VERSION ""

NS_ :

BS_:

BU_: VCM FAS EBS APM

BO_ 592 EBS_CpbtyAxle123_C03: 64 EBS
 SG_ CpbtyAxle3_BrkEgyCpctyQltyLe : 340|2@1+ (1,0) [0|0] ""  VCM
 SG_ CpbtyAxle3_TqCpbtyRateIncLeLe : 360|8@1+ (1000,0) [0|255000] "NotApplicable"  VCM
 SG_ CpbtyAxle3_TqCpbtyRateQltyRi : 438|2@1+ (1,0) [0|0] ""  VCM
 SG_ CpbtyAxle1_PadWearQltyLe : 32|2@1+ (1,0) [0|0] ""  VCM
 SG_ CpbtyAxle1_SlipCtrlEna : 144|2@1+ (1,0) [0|0] ""  VCM
 SG_ CpbtyAxle2_PadWearRi : 232|8@1+ (0.5,0) [0|127.5] "Percent"  VCM
 SG_ CpbtyAxle3_TqCpbtyRateQltyLe : 436|2@1+ (1,0) [0|0] ""  VCM
 SG_ CpbtyAxle1_BrkEgyCpctyQltyRi : 38|2@1+ (1,0) [0|0] ""  VCM
 SG_ CpbtyAxle2_TqCpbtyMaxRi : 274|10@1+ (50,0) [0|51150] "Nm"  VCM
 SG_ CpbtyAxle2_TqCpbtyMinLe : 240|10@1+ (50,0) [0|51150] "Nm"  VCM
 SG_ CpbtyAxle2_BrkEgyCpctyQltyLe : 188|2@1+ (1,0) [0|0] ""  VCM
 SG_ CpbtyAxle2_TqCpbtyRateDecLe : 192|8@1+ (1000,0) [0|255000] "NotApplicable"  VCM
 SG_ CpbtyAxle3_SlipCtrlEna : 448|2@1+ (1,0) [0|0] ""  VCM
 SG_ CpbtyAxle3_TqCpbtyQltyLe : 402|2@1+ (1,0) [0|0] ""  VCM
 SG_ CpbtyAxle3_BrkEgyCpctyRi : 328|8@1+ (150,0) [0|38250] "NotApplicable"  VCM
 SG_ CpbtyAxle1_SqC : 16|8@1+ (1,0) [0|255] "Count"  VCM
 SG_ CpbtyAxle1_TqCpbtyQltyLe : 98|2@1+ (1,0) [0|0] ""  VCM
 SG_ CpbtyAxle2_TqCpbtyRateDecRi : 216|8@1+ (1000,0) [0|255000] "NotApplicable"  VCM
 SG_ CpbtyAxle1_TqCpbtyRateIncLeLe : 56|8@1+ (1000,0) [0|255000] "NotApplicable"  VCM
 SG_ CpbtyAxle3_BrkEgyCpctyQltyRi : 342|2@1+ (1,0) [0|0] ""  VCM
 SG_ CpbtyAxle3_TqCpbtyRateDecLe : 344|8@1+ (1000,0) [0|255000] "NotApplicable"  VCM
 SG_ CpbtyAxle3_TqCpbtyRateDecRi : 368|8@1+ (1000,0) [0|255000] "NotApplicable"  VCM
 SG_ CpbtyAxle1_PadWearRi : 80|8@1+ (0.5,0) [0|127.5] "Percent"  VCM
 SG_ CpbtyAxle2_TqCpbtyMaxLe : 262|10@1+ (50,0) [0|51150] "Nm"  VCM
 SG_ CpbtyAxle3_TqCpbtyQltyRi : 424|2@1+ (1,0) [0|0] ""  VCM
 SG_ CpbtyAxle1_TqCpbtyRateDecLe : 40|8@1+ (1000,0) [0|255000] "NotApplicable"  VCM
 SG_ CpbtyAxle1_BrkEgyCpctyRi : 24|8@1+ (150,0) [0|38250] "NotApplicable"  VCM
 SG_ CpbtyAxle3_TqCpbtyMinLe : 392|10@1+ (50,0) [0|51150] "Nm"  VCM
 SG_ CpbtyAxle3_TqCpbtyMinRi : 404|10@1+ (50,0) [0|51150] "Nm"  VCM
 SG_ CpbtyAxle2_BrkEgyCpctyQltyRi : 190|2@1+ (1,0) [0|0] ""  VCM
 SG_ CpbtyAxle2_PadWearLe : 224|8@1+ (0.5,0) [0|127.5] "Percent"  VCM
 SG_ CpbtyAxle2_TqCpbtyQltyRi : 272|2@1+ (1,0) [0|0] ""  VCM
 SG_ CpbtyAxle2_PadWearQltyRi : 186|2@1+ (1,0) [0|0] ""  VCM
 SG_ CpbtyAxle3_PadWearRi : 384|8@1+ (0.5,0) [0|127.5] "Percent"  VCM
 SG_ CpbtyAxle3_PadWearQltyRi : 338|2@1+ (1,0) [0|0] ""  VCM
 SG_ CpbtyAxle1_TqCpbtyMaxRi : 122|10@1+ (50,0) [0|51150] "Nm"  VCM
 SG_ CpbtyAxle2_TqCpbtyRateQltyRi : 286|2@1+ (1,0) [0|0] ""  VCM
 SG_ CpbtyAxle1_BrkEgyCpctyLe : 136|8@1+ (150,0) [0|38250] "NotApplicable"  VCM
 SG_ CpbtyAxle2_SlipCtrlEna : 296|2@1+ (1,0) [0|0] ""  VCM
 SG_ CpbtyAxle1_TqCpbtyRateIncLeRi : 48|8@1+ (1000,0) [0|255000] "NotApplicable"  VCM
 SG_ CpbtyAxle2_TqCpbtyMinRi : 252|10@1+ (50,0) [0|51150] "Nm"  VCM
 SG_ CpbtyAxle3_TqCpbtyMaxLe : 414|10@1+ (50,0) [0|51150] "Nm"  VCM
 SG_ CpbtyAxle1_TqCpbtyRateQltyRi : 134|2@1+ (1,0) [0|0] ""  VCM
 SG_ CpbtyAxle1_CRC : 0|16@1+ (1,0) [0|65535] "NotApplicable"  VCM
 SG_ CpbtyAxle1_PadWearQltyRi : 34|2@1+ (1,0) [0|0] ""  VCM
 SG_ CpbtyAxle2_CRC : 152|16@1+ (1,0) [0|65535] "NotApplicable"  VCM
 SG_ CpbtyAxle2_SqC : 168|8@1+ (1,0) [0|255] "Count"  VCM
 SG_ CpbtyAxle2_TqCpbtyRateIncLeLe : 208|8@1+ (1000,0) [0|255000] "NotApplicable"  VCM
 SG_ CpbtyAxle2_TqCpbtyRateIncLeRi : 200|8@1+ (1000,0) [0|255000] "NotApplicable"  VCM
 SG_ CpbtyAxle2_BrkEgyCpctyLe : 288|8@1+ (150,0) [0|38250] "NotApplicable"  VCM
 SG_ CpbtyAxle1_TqCpbtyRateDecRi : 64|8@1+ (1000,0) [0|255000] "NotApplicable"  VCM
 SG_ CpbtyAxle3_TqCpbtyMaxRi : 426|10@1+ (50,0) [0|51150] "Nm"  VCM
 SG_ CpbtyAxle3_PadWearQltyLe : 336|2@1+ (1,0) [0|0] ""  VCM
 SG_ CpbtyAxle3_PadWearLe : 376|8@1+ (0.5,0) [0|127.5] "Percent"  VCM
 SG_ CpbtyAxle1_TqCpbtyRateQltyLe : 132|2@1+ (1,0) [0|0] ""  VCM
 SG_ CpbtyAxle1_PadWearLe : 72|8@1+ (0.5,0) [0|127.5] "Percent"  VCM
 SG_ CpbtyAxle1_TqCpbtyMinRi : 100|10@1+ (50,0) [0|51150] "Nm"  VCM
 SG_ CpbtyAxle1_TqCpbtyQltyRi : 120|2@1+ (1,0) [0|0] ""  VCM
 SG_ CpbtyAxle3_BrkEgyCpctyLe : 440|8@1+ (150,0) [0|38250] "NotApplicable"  VCM
 SG_ CpbtyAxle3_TqCpbtyRateIncLeRi : 352|8@1+ (1000,0) [0|255000] "NotApplicable"  VCM
 SG_ CpbtyAxle1_TqCpbtyMinLe : 88|10@1+ (50,0) [0|51150] "Nm"  VCM
 SG_ CpbtyAxle2_TqCpbtyQltyLe : 250|2@1+ (1,0) [0|0] ""  VCM
 SG_ CpbtyAxle2_TqCpbtyRateQltyLe : 284|2@1+ (1,0) [0|0] ""  VCM
 SG_ CpbtyAxle2_BrkEgyCpctyRi : 176|8@1+ (150,0) [0|38250] "NotApplicable"  VCM
 SG_ CpbtyAxle1_BrkEgyCpctyQltyLe : 36|2@1+ (1,0) [0|0] ""  VCM
 SG_ CpbtyAxle2_PadWearQltyLe : 184|2@1+ (1,0) [0|0] ""  VCM
 SG_ CpbtyAxle1_TqCpbtyMaxLe : 110|10@1+ (50,0) [0|51150] "Nm"  VCM
 SG_ CpbtyAxle3_CRC : 304|16@1+ (1,0) [0|65535] "NotApplicable"  VCM
 SG_ CpbtyAxle3_SqC : 320|8@1+ (1,0) [0|255] "Count"  VCM

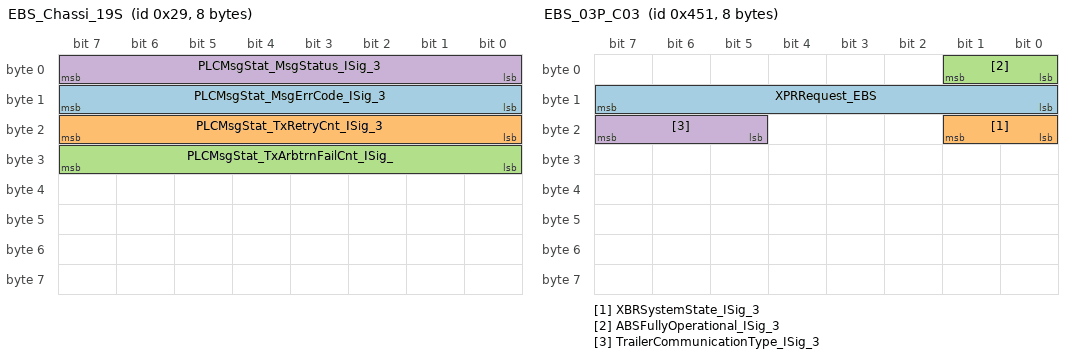
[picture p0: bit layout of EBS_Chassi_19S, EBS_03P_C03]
BO_ 41 EBS_Chassi_19S: 8 EBS
 SG_ PLCMsgStat_MsgErrCode_ISig_3 : 8|8@1+ (1,0) [0|255] "NotApplicable"  VCM
 SG_ PLCMsgStat_TxRetryCnt_ISig_3 : 16|8@1+ (1,0) [0|255] "NotApplicable"  VCM
 SG_ PLCMsgStat_TxArbtrnFailCnt_ISig_ : 24|8@1+ (1,0) [0|255] "NotApplicable"  VCM
 SG_ PLCMsgStat_MsgStatus_ISig_3 : 0|8@1+ (1,0) [0|255] "NotApplicable"  VCM

BO_ 1505 EBS_Chassi_18S: 24 EBS
 SG_ PhyDiagBrk2TPMReqSig_ISig_3 : 0|168@1+ (1,0) [0|0] ""  VCM

BO_ 296 EBS_06P_C03: 8 EBS
 SG_ FrontAxleSpeed_ISig_3 : 0|16@1+ (0.00390625,0) [0|255.99609375] "Km_per_h"  APM

BO_ 832 EBS_05P_C03: 16 EBS
 SG_ WhlSpdSenTothCnt456_TimeStamp_IS : 112|16@1+ (1,0) [0|65535] ""  VCM
 SG_ WhlSpdSenTothCnt456_Axle6Right_I : 104|8@1+ (1,0) [0|255] "Count"  VCM
 SG_ WhlSpdSenTothCnt456_Axle5Left_IS : 80|8@1+ (1,0) [0|255] "Count"  VCM
 SG_ WhlSpdSenTothCnt456_Axle4Right_I : 72|8@1+ (1,0) [0|255] "Count"  VCM
 SG_ WhlSpdSenTothCnt456_Axle5Right_I : 88|8@1+ (1,0) [0|255] "Count"  VCM
 SG_ WhlSpdSenTothCnt123_Axle2Left_IS : 16|8@1+ (1,0) [0|255] "Count"  VCM
 SG_ WhlSpdSenTothCnt123_TimeStamp_IS : 48|16@1+ (1,0) [0|65535] ""  VCM
 SG_ WhlSpdSenTothCnt456_Axle4Left_IS : 64|8@1+ (1,0) [0|255] "Count"  VCM
 SG_ WhlSpdSenTothCnt123_Axle3Left_IS : 32|8@1+ (1,0) [0|255] "Count"  VCM
 SG_ WhlSpdSenTothCnt123_Axle1Right_I : 8|8@1+ (1,0) [0|255] "Count"  VCM
 SG_ WhlSpdSenTothCnt123_Axle3Right_I : 40|8@1+ (1,0) [0|255] "Count"  VCM
 SG_ WhlSpdSenTothCnt456_Axle6Left_IS : 96|8@1+ (1,0) [0|255] "Count"  VCM
 SG_ WhlSpdSenTothCnt123_Axle2Right_I : 24|8@1+ (1,0) [0|255] "Count"  VCM
 SG_ WhlSpdSenTothCnt123_Axle1Left_IS : 0|8@1+ (1,0) [0|255] "Count"  VCM

BO_ 1507 EBS_04P_C03: 8 EBS
 SG_ PLCBusStatus_ISig_3 : 0|8@1+ (1,0) [0|255] "NotApplicable"  VCM

BO_ 1105 EBS_03P_C03: 8 EBS
 SG_ XPRRequest_EBS : 8|8@1+ (1,0) [0|255] "NotApplicable"  VCM
 SG_ XBRSystemState_ISig_3 : 16|2@1+ (1,0) [0|0] ""  VCM,APM
 SG_ ABSFullyOperational_ISig_3 : 0|2@1+ (1,0) [0|0] ""  APM
 SG_ TrailerCommunicationType_ISig_3 : 21|3@1+ (1,0) [0|0] ""  VCM

BO_ 439 EBS_02P_C03: 48 EBS
 SG_ ABSAxle5Active : 152|2@1+ (1,0) [0|0] ""  VCM,APM
 SG_ EACompound_CRC : 0|8@1+ (1,0) [0|255] ""  VCM,APM
 SG_ RrAxle1RtWhlBrakeApplPrsHiRng : 72|8@1+ (5,0) [0|1275] "kPa"  VCM
 SG_ RrAxle3RtWhlBrakeApplPrsHiRng : 104|8@1+ (5,0) [0|1275] "kPa"  VCM
 SG_ Trailer1TractionHelp_ISig_3 : 218|2@1+ (1,0) [0|0] ""  VCM
 SG_ FrAxleRtWhlBrakeApplPrsHiRng : 56|8@1+ (5,0) [0|1275] "kPa"  VCM
 SG_ EBSBrakeSwitch_ISig_3 : 162|2@1+ (1,0) [0|0] ""  APM,VCM
 SG_ EACompound_SystemState : 12|2@1+ (1,0) [0|0] ""  VCM,APM
 SG_ EBSBrakePedalPosition : 176|8@1+ (0.4,0) [0|102] "Percent"  VCM,APM
 SG_ AntiLockBrakingActive_ISig_3 : 154|2@1+ (1,0) [0|0] ""  FAS,APM,VCM
 SG_ StretchBrake_Stat_ISig_3 : 141|3@1+ (1,0) [0|0] ""  VCM
 SG_ HillHolderMode_ISig_3 : 136|3@1+ (1,0) [0|0] ""  VCM,APM
 SG_ ABSAxle4Active : 150|2@1+ (1,0) [0|0] ""  VCM,APM
 SG_ TrailerBrake_Stat_ISig_3 : 172|2@1+ (1,0) [0|0] ""  VCM
 SG_ CombinedWheelSpeed_CRC : 184|8@1+ (1,0) [0|255] ""  VCM,APM
 SG_ ABSAxle2Active : 146|2@1+ (1,0) [0|0] ""  VCM,APM
 SG_ TrailerEBSAmberWarning_ISig_3 : 174|2@1+ (1,0) [0|0] ""  VCM
 SG_ CombinedWheelSpeed_SqC : 192|4@1+ (1,0) [0|14] "NotApplicable"  VCM,APM
 SG_ ABSAxle1Active : 144|2@1+ (1,0) [0|0] ""  VCM,APM
 SG_ RrAxle2LtWhlBrakeApplPrsHiRng : 80|8@1+ (5,0) [0|1275] "kPa"  VCM
 SG_ ABSAxle3Active : 148|2@1+ (1,0) [0|0] ""  VCM,APM
 SG_ TCMSupply_SqC : 32|4@1+ (1,0) [0|14] "NotApplicable"  VCM,APM
 SG_ PusherLiftAxleLoweringInhibit_IS : 170|2@1+ (1,0) [0|0] ""  VCM
 SG_ CombinedWheelSpeed_Quality : 196|3@1+ (1,0) [0|0] ""  VCM,APM
 SG_ SplitBoxDiffLockActvnFuncReq_ISi : 166|2@1+ (1,0) [0|0] ""  VCM
 SG_ SteerableLiftAxleLoweringInhib : 168|2@1+ (1,0) [0|0] ""  VCM
 SG_ RrAxle3LtWhlBrakeApplPrsHiRng : 96|8@1+ (5,0) [0|1275] "kPa"  VCM
 SG_ EACompound_AppliedRatio : 16|8@1+ (0.004,0) [0|1.02] ""  VCM,APM
 SG_ BrakingSystemPressureLim_rqst_IS : 156|2@1+ (1,0) [0|0] ""  VCM
 SG_ RrAxle1LtWhlBrakeApplPrsHiRng : 64|8@1+ (5,0) [0|1275] "kPa"  VCM
 SG_ EACompound_SqC : 8|4@1+ (1,0) [0|14] "NotApplicable"  APM,VCM
 SG_ TCMSupply_CRC : 24|8@1+ (1,0) [0|255] ""  APM,VCM
 SG_ TrailerControlPressure : 128|8@1+ (5,0) [0|1275] "kPa"  VCM
 SG_ RrAxle2RtWhlBrakeApplPrsHiRng : 88|8@1+ (5,0) [0|1275] "kPa"  VCM
 SG_ ScndRrAxlDiffLckActvnFuncReq_ISi : 164|2@1+ (1,0) [0|0] ""  VCM
 SG_ TCMSupply_TrailerPressure : 40|8@1+ (8,0) [0|2040] "kPa"  VCM,APM
 SG_ CombinedWheelSpeed_Speed : 200|16@1+ (0.00390625,0) [0|255.99609375] "Km_per_h"  APM,VCM
 SG_ HSAState : 139|2@1+ (1,0) [0|0] ""  VCM
 SG_ FrAxleLtWhlBrakeApplPrsHiRng : 48|8@1+ (5,0) [0|1275] "kPa"  VCM

BO_ 315 EBS_01P_C03: 20 EBS
 SG_ FrontAxleLeftWheelSpeed_ISig_3 : 80|16@1+ (0.00390625,0) [0|255.99609375] "Km_per_h"  FAS
 SG_ SteeringWheel_AngleCRC : 16|8@1+ (1,0) [0|255] "NotApplicable"  VCM
 SG_ SteeringWheelTurnCounter : 146|6@1+ (1,-32) [-32|31] "turns"  VCM
 SG_ SteeringWheel_AngleCounter : 24|4@1+ (1,0) [0|15] "NotApplicable"  VCM
 SG_ FrontAxleRightWheelSpeed_ISig_3 : 96|16@1+ (0.00390625,0) [0|255.99609375] "Km_per_h"  FAS
 SG_ LateralAcceleration_ISig_3 : 112|16@1+ (0.00048828125,-15.687) [-15.687|16.31251171875] "m_per_s_squared"  VCM
 SG_ SteeringWheelAngleSensorType : 144|2@1+ (1,0) [0|0] ""  VCM
 SG_ BrakeLightActivationRequest_ISig : 28|2@1+ (1,0) [0|0] ""  VCM
 SG_ SteeringWheel_AngleValue : 0|16@1+ (0.0009765625,-31.374) [-31.374|32.6250234375] "rad"  VCM
 SG_ LongitudinalAcceleration_ISig_3 : 128|16@1+ (0.00048828125,-15.687) [-15.687|16.31251171875] "m_per_s_squared"  VCM
 SG_ SteeringWheelAngle_ISig_3 : 32|16@1+ (0.0009765625,-31.374) [-31.374|32.6250234375] "rad"  VCM,FAS
 SG_ SteeringWheelAngleComp : 48|16@1+ (0.0009765625,-31.374) [-31.374|32.6250234375] "rad"  VCM,FAS
 SG_ YawRate_ISig_3 : 64|16@1+ (0.000122,-3.92) [-3.92|4.07527] "Rad_per_s"  FAS,VCM
 SG_ VDCBrakeLightRequest_ISig_3 : 30|2@1+ (1,0) [0|0] ""  VCM

BO_ 2671964720 DiagUUDTRespMsg1_F2_30_C03: 8 FAS
 SG_ DiagUUDTRespSig_F2_30_ISig_3 : 0|64@1+ (1,0) [0|0] ""  VCM

BO_ 2671964707 DiagUUDTRespMsg1_F2_23_C03: 8 APM
 SG_ DiagUUDTRespSig_F2_23_ISig_3 : 0|64@1+ (1,0) [0|0] ""  VCM

BO_ 2671834160 DiagRespMsgForIntTest_F4_30_C03: 8 FAS
 SG_ InternalTesterDiagSig_F4_30 : 0|64@1+ (1,0) [0|0] ""  VCM

BO_ 2671834147 DiagRespMsgForIntTest_F4_23_C03: 8 APM
 SG_ InternalTesterDiagSig_F4_23 : 0|64@1+ (1,0) [0|0] ""  VCM

BO_ 2671784180 DiagReqMsgOfIntTest_30_F4_C03: 8 VCM
 SG_ InternalTesterDiagSig_30_F4 : 0|64@1+ (1,0) [0|0] ""  FAS

BO_ 2671780852 DiagReqMsgOfIntTest_23_F4_C03: 8 VCM
 SG_ InternalTesterDiagSig_23_F4 : 0|64@1+ (1,0) [0|0] ""  APM

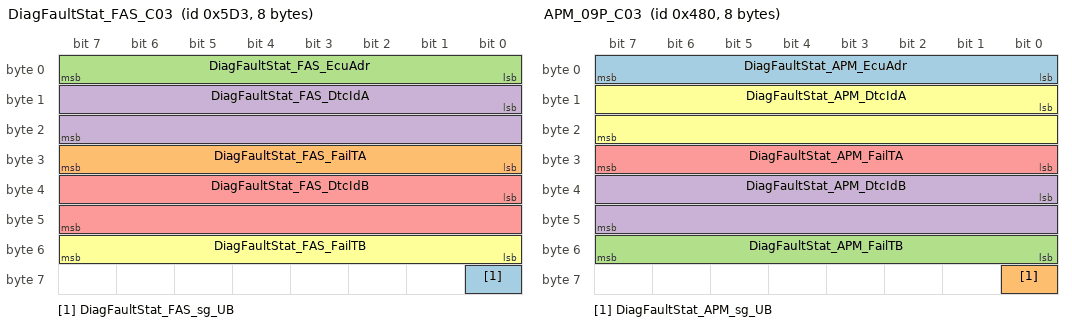
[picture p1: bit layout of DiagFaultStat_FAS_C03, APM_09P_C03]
BO_ 1491 DiagFaultStat_FAS_C03: 8 FAS
 SG_ DiagFaultStat_FAS_sg_UB : 56|1@1+ (1,0) [0|0] ""  VCM
 SG_ DiagFaultStat_FAS_FailTA : 24|8@1+ (1,0) [0|255] ""  VCM
 SG_ DiagFaultStat_FAS_EcuAdr : 0|8@1+ (1,0) [0|255] ""  VCM
 SG_ DiagFaultStat_FAS_DtcIdA : 8|16@1+ (1,0) [0|65535] ""  VCM
 SG_ DiagFaultStat_FAS_DtcIdB : 32|16@1+ (1,0) [0|65535] ""  VCM
 SG_ DiagFaultStat_FAS_FailTB : 48|8@1+ (1,0) [0|255] ""  VCM

BO_ 1954 Debug9_FAS_C03: 8 FAS
 SG_ Debug_9_FAS : 0|64@1+ (1,0) [0|0] "" Vector__XXX

BO_ 1949 Debug8_FAS_C03: 8 Vector__XXX
 SG_ Debug_8_FAS : 0|64@1+ (1,0) [0|0] ""  FAS

BO_ 1944 Debug7_FAS_C03: 8 Vector__XXX
 SG_ Debug_7_FAS : 0|64@1+ (1,0) [0|0] ""  FAS

BO_ 1938 Debug6_FAS_C03: 8 FAS
 SG_ Debug_6_FAS : 0|64@1+ (1,0) [0|0] "" Vector__XXX

BO_ 1930 Debug5_FAS_C03: 8 FAS
 SG_ Debug_5_FAS : 0|64@1+ (1,0) [0|0] "" Vector__XXX

BO_ 1922 Debug4_FAS_C03: 8 FAS
 SG_ Debug_4_FAS : 0|64@1+ (1,0) [0|0] "" Vector__XXX

BO_ 1914 Debug3_FAS_C03: 8 FAS
 SG_ Debug_3_FAS : 0|64@1+ (1,0) [0|0] "" Vector__XXX

BO_ 1906 Debug2_FAS_C03: 8 FAS
 SG_ Debug_2_FAS : 0|64@1+ (1,0) [0|0] "" Vector__XXX

BO_ 1898 Debug1_FAS_C03: 8 Vector__XXX
 SG_ Debug_1_FAS : 0|64@1+ (1,0) [0|0] ""  FAS

BO_ 1959 Debug16_FAS_C03: 8 FAS
 SG_ Debug_16_FAS : 0|64@1+ (1,0) [0|0] "" Vector__XXX

BO_ 1891 Debug15_FAS_C03: 8 FAS
 SG_ Debug_15_FAS : 0|64@1+ (1,0) [0|0] "" Vector__XXX

BO_ 1890 Debug14_FAS_C03: 8 FAS
 SG_ Debug_14_FAS : 0|64@1+ (1,0) [0|0] "" Vector__XXX

BO_ 1889 Debug13_FAS_C03: 8 FAS
 SG_ Debug_13_FAS : 0|64@1+ (1,0) [0|0] "" Vector__XXX

BO_ 1888 Debug12_FAS_C03: 8 FAS
 SG_ Debug_12_FAS : 0|64@1+ (1,0) [0|0] "" Vector__XXX

BO_ 1887 Debug11_FAS_C03: 8 FAS
 SG_ Debug_11_FAS : 0|64@1+ (1,0) [0|0] "" Vector__XXX

BO_ 1886 Debug10_FAS_C03: 8 FAS
 SG_ Debug_10_FAS : 0|64@1+ (1,0) [0|0] "" Vector__XXX

BO_ 2041 DSPTesterRespFAS_C03: 8 FAS
 SG_ DSPTesterRespSigFAS : 0|64@1+ (1,0) [0|0] "" Vector__XXX

BO_ 2047 DSPTesterReqFAS_C03: 8 Vector__XXX
 SG_ DSPTesterReqSigFAS : 0|64@1+ (1,0) [0|0] ""  FAS

BO_ 1703 AnmMsg_VCM_C03: 8 VCM
 SG_ AnmSig_VCM_CAN03 : 0|32@1+ (1,0) [0|0] ""  APM,EBS,FAS

BO_ 1701 AnmMsg_FAS_C03: 8 FAS
 SG_ AnmSig_FAS_CAN03 : 0|32@1+ (1,0) [0|0] ""  EBS,APM,VCM

BO_ 1704 AnmMsg_EBS_C03: 8 EBS
 SG_ AnmSig_EBS_CAN03 : 0|32@1+ (1,0) [0|0] ""  APM,FAS,VCM

BO_ 1702 AnmMsg_APM_C03: 8 APM
 SG_ AnmSig_APM_CAN03 : 0|32@1+ (1,0) [0|0] ""  EBS,VCM,FAS

BO_ 1152 APM_09P_C03: 8 APM
 SG_ DiagFaultStat_APM_EcuAdr : 0|8@1+ (1,0) [0|255] ""  VCM
 SG_ DiagFaultStat_APM_sg_UB : 56|1@1+ (1,0) [0|0] ""  VCM
 SG_ DiagFaultStat_APM_FailTB : 48|8@1+ (1,0) [0|255] ""  VCM
 SG_ DiagFaultStat_APM_DtcIdB : 32|16@1+ (1,0) [0|65535] ""  VCM
 SG_ DiagFaultStat_APM_FailTA : 24|8@1+ (1,0) [0|255] ""  VCM
 SG_ DiagFaultStat_APM_DtcIdA : 8|16@1+ (1,0) [0|65535] ""  VCM

BO_ 1536 APM_08P_C03: 8 APM
 SG_ AirCartridgeWearingPercentage : 0|8@1+ (1,0) [0|255] "Percent"  VCM
 SG_ TotAirVolCurrentAirDryerFilter : 8|10@1+ (100000,0) [0|102300000] "l"  VCM

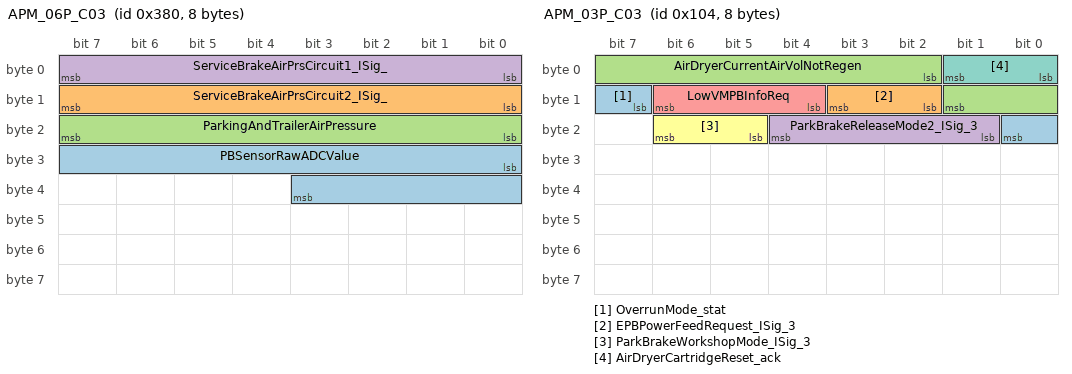
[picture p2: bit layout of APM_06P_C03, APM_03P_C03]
BO_ 896 APM_06P_C03: 8 APM
 SG_ PBSensorRawADCValue : 24|12@1+ (1,0) [0|4095] "NotApplicable"  VCM
 SG_ ServiceBrakeAirPrsCircuit2_ISig_ : 8|8@1+ (8,0) [0|2040] "kPa"  EBS,VCM
 SG_ ParkingAndTrailerAirPressure : 16|8@1+ (8,0) [0|2040] "kPa"  VCM,EBS
 SG_ ServiceBrakeAirPrsCircuit1_ISig_ : 0|8@1+ (8,0) [0|2040] "kPa"  VCM,EBS

BO_ 640 APM_05P_C03: 32 APM
 SG_ APMSafetyWarning_YellowRqst_ISig : 46|2@1+ (1,0) [0|0] ""  VCM
 SG_ TrailerStatus_IntegrityLvl_ISig_ : 120|2@1+ (1,0) [0|0] ""  VCM,EBS
 SG_ PBAirLvl_SqC : 56|4@1+ (1,0) [0|14] "NotApplicable"  VCM,EBS
 SG_ RedGladHand_SqC_ISig_3 : 24|4@1+ (1,0) [0|14] "NotApplicable"  VCM
 SG_ LowAirPressureAlert_ISig_3 : 142|2@1+ (1,0) [0|0] ""  EBS,VCM
 SG_ TrailerStatus_CRC_ISig_3 : 104|8@1+ (1,0) [0|255] ""  VCM,EBS
 SG_ PBPositionLeverCopy : 128|6@1+ (2,0) [0|126] "Percent"  VCM
 SG_ DynamicPB_ActiveStatus : 12|3@1+ (1,0) [0|0] ""  VCM
 SG_ PBStatus_CRC_ISig_3 : 80|8@1+ (1,0) [0|255] ""  EBS,VCM
 SG_ PBAirLvl_AntiCompoundRatio : 64|8@1+ (0.004,0) [0|1.02] ""  VCM,EBS
 SG_ PB2HCUAreaCopy : 181|3@1+ (1,0) [0|0] ""  VCM
 SG_ PBStatus_SqC_ISig_3 : 88|4@1+ (1,0) [0|14] "NotApplicable"  VCM,EBS
 SG_ TrailerStatus_Actuation_ISig_3 : 116|3@1+ (1,0) [0|0] ""  EBS,VCM
 SG_ RedGladHand_ConnectStatus_ISig_3 : 30|2@1+ (1,0) [0|0] ""  VCM
 SG_ PBHCUAreaCopy : 168|3@1+ (1,0) [0|0] ""  VCM
 SG_ PBStatus_IntegrityLvl_ISig_3 : 96|2@1+ (1,0) [0|0] ""  VCM,EBS
 SG_ TrPositionLeverCopy : 144|6@1+ (2,0) [0|126] "Percent"  VCM
 SG_ AutoPBRelease_stat_ISig_3 : 134|2@1+ (1,0) [0|0] ""  VCM
 SG_ APMSafetyWarning_CRC_ISig_3 : 32|8@1+ (1,0) [0|255] ""  VCM
 SG_ TrHCUAreaCopy : 171|3@1+ (1,0) [0|0] ""  VCM
 SG_ DynamicPB_SqC : 8|4@1+ (1,0) [0|14] "NotApplicable"  VCM
 SG_ RedGladHand_CRC_ISig_3 : 16|8@1+ (1,0) [0|255] ""  VCM
 SG_ TrailerSupplyInflationMode : 152|4@1+ (1,0) [0|0] ""  VCM
 SG_ DynamicPB_CRC : 0|8@1+ (1,0) [0|255] ""  VCM
 SG_ TLInflationAcceptance_stat_ISig_ : 178|3@1+ (1,0) [0|0] ""  VCM
 SG_ TrailerInflationPossible_stat_IS : 150|2@1+ (1,0) [0|0] ""  VCM
 SG_ SecondRVAirPressure_Out : 160|8@1+ (8,0) [0|2040] "kPa"  VCM
 SG_ APMSafetyWarning_RedRqst_ISig_3 : 44|2@1+ (1,0) [0|0] ""  VCM
 SG_ PBAirLvl_CRC : 48|8@1+ (1,0) [0|255] ""  EBS,VCM
 SG_ RedGladHand_ConfidenceLvl_ISig_3 : 28|2@1+ (1,0) [0|0] ""  VCM
 SG_ TrailerSupplyDeflationMode : 156|4@1+ (1,0) [0|0] ""  VCM
 SG_ APMSafetyWarning_SqC_ISig_3 : 40|4@1+ (1,0) [0|14] "NotApplicable"  VCM
 SG_ AirProdPressureRangeModeStatus : 174|4@1+ (1,0) [0|0] ""  VCM
 SG_ PB2PositionLeverCopy : 136|6@1+ (2,0) [0|126] "Percent"  VCM
 SG_ PBAirLvl_PressureInChamber : 72|8@1+ (8,0) [0|2040] "kPa"  EBS,VCM
 SG_ PBStatus_Actuation_ISig_3 : 92|3@1+ (1,0) [0|0] ""  VCM,EBS
 SG_ TrailerStatus_SqC_ISig_3 : 112|4@1+ (1,0) [0|14] "NotApplicable"  VCM,EBS

BO_ 386 APM_04P_C03: 16 APM
 SG_ RGHDetect_CRC : 48|8@1+ (1,0) [0|255] ""  VCM
 SG_ ParkBrakeChamberAirPressure : 64|8@1+ (8,0) [0|2040] "kPa"  VCM,EBS
 SG_ XPRGSystemState_AppliedPriority : 44|4@1+ (1,0) [0|0] ""  VCM
 SG_ UnLoaderValveStatus : 92|2@1+ (1,0) [0|0] ""  VCM
 SG_ XPRGSystemCap_SqC_ISig_3 : 8|4@1+ (1,0) [0|14] "NotApplicable"  VCM
 SG_ PBStatusDisplay_cmd_ISig_3 : 86|2@1+ (1,0) [0|0] ""  VCM
 SG_ ParkBrakeApplicationMode2_ISig_3 : 72|4@1+ (1,0) [0|0] ""  EBS,VCM
 SG_ XPRGSystemState_CRC : 32|8@1+ (1,0) [0|255] ""  VCM
 SG_ XPRGSystemCap_AllowedGradCtrlTl_ : 22|1@1+ (1,0) [0|0] ""  VCM
 SG_ XPRGSystemCap_AllowedGradCtrlTc_ : 23|1@1+ (1,0) [0|0] ""  VCM
 SG_ XPRGSystemCap_AllowedRelInhibit_ : 19|3@1+ (1,0) [0|0] ""  VCM
 SG_ ParkBrakeReleasePossible_stat_IS : 88|2@1+ (1,0) [0|0] ""  VCM
 SG_ PBReleaseAcceptance_stat_ISig_3 : 80|3@1+ (1,0) [0|0] ""  VCM
 SG_ AirCompressorStatus_ISig_3 : 76|2@1+ (1,0) [0|0] ""  VCM
 SG_ RGHDetect_SqC : 56|4@1+ (1,0) [0|14] "NotApplicable"  VCM
 SG_ TrailerTest_stat_ISig_3 : 83|3@1+ (1,0) [0|0] ""  VCM
 SG_ XPRGSystemState_SqC : 40|4@1+ (1,0) [0|14] "NotApplicable"  VCM
 SG_ PoorAirPressureInfo_ISig_3 : 90|2@1+ (1,0) [0|0] ""  VCM
 SG_ RGHDetect_ActiveProcess : 60|2@1+ (1,0) [0|0] ""  VCM
 SG_ XPRGSystemCap_Priority_ISig_3 : 12|3@1+ (1,0) [0|0] ""  VCM
 SG_ XPRGSystemCap_AllowedPBApp_ISig_ : 25|1@1+ (1,0) [0|0] ""  VCM
 SG_ XPRGSystemCap_AllowedPBRel_ISig_ : 24|1@1+ (1,0) [0|0] ""  VCM
 SG_ AirProductionRqst : 78|2@1+ (1,0) [0|0] ""  VCM
 SG_ XPRGSystemCap_AllowedDeflation_I : 15|1@1+ (1,0) [0|0] ""  VCM
 SG_ XPRGSystemCap_AllowedInflation_I : 26|1@1+ (1,0) [0|0] ""  VCM
 SG_ EPBHSARequest : 94|3@1+ (1,0) [0|0] ""  EBS,VCM
 SG_ XPRGSystemCap_AllowedInfInhibit_ : 16|3@1+ (1,0) [0|0] ""  VCM
 SG_ XPRGSystemCap_CRC_ISig_3 : 0|8@1+ (1,0) [0|255] ""  VCM

BO_ 260 APM_03P_C03: 8 APM
 SG_ OverrunMode_stat : 15|2@1+ (1,0) [0|0] ""  VCM
 SG_ EPBPowerFeedRequest_ISig_3 : 10|2@1+ (1,0) [0|0] ""  VCM
 SG_ AirDryerCurrentAirVolNotRegen : 2|8@1+ (250,0) [0|63750] "l"  VCM
 SG_ ParkBrakeReleaseMode2_ISig_3 : 17|4@1+ (1,0) [0|0] ""  EBS,VCM
 SG_ LowVMPBInfoReq : 12|3@1+ (1,0) [0|0] ""  EBS,VCM
 SG_ ParkBrakeWorkshopMode_ISig_3 : 21|2@1+ (1,0) [0|0] ""  VCM
 SG_ AirDryerCartridgeReset_ack : 0|2@1+ (1,0) [0|0] ""  VCM

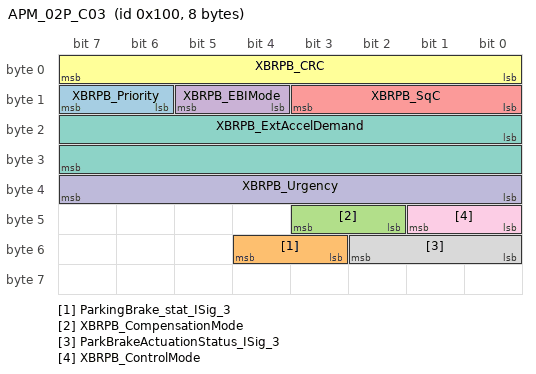
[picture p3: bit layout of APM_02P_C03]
BO_ 256 APM_02P_C03: 8 APM
 SG_ XBRPB_Priority : 14|2@1+ (1,0) [0|0] ""  VCM
 SG_ ParkingBrake_stat_ISig_3 : 51|2@1+ (1,0) [0|0] ""  VCM,FAS,EBS
 SG_ XBRPB_CompensationMode : 42|2@1+ (1,0) [0|0] ""  VCM
 SG_ XBRPB_EBIMode : 12|2@1+ (1,0) [0|0] ""  VCM
 SG_ XBRPB_SqC : 8|4@1+ (1,0) [0|14] "NotApplicable"  VCM
 SG_ XBRPB_CRC : 0|8@1+ (1,0) [0|255] ""  VCM
 SG_ XBRPB_ExtAccelDemand : 16|16@1+ (0.00048828125,-15.687) [-15.687|16.31251171875] "m_per_s_squared"  VCM
 SG_ ParkBrakeActuationStatus_ISig_3 : 48|3@1+ (1,0) [0|0] ""  VCM,EBS
 SG_ XBRPB_ControlMode : 40|2@1+ (1,0) [0|0] ""  VCM
 SG_ XBRPB_Urgency : 32|8@1+ (0.4,0) [0|102] "Percent"  VCM

BO_ 480 APM_01P_C03: 12 APM
 SG_ ECU2VIN_stat : 0|88@1+ (1,0) [0|0] ""  VCM

CM_ BO_ 2041 "This message is used only for supplier production test.";
CM_ BO_ 2047 "This message is used only for supplier production test.";
BA_DEF_ BO_  "GenMsgStartDelayTime" INT 0 0;
BA_DEF_ BO_  "GenMsgDelayTime" INT 0 0;
BA_DEF_ BO_  "GenMsgCycleTime" INT 0 0;
BA_DEF_ BO_  "GenMsgSendType" ENUM  "Cyclic","NotUsed","NotUsed","NotUsed","NotUsed","NotUsed","NotUsed","IfActive","NoMsgSendType","NotUsed";
BA_DEF_ SG_  "GenSigStartValue" INT 0 0;
BA_DEF_ SG_  "GenSigCycleTimeActive" INT 0 0;
BA_DEF_ SG_  "GenSigCycleTime" INT 0 0;
BA_DEF_ SG_  "GenSigSendType" ENUM  "Cyclic","OnWrite","OnWriteWithRepetition","OnChange","OnChangeWithRepetition","IfActive","IfActiveWithRepetition","NoSigSendType","NotUsed","NotUsed","NotUsed","NotUsed","NotUsed";
BA_DEF_ BO_  "VFrameFormat" ENUM  "StandardCAN","ExtendedCAN","reserved","J1939PG","reserved","reserved","reserved","reserved","reserved","reserved","reserved","reserved","reserved","reserved","StandardCAN_FD","ExtendedCAN_FD";
BA_DEF_ SG_  "SigType" ENUM  "Default","Range","RangeSigned","ASCII","Discrete","Control","ReferencePGN","DTC","StringDelimiter","StringLength","StringLengthControl";
BA_DEF_ BO_  "NmAsrMessage" ENUM  "No","Yes";
BA_DEF_ SG_  "NeedsUpdateBit" ENUM  "No","Yes";
BA_DEF_ SG_  "MmAnSignal" ENUM  "No","Yes";
BA_DEF_ SG_  "GenSigMaxLatency" INT 0 65535;
BA_DEF_ SG_  "GenSigILSupport" ENUM  "Yes","No";
BA_DEF_ BO_  "GenMsgILSupport" ENUM  "No","Yes";
BA_DEF_ SG_  "E2EProfile" STRING ;
BA_DEF_ SG_  "E2EDataLength" INT 0 65535;
BA_DEF_ SG_  "E2EDataId" INT 0 65535;
BA_DEF_ BO_  "DiagUUDTResponse" ENUM  "No","Yes";
BA_DEF_ BO_  "DiagState" ENUM  "No","Yes";
BA_DEF_ BO_  "DiagResponse" ENUM  "No","Yes";
BA_DEF_ BO_  "DiagRequest" ENUM  "No","Yes";
BA_DEF_ BO_  "DiagConnection" HEX 0 65535;
BA_DEF_ BO_  "CanTpFcFrameId" HEX 0 2147483647;
BA_DEF_ BO_  "CanTpBs" INT 0 255;
BA_DEF_ BO_  "CANFD_BRS" ENUM  "0","1";
BA_DEF_ SG_  "SystemSignalLongSymbol" STRING ;
BA_DEF_REL_ BU_SG_REL_  "GenSigTimeoutTime" INT 0 65535;
BA_DEF_REL_ BU_SG_REL_  "GenSigFirstTimeoutTime" INT 0 65535;
BA_DEF_DEF_  "GenMsgStartDelayTime" 0;
BA_DEF_DEF_  "GenMsgDelayTime" 0;
BA_DEF_DEF_  "GenMsgCycleTime" 0;
BA_DEF_DEF_  "GenMsgSendType" "Cyclic";
BA_DEF_DEF_  "GenSigStartValue" 0;
BA_DEF_DEF_  "GenSigCycleTimeActive" 0;
BA_DEF_DEF_  "GenSigCycleTime" 0;
BA_DEF_DEF_  "GenSigSendType" "Cyclic";
BA_DEF_DEF_  "VFrameFormat" "ExtendedCAN";
BA_DEF_DEF_  "SigType" "Default";
BA_DEF_DEF_  "NmAsrMessage" "No";
BA_DEF_DEF_  "NeedsUpdateBit" "No";
BA_DEF_DEF_  "MmAnSignal" "No";
BA_DEF_DEF_  "GenSigMaxLatency" 0;
BA_DEF_DEF_  "GenSigILSupport" "Yes";
BA_DEF_DEF_  "GenMsgILSupport" "Yes";
BA_DEF_DEF_  "E2EProfile" "none";
BA_DEF_DEF_  "E2EDataLength" 0;
BA_DEF_DEF_  "E2EDataId" 0;
BA_DEF_DEF_  "DiagUUDTResponse" "No";
BA_DEF_DEF_  "DiagState" "No";
BA_DEF_DEF_  "DiagResponse" "No";
BA_DEF_DEF_  "DiagRequest" "No";
BA_DEF_DEF_  "DiagConnection" 0;
BA_DEF_DEF_  "CanTpFcFrameId" 2147483647;
BA_DEF_DEF_  "CanTpBs" 255;
BA_DEF_DEF_  "CANFD_BRS" "0";
BA_DEF_DEF_REL_ "GenSigTimeoutTime" 0;
BA_DEF_DEF_REL_ "GenSigFirstTimeoutTime" 0;
BA_DEF_DEF_  "SystemSignalLongSymbol" "";
BA_ "CANFD_BRS" BO_ 592 1;
BA_ "GenMsgCycleTime" BO_ 592 50;
BA_ "GenMsgStartDelayTime" BO_ 592 5;
BA_ "VFrameFormat" BO_ 592 14;
BA_ "CANFD_BRS" BO_ 41 1;
BA_ "GenMsgSendType" BO_ 41 8;
BA_ "GenMsgStartDelayTime" BO_ 41 50;
BA_ "VFrameFormat" BO_ 41 14;
BA_ "CANFD_BRS" BO_ 1505 1;
BA_ "GenMsgSendType" BO_ 1505 8;
BA_ "VFrameFormat" BO_ 1505 14;
BA_ "CANFD_BRS" BO_ 296 1;
BA_ "GenMsgCycleTime" BO_ 296 30;
BA_ "VFrameFormat" BO_ 296 14;
BA_ "CANFD_BRS" BO_ 832 1;
BA_ "GenMsgCycleTime" BO_ 832 50;
BA_ "GenMsgStartDelayTime" BO_ 832 50;
BA_ "VFrameFormat" BO_ 832 14;
BA_ "CANFD_BRS" BO_ 1507 1;
BA_ "GenMsgCycleTime" BO_ 1507 1000;
BA_ "GenMsgStartDelayTime" BO_ 1507 100;
BA_ "VFrameFormat" BO_ 1507 14;
BA_ "CANFD_BRS" BO_ 1105 1;
BA_ "GenMsgCycleTime" BO_ 1105 100;
BA_ "GenMsgStartDelayTime" BO_ 1105 35;
BA_ "VFrameFormat" BO_ 1105 14;
BA_ "CANFD_BRS" BO_ 439 1;
BA_ "GenMsgCycleTime" BO_ 439 20;
BA_ "GenMsgStartDelayTime" BO_ 439 5;
BA_ "VFrameFormat" BO_ 439 14;
BA_ "CANFD_BRS" BO_ 315 1;
BA_ "GenMsgCycleTime" BO_ 315 10;
BA_ "GenMsgStartDelayTime" BO_ 315 5;
BA_ "VFrameFormat" BO_ 315 14;
BA_ "DiagConnection" BO_ 2671964720 62000;
BA_ "DiagUUDTResponse" BO_ 2671964720 1;
BA_ "GenMsgILSupport" BO_ 2671964720 0;
BA_ "GenMsgSendType" BO_ 2671964720 8;
BA_ "DiagConnection" BO_ 2671964707 61987;
BA_ "DiagUUDTResponse" BO_ 2671964707 1;
BA_ "GenMsgILSupport" BO_ 2671964707 0;
BA_ "GenMsgSendType" BO_ 2671964707 8;
BA_ "DiagConnection" BO_ 2671834160 62512;
BA_ "DiagResponse" BO_ 2671834160 1;
BA_ "GenMsgILSupport" BO_ 2671834160 0;
BA_ "GenMsgSendType" BO_ 2671834160 8;
BA_ "DiagConnection" BO_ 2671834147 62499;
BA_ "DiagResponse" BO_ 2671834147 1;
BA_ "GenMsgILSupport" BO_ 2671834147 0;
BA_ "GenMsgSendType" BO_ 2671834147 8;
BA_ "DiagConnection" BO_ 2671784180 62512;
BA_ "DiagRequest" BO_ 2671784180 1;
BA_ "GenMsgILSupport" BO_ 2671784180 0;
BA_ "GenMsgSendType" BO_ 2671784180 8;
BA_ "DiagConnection" BO_ 2671780852 62499;
BA_ "DiagRequest" BO_ 2671780852 1;
BA_ "GenMsgILSupport" BO_ 2671780852 0;
BA_ "GenMsgSendType" BO_ 2671780852 8;
BA_ "CANFD_BRS" BO_ 1491 1;
BA_ "GenMsgCycleTime" BO_ 1491 1000;
BA_ "GenMsgDelayTime" BO_ 1491 90;
BA_ "VFrameFormat" BO_ 1491 14;
BA_ "CANFD_BRS" BO_ 1954 1;
BA_ "GenMsgSendType" BO_ 1954 8;
BA_ "VFrameFormat" BO_ 1954 14;
BA_ "CANFD_BRS" BO_ 1949 1;
BA_ "VFrameFormat" BO_ 1949 14;
BA_ "CANFD_BRS" BO_ 1944 1;
BA_ "VFrameFormat" BO_ 1944 14;
BA_ "CANFD_BRS" BO_ 1938 1;
BA_ "GenMsgSendType" BO_ 1938 8;
BA_ "GenMsgDelayTime" BO_ 1938 50;
BA_ "VFrameFormat" BO_ 1938 14;
BA_ "CANFD_BRS" BO_ 1930 1;
BA_ "GenMsgSendType" BO_ 1930 8;
BA_ "VFrameFormat" BO_ 1930 14;
BA_ "CANFD_BRS" BO_ 1922 1;
BA_ "GenMsgSendType" BO_ 1922 8;
BA_ "VFrameFormat" BO_ 1922 14;
BA_ "CANFD_BRS" BO_ 1914 1;
BA_ "GenMsgSendType" BO_ 1914 8;
BA_ "VFrameFormat" BO_ 1914 14;
BA_ "CANFD_BRS" BO_ 1906 1;
BA_ "GenMsgSendType" BO_ 1906 8;
BA_ "VFrameFormat" BO_ 1906 14;
BA_ "CANFD_BRS" BO_ 1898 1;
BA_ "VFrameFormat" BO_ 1898 14;
BA_ "CANFD_BRS" BO_ 1959 1;
BA_ "GenMsgSendType" BO_ 1959 8;
BA_ "VFrameFormat" BO_ 1959 14;
BA_ "CANFD_BRS" BO_ 1891 1;
BA_ "GenMsgSendType" BO_ 1891 8;
BA_ "VFrameFormat" BO_ 1891 14;
BA_ "CANFD_BRS" BO_ 1890 1;
BA_ "GenMsgSendType" BO_ 1890 8;
BA_ "VFrameFormat" BO_ 1890 14;
BA_ "CANFD_BRS" BO_ 1889 1;
BA_ "GenMsgSendType" BO_ 1889 8;
BA_ "VFrameFormat" BO_ 1889 14;
BA_ "CANFD_BRS" BO_ 1888 1;
BA_ "GenMsgSendType" BO_ 1888 8;
BA_ "VFrameFormat" BO_ 1888 14;
BA_ "CANFD_BRS" BO_ 1887 1;
BA_ "GenMsgSendType" BO_ 1887 8;
BA_ "VFrameFormat" BO_ 1887 14;
BA_ "CANFD_BRS" BO_ 1886 1;
BA_ "GenMsgSendType" BO_ 1886 8;
BA_ "GenMsgStartDelayTime" BO_ 1886 50;
BA_ "VFrameFormat" BO_ 1886 14;
BA_ "VFrameFormat" BO_ 2041 0;
BA_ "GenMsgSendType" BO_ 2041 8;
BA_ "GenMsgDelayTime" BO_ 2041 50;
BA_ "VFrameFormat" BO_ 2047 0;
BA_ "CANFD_BRS" BO_ 1703 1;
BA_ "GenMsgCycleTime" BO_ 1703 100;
BA_ "VFrameFormat" BO_ 1703 14;
BA_ "CANFD_BRS" BO_ 1701 1;
BA_ "GenMsgCycleTime" BO_ 1701 100;
BA_ "GenMsgStartDelayTime" BO_ 1701 15;
BA_ "VFrameFormat" BO_ 1701 14;
BA_ "CANFD_BRS" BO_ 1704 1;
BA_ "GenMsgCycleTime" BO_ 1704 100;
BA_ "VFrameFormat" BO_ 1704 14;
BA_ "CANFD_BRS" BO_ 1702 1;
BA_ "GenMsgCycleTime" BO_ 1702 100;
BA_ "VFrameFormat" BO_ 1702 14;
BA_ "CANFD_BRS" BO_ 1152 1;
BA_ "GenMsgCycleTime" BO_ 1152 1000;
BA_ "GenMsgStartDelayTime" BO_ 1152 120;
BA_ "VFrameFormat" BO_ 1152 14;
BA_ "CANFD_BRS" BO_ 1536 1;
BA_ "GenMsgCycleTime" BO_ 1536 2000;
BA_ "GenMsgStartDelayTime" BO_ 1536 165;
BA_ "VFrameFormat" BO_ 1536 14;
BA_ "CANFD_BRS" BO_ 896 1;
BA_ "GenMsgCycleTime" BO_ 896 250;
BA_ "GenMsgStartDelayTime" BO_ 896 50;
BA_ "VFrameFormat" BO_ 896 14;
BA_ "CANFD_BRS" BO_ 640 1;
BA_ "GenMsgCycleTime" BO_ 640 100;
BA_ "GenMsgStartDelayTime" BO_ 640 25;
BA_ "VFrameFormat" BO_ 640 14;
BA_ "CANFD_BRS" BO_ 386 1;
BA_ "GenMsgCycleTime" BO_ 386 50;
BA_ "GenMsgStartDelayTime" BO_ 386 15;
BA_ "VFrameFormat" BO_ 386 14;
BA_ "CANFD_BRS" BO_ 260 1;
BA_ "GenMsgCycleTime" BO_ 260 30;
BA_ "GenMsgStartDelayTime" BO_ 260 10;
BA_ "VFrameFormat" BO_ 260 14;
BA_ "CANFD_BRS" BO_ 256 1;
BA_ "GenMsgCycleTime" BO_ 256 20;
BA_ "GenMsgStartDelayTime" BO_ 256 5;
BA_ "VFrameFormat" BO_ 256 14;
BA_ "CANFD_BRS" BO_ 480 1;
BA_ "GenMsgSendType" BO_ 480 8;
BA_ "VFrameFormat" BO_ 480 14;
BA_ "GenSigCycleTime" SG_ 592 CpbtyAxle3_BrkEgyCpctyQltyLe 100;
BA_ "GenSigCycleTimeActive" SG_ 592 CpbtyAxle3_BrkEgyCpctyQltyLe 100;
BA_ "GenSigStartValue" SG_ 592 CpbtyAxle3_BrkEgyCpctyQltyLe 3;
BA_ "GenSigCycleTime" SG_ 592 CpbtyAxle3_TqCpbtyRateIncLeLe 100;
BA_ "GenSigCycleTimeActive" SG_ 592 CpbtyAxle3_TqCpbtyRateIncLeLe 100;
BA_ "GenSigStartValue" SG_ 592 CpbtyAxle3_TqCpbtyRateIncLeLe 255;
BA_ "GenSigCycleTime" SG_ 592 CpbtyAxle3_TqCpbtyRateQltyRi 100;
BA_ "GenSigCycleTimeActive" SG_ 592 CpbtyAxle3_TqCpbtyRateQltyRi 100;
BA_ "GenSigStartValue" SG_ 592 CpbtyAxle3_TqCpbtyRateQltyRi 3;
BA_ "GenSigCycleTime" SG_ 592 CpbtyAxle1_PadWearQltyLe 100;
BA_ "GenSigCycleTimeActive" SG_ 592 CpbtyAxle1_PadWearQltyLe 100;
BA_ "GenSigStartValue" SG_ 592 CpbtyAxle1_PadWearQltyLe 3;
BA_ "GenSigCycleTime" SG_ 592 CpbtyAxle1_SlipCtrlEna 100;
BA_ "GenSigCycleTimeActive" SG_ 592 CpbtyAxle1_SlipCtrlEna 100;
BA_ "GenSigStartValue" SG_ 592 CpbtyAxle1_SlipCtrlEna 3;
BA_ "GenSigCycleTime" SG_ 592 CpbtyAxle2_PadWearRi 100;
BA_ "GenSigCycleTimeActive" SG_ 592 CpbtyAxle2_PadWearRi 100;
BA_ "GenSigStartValue" SG_ 592 CpbtyAxle2_PadWearRi 255;
BA_ "GenSigCycleTime" SG_ 592 CpbtyAxle3_TqCpbtyRateQltyLe 100;
BA_ "GenSigCycleTimeActive" SG_ 592 CpbtyAxle3_TqCpbtyRateQltyLe 100;
BA_ "GenSigStartValue" SG_ 592 CpbtyAxle3_TqCpbtyRateQltyLe 3;
BA_ "GenSigCycleTime" SG_ 592 CpbtyAxle1_BrkEgyCpctyQltyRi 100;
BA_ "GenSigCycleTimeActive" SG_ 592 CpbtyAxle1_BrkEgyCpctyQltyRi 100;
BA_ "GenSigStartValue" SG_ 592 CpbtyAxle1_BrkEgyCpctyQltyRi 3;
BA_ "GenSigCycleTime" SG_ 592 CpbtyAxle2_TqCpbtyMaxRi 100;
BA_ "GenSigCycleTimeActive" SG_ 592 CpbtyAxle2_TqCpbtyMaxRi 100;
BA_ "GenSigStartValue" SG_ 592 CpbtyAxle2_TqCpbtyMaxRi 1023;
BA_ "GenSigCycleTime" SG_ 592 CpbtyAxle2_TqCpbtyMinLe 100;
BA_ "GenSigCycleTimeActive" SG_ 592 CpbtyAxle2_TqCpbtyMinLe 100;
BA_ "GenSigStartValue" SG_ 592 CpbtyAxle2_TqCpbtyMinLe 1023;
BA_ "GenSigCycleTime" SG_ 592 CpbtyAxle2_BrkEgyCpctyQltyLe 100;
BA_ "GenSigCycleTimeActive" SG_ 592 CpbtyAxle2_BrkEgyCpctyQltyLe 100;
BA_ "GenSigStartValue" SG_ 592 CpbtyAxle2_BrkEgyCpctyQltyLe 3;
BA_ "GenSigCycleTime" SG_ 592 CpbtyAxle2_TqCpbtyRateDecLe 100;
BA_ "GenSigCycleTimeActive" SG_ 592 CpbtyAxle2_TqCpbtyRateDecLe 100;
BA_ "GenSigStartValue" SG_ 592 CpbtyAxle2_TqCpbtyRateDecLe 255;
BA_ "GenSigCycleTime" SG_ 592 CpbtyAxle3_SlipCtrlEna 100;
BA_ "GenSigCycleTimeActive" SG_ 592 CpbtyAxle3_SlipCtrlEna 100;
BA_ "GenSigStartValue" SG_ 592 CpbtyAxle3_SlipCtrlEna 3;
BA_ "GenSigCycleTime" SG_ 592 CpbtyAxle3_TqCpbtyQltyLe 100;
BA_ "GenSigCycleTimeActive" SG_ 592 CpbtyAxle3_TqCpbtyQltyLe 100;
BA_ "GenSigStartValue" SG_ 592 CpbtyAxle3_TqCpbtyQltyLe 3;
BA_ "GenSigCycleTime" SG_ 592 CpbtyAxle3_BrkEgyCpctyRi 100;
BA_ "GenSigCycleTimeActive" SG_ 592 CpbtyAxle3_BrkEgyCpctyRi 100;
BA_ "GenSigStartValue" SG_ 592 CpbtyAxle3_BrkEgyCpctyRi 255;
BA_ "GenSigCycleTime" SG_ 592 CpbtyAxle1_SqC 100;
BA_ "GenSigCycleTimeActive" SG_ 592 CpbtyAxle1_SqC 100;
BA_ "GenSigStartValue" SG_ 592 CpbtyAxle1_SqC 255;
BA_ "GenSigCycleTime" SG_ 592 CpbtyAxle1_TqCpbtyQltyLe 100;
BA_ "GenSigCycleTimeActive" SG_ 592 CpbtyAxle1_TqCpbtyQltyLe 100;
BA_ "GenSigStartValue" SG_ 592 CpbtyAxle1_TqCpbtyQltyLe 3;
BA_ "GenSigCycleTime" SG_ 592 CpbtyAxle2_TqCpbtyRateDecRi 100;
BA_ "GenSigCycleTimeActive" SG_ 592 CpbtyAxle2_TqCpbtyRateDecRi 100;
BA_ "GenSigStartValue" SG_ 592 CpbtyAxle2_TqCpbtyRateDecRi 255;
BA_ "GenSigCycleTime" SG_ 592 CpbtyAxle1_TqCpbtyRateIncLeLe 100;
BA_ "GenSigCycleTimeActive" SG_ 592 CpbtyAxle1_TqCpbtyRateIncLeLe 100;
BA_ "GenSigStartValue" SG_ 592 CpbtyAxle1_TqCpbtyRateIncLeLe 255;
BA_ "GenSigCycleTime" SG_ 592 CpbtyAxle3_BrkEgyCpctyQltyRi 100;
BA_ "GenSigCycleTimeActive" SG_ 592 CpbtyAxle3_BrkEgyCpctyQltyRi 100;
BA_ "GenSigStartValue" SG_ 592 CpbtyAxle3_BrkEgyCpctyQltyRi 3;
BA_ "GenSigCycleTime" SG_ 592 CpbtyAxle3_TqCpbtyRateDecLe 100;
BA_ "GenSigCycleTimeActive" SG_ 592 CpbtyAxle3_TqCpbtyRateDecLe 100;
BA_ "GenSigStartValue" SG_ 592 CpbtyAxle3_TqCpbtyRateDecLe 255;
BA_ "GenSigCycleTime" SG_ 592 CpbtyAxle3_TqCpbtyRateDecRi 100;
BA_ "GenSigCycleTimeActive" SG_ 592 CpbtyAxle3_TqCpbtyRateDecRi 100;
BA_ "GenSigStartValue" SG_ 592 CpbtyAxle3_TqCpbtyRateDecRi 255;
BA_ "GenSigCycleTime" SG_ 592 CpbtyAxle1_PadWearRi 100;
BA_ "GenSigCycleTimeActive" SG_ 592 CpbtyAxle1_PadWearRi 100;
BA_ "GenSigStartValue" SG_ 592 CpbtyAxle1_PadWearRi 255;
BA_ "GenSigCycleTime" SG_ 592 CpbtyAxle2_TqCpbtyMaxLe 100;
BA_ "GenSigCycleTimeActive" SG_ 592 CpbtyAxle2_TqCpbtyMaxLe 100;
BA_ "GenSigStartValue" SG_ 592 CpbtyAxle2_TqCpbtyMaxLe 1023;
BA_ "GenSigCycleTime" SG_ 592 CpbtyAxle3_TqCpbtyQltyRi 100;
BA_ "GenSigCycleTimeActive" SG_ 592 CpbtyAxle3_TqCpbtyQltyRi 100;
BA_ "GenSigStartValue" SG_ 592 CpbtyAxle3_TqCpbtyQltyRi 3;
BA_ "GenSigCycleTime" SG_ 592 CpbtyAxle1_TqCpbtyRateDecLe 100;
BA_ "GenSigCycleTimeActive" SG_ 592 CpbtyAxle1_TqCpbtyRateDecLe 100;
BA_ "GenSigStartValue" SG_ 592 CpbtyAxle1_TqCpbtyRateDecLe 255;
BA_ "GenSigCycleTime" SG_ 592 CpbtyAxle1_BrkEgyCpctyRi 100;
BA_ "GenSigCycleTimeActive" SG_ 592 CpbtyAxle1_BrkEgyCpctyRi 100;
BA_ "GenSigStartValue" SG_ 592 CpbtyAxle1_BrkEgyCpctyRi 255;
BA_ "GenSigCycleTime" SG_ 592 CpbtyAxle3_TqCpbtyMinLe 100;
BA_ "GenSigCycleTimeActive" SG_ 592 CpbtyAxle3_TqCpbtyMinLe 100;
BA_ "GenSigStartValue" SG_ 592 CpbtyAxle3_TqCpbtyMinLe 1023;
BA_ "GenSigCycleTime" SG_ 592 CpbtyAxle3_TqCpbtyMinRi 100;
BA_ "GenSigCycleTimeActive" SG_ 592 CpbtyAxle3_TqCpbtyMinRi 100;
BA_ "GenSigStartValue" SG_ 592 CpbtyAxle3_TqCpbtyMinRi 1023;
BA_ "GenSigCycleTime" SG_ 592 CpbtyAxle2_BrkEgyCpctyQltyRi 100;
BA_ "GenSigCycleTimeActive" SG_ 592 CpbtyAxle2_BrkEgyCpctyQltyRi 100;
BA_ "GenSigStartValue" SG_ 592 CpbtyAxle2_BrkEgyCpctyQltyRi 3;
BA_ "GenSigCycleTime" SG_ 592 CpbtyAxle2_PadWearLe 100;
BA_ "GenSigCycleTimeActive" SG_ 592 CpbtyAxle2_PadWearLe 100;
BA_ "GenSigStartValue" SG_ 592 CpbtyAxle2_PadWearLe 255;
BA_ "GenSigCycleTime" SG_ 592 CpbtyAxle2_TqCpbtyQltyRi 100;
BA_ "GenSigCycleTimeActive" SG_ 592 CpbtyAxle2_TqCpbtyQltyRi 100;
BA_ "GenSigStartValue" SG_ 592 CpbtyAxle2_TqCpbtyQltyRi 3;
BA_ "GenSigCycleTime" SG_ 592 CpbtyAxle2_PadWearQltyRi 100;
BA_ "GenSigCycleTimeActive" SG_ 592 CpbtyAxle2_PadWearQltyRi 100;
BA_ "GenSigStartValue" SG_ 592 CpbtyAxle2_PadWearQltyRi 3;
BA_ "GenSigCycleTime" SG_ 592 CpbtyAxle3_PadWearRi 100;
BA_ "GenSigCycleTimeActive" SG_ 592 CpbtyAxle3_PadWearRi 100;
BA_ "GenSigStartValue" SG_ 592 CpbtyAxle3_PadWearRi 255;
BA_ "GenSigCycleTime" SG_ 592 CpbtyAxle3_PadWearQltyRi 100;
BA_ "GenSigCycleTimeActive" SG_ 592 CpbtyAxle3_PadWearQltyRi 100;
BA_ "GenSigStartValue" SG_ 592 CpbtyAxle3_PadWearQltyRi 3;
BA_ "GenSigCycleTime" SG_ 592 CpbtyAxle1_TqCpbtyMaxRi 100;
BA_ "GenSigCycleTimeActive" SG_ 592 CpbtyAxle1_TqCpbtyMaxRi 100;
BA_ "GenSigStartValue" SG_ 592 CpbtyAxle1_TqCpbtyMaxRi 1023;
BA_ "GenSigCycleTime" SG_ 592 CpbtyAxle2_TqCpbtyRateQltyRi 100;
BA_ "GenSigCycleTimeActive" SG_ 592 CpbtyAxle2_TqCpbtyRateQltyRi 100;
BA_ "GenSigStartValue" SG_ 592 CpbtyAxle2_TqCpbtyRateQltyRi 3;
BA_ "GenSigCycleTime" SG_ 592 CpbtyAxle1_BrkEgyCpctyLe 100;
BA_ "GenSigCycleTimeActive" SG_ 592 CpbtyAxle1_BrkEgyCpctyLe 100;
BA_ "GenSigStartValue" SG_ 592 CpbtyAxle1_BrkEgyCpctyLe 255;
BA_ "GenSigCycleTime" SG_ 592 CpbtyAxle2_SlipCtrlEna 100;
BA_ "GenSigCycleTimeActive" SG_ 592 CpbtyAxle2_SlipCtrlEna 100;
BA_ "GenSigStartValue" SG_ 592 CpbtyAxle2_SlipCtrlEna 3;
BA_ "GenSigCycleTime" SG_ 592 CpbtyAxle1_TqCpbtyRateIncLeRi 100;
BA_ "GenSigCycleTimeActive" SG_ 592 CpbtyAxle1_TqCpbtyRateIncLeRi 100;
BA_ "GenSigStartValue" SG_ 592 CpbtyAxle1_TqCpbtyRateIncLeRi 255;
BA_ "GenSigCycleTime" SG_ 592 CpbtyAxle2_TqCpbtyMinRi 100;
BA_ "GenSigCycleTimeActive" SG_ 592 CpbtyAxle2_TqCpbtyMinRi 100;
BA_ "GenSigStartValue" SG_ 592 CpbtyAxle2_TqCpbtyMinRi 1023;
BA_ "GenSigCycleTime" SG_ 592 CpbtyAxle3_TqCpbtyMaxLe 100;
BA_ "GenSigCycleTimeActive" SG_ 592 CpbtyAxle3_TqCpbtyMaxLe 100;
BA_ "GenSigStartValue" SG_ 592 CpbtyAxle3_TqCpbtyMaxLe 1023;
BA_ "GenSigCycleTime" SG_ 592 CpbtyAxle1_TqCpbtyRateQltyRi 100;
BA_ "GenSigCycleTimeActive" SG_ 592 CpbtyAxle1_TqCpbtyRateQltyRi 100;
BA_ "GenSigStartValue" SG_ 592 CpbtyAxle1_TqCpbtyRateQltyRi 3;
BA_ "GenSigCycleTime" SG_ 592 CpbtyAxle1_CRC 100;
BA_ "GenSigCycleTimeActive" SG_ 592 CpbtyAxle1_CRC 100;
BA_ "GenSigStartValue" SG_ 592 CpbtyAxle1_CRC 65535;
BA_ "E2EDataId" SG_ 592 CpbtyAxle1_CRC 189;
BA_ "E2EDataLength" SG_ 592 CpbtyAxle1_CRC 152;
BA_ "E2EProfile" SG_ 592 CpbtyAxle1_CRC "P05";
BA_ "GenSigCycleTime" SG_ 592 CpbtyAxle1_PadWearQltyRi 100;
BA_ "GenSigCycleTimeActive" SG_ 592 CpbtyAxle1_PadWearQltyRi 100;
BA_ "GenSigStartValue" SG_ 592 CpbtyAxle1_PadWearQltyRi 3;
BA_ "GenSigCycleTime" SG_ 592 CpbtyAxle2_CRC 100;
BA_ "GenSigCycleTimeActive" SG_ 592 CpbtyAxle2_CRC 100;
BA_ "GenSigStartValue" SG_ 592 CpbtyAxle2_CRC 65535;
BA_ "E2EDataId" SG_ 592 CpbtyAxle2_CRC 190;
BA_ "E2EDataLength" SG_ 592 CpbtyAxle2_CRC 152;
BA_ "E2EProfile" SG_ 592 CpbtyAxle2_CRC "P05";
BA_ "GenSigCycleTime" SG_ 592 CpbtyAxle2_SqC 100;
BA_ "GenSigCycleTimeActive" SG_ 592 CpbtyAxle2_SqC 100;
BA_ "GenSigStartValue" SG_ 592 CpbtyAxle2_SqC 255;
BA_ "GenSigCycleTime" SG_ 592 CpbtyAxle2_TqCpbtyRateIncLeLe 100;
BA_ "GenSigCycleTimeActive" SG_ 592 CpbtyAxle2_TqCpbtyRateIncLeLe 100;
BA_ "GenSigStartValue" SG_ 592 CpbtyAxle2_TqCpbtyRateIncLeLe 255;
BA_ "GenSigCycleTime" SG_ 592 CpbtyAxle2_TqCpbtyRateIncLeRi 100;
BA_ "GenSigCycleTimeActive" SG_ 592 CpbtyAxle2_TqCpbtyRateIncLeRi 100;
BA_ "GenSigStartValue" SG_ 592 CpbtyAxle2_TqCpbtyRateIncLeRi 255;
BA_ "GenSigCycleTime" SG_ 592 CpbtyAxle2_BrkEgyCpctyLe 100;
BA_ "GenSigCycleTimeActive" SG_ 592 CpbtyAxle2_BrkEgyCpctyLe 100;
BA_ "GenSigStartValue" SG_ 592 CpbtyAxle2_BrkEgyCpctyLe 255;
BA_ "GenSigCycleTime" SG_ 592 CpbtyAxle1_TqCpbtyRateDecRi 100;
BA_ "GenSigCycleTimeActive" SG_ 592 CpbtyAxle1_TqCpbtyRateDecRi 100;
BA_ "GenSigStartValue" SG_ 592 CpbtyAxle1_TqCpbtyRateDecRi 255;
BA_ "GenSigCycleTime" SG_ 592 CpbtyAxle3_TqCpbtyMaxRi 100;
BA_ "GenSigCycleTimeActive" SG_ 592 CpbtyAxle3_TqCpbtyMaxRi 100;
BA_ "GenSigStartValue" SG_ 592 CpbtyAxle3_TqCpbtyMaxRi 1023;
BA_ "GenSigCycleTime" SG_ 592 CpbtyAxle3_PadWearQltyLe 100;
BA_ "GenSigCycleTimeActive" SG_ 592 CpbtyAxle3_PadWearQltyLe 100;
BA_ "GenSigStartValue" SG_ 592 CpbtyAxle3_PadWearQltyLe 3;
BA_ "GenSigCycleTime" SG_ 592 CpbtyAxle3_PadWearLe 100;
BA_ "GenSigCycleTimeActive" SG_ 592 CpbtyAxle3_PadWearLe 100;
BA_ "GenSigStartValue" SG_ 592 CpbtyAxle3_PadWearLe 255;
BA_ "GenSigCycleTime" SG_ 592 CpbtyAxle1_TqCpbtyRateQltyLe 100;
BA_ "GenSigCycleTimeActive" SG_ 592 CpbtyAxle1_TqCpbtyRateQltyLe 100;
BA_ "GenSigStartValue" SG_ 592 CpbtyAxle1_TqCpbtyRateQltyLe 3;
BA_ "GenSigCycleTime" SG_ 592 CpbtyAxle1_PadWearLe 100;
BA_ "GenSigCycleTimeActive" SG_ 592 CpbtyAxle1_PadWearLe 100;
BA_ "GenSigStartValue" SG_ 592 CpbtyAxle1_PadWearLe 255;
BA_ "GenSigCycleTime" SG_ 592 CpbtyAxle1_TqCpbtyMinRi 100;
BA_ "GenSigCycleTimeActive" SG_ 592 CpbtyAxle1_TqCpbtyMinRi 100;
BA_ "GenSigStartValue" SG_ 592 CpbtyAxle1_TqCpbtyMinRi 1023;
BA_ "GenSigCycleTime" SG_ 592 CpbtyAxle1_TqCpbtyQltyRi 100;
BA_ "GenSigCycleTimeActive" SG_ 592 CpbtyAxle1_TqCpbtyQltyRi 100;
BA_ "GenSigStartValue" SG_ 592 CpbtyAxle1_TqCpbtyQltyRi 3;
BA_ "GenSigCycleTime" SG_ 592 CpbtyAxle3_BrkEgyCpctyLe 100;
BA_ "GenSigCycleTimeActive" SG_ 592 CpbtyAxle3_BrkEgyCpctyLe 100;
BA_ "GenSigStartValue" SG_ 592 CpbtyAxle3_BrkEgyCpctyLe 255;
BA_ "GenSigCycleTime" SG_ 592 CpbtyAxle3_TqCpbtyRateIncLeRi 100;
BA_ "GenSigCycleTimeActive" SG_ 592 CpbtyAxle3_TqCpbtyRateIncLeRi 100;
BA_ "GenSigStartValue" SG_ 592 CpbtyAxle3_TqCpbtyRateIncLeRi 255;
BA_ "GenSigCycleTime" SG_ 592 CpbtyAxle1_TqCpbtyMinLe 100;
BA_ "GenSigCycleTimeActive" SG_ 592 CpbtyAxle1_TqCpbtyMinLe 100;
BA_ "GenSigStartValue" SG_ 592 CpbtyAxle1_TqCpbtyMinLe 1023;
BA_ "GenSigCycleTime" SG_ 592 CpbtyAxle2_TqCpbtyQltyLe 100;
BA_ "GenSigCycleTimeActive" SG_ 592 CpbtyAxle2_TqCpbtyQltyLe 100;
BA_ "GenSigStartValue" SG_ 592 CpbtyAxle2_TqCpbtyQltyLe 3;
BA_ "GenSigCycleTime" SG_ 592 CpbtyAxle2_TqCpbtyRateQltyLe 100;
BA_ "GenSigCycleTimeActive" SG_ 592 CpbtyAxle2_TqCpbtyRateQltyLe 100;
BA_ "GenSigStartValue" SG_ 592 CpbtyAxle2_TqCpbtyRateQltyLe 3;
BA_ "GenSigCycleTime" SG_ 592 CpbtyAxle2_BrkEgyCpctyRi 100;
BA_ "GenSigCycleTimeActive" SG_ 592 CpbtyAxle2_BrkEgyCpctyRi 100;
BA_ "GenSigStartValue" SG_ 592 CpbtyAxle2_BrkEgyCpctyRi 255;
BA_ "GenSigCycleTime" SG_ 592 CpbtyAxle1_BrkEgyCpctyQltyLe 100;
BA_ "GenSigCycleTimeActive" SG_ 592 CpbtyAxle1_BrkEgyCpctyQltyLe 100;
BA_ "GenSigStartValue" SG_ 592 CpbtyAxle1_BrkEgyCpctyQltyLe 3;
BA_ "GenSigCycleTime" SG_ 592 CpbtyAxle2_PadWearQltyLe 100;
BA_ "GenSigCycleTimeActive" SG_ 592 CpbtyAxle2_PadWearQltyLe 100;
BA_ "GenSigStartValue" SG_ 592 CpbtyAxle2_PadWearQltyLe 3;
BA_ "GenSigCycleTime" SG_ 592 CpbtyAxle1_TqCpbtyMaxLe 100;
BA_ "GenSigCycleTimeActive" SG_ 592 CpbtyAxle1_TqCpbtyMaxLe 100;
BA_ "GenSigStartValue" SG_ 592 CpbtyAxle1_TqCpbtyMaxLe 1023;
BA_ "GenSigCycleTime" SG_ 592 CpbtyAxle3_CRC 100;
BA_ "GenSigCycleTimeActive" SG_ 592 CpbtyAxle3_CRC 100;
BA_ "GenSigStartValue" SG_ 592 CpbtyAxle3_CRC 65535;
BA_ "E2EDataId" SG_ 592 CpbtyAxle3_CRC 191;
BA_ "E2EDataLength" SG_ 592 CpbtyAxle3_CRC 152;
BA_ "E2EProfile" SG_ 592 CpbtyAxle3_CRC "P05";
BA_ "GenSigCycleTime" SG_ 592 CpbtyAxle3_SqC 100;
BA_ "GenSigCycleTimeActive" SG_ 592 CpbtyAxle3_SqC 100;
BA_ "GenSigStartValue" SG_ 592 CpbtyAxle3_SqC 255;
BA_ "GenSigSendType" SG_ 41 PLCMsgStat_MsgErrCode_ISig_3 1;
BA_ "GenSigCycleTime" SG_ 41 PLCMsgStat_MsgErrCode_ISig_3 100;
BA_ "GenSigCycleTimeActive" SG_ 41 PLCMsgStat_MsgErrCode_ISig_3 100;
BA_ "GenSigStartValue" SG_ 41 PLCMsgStat_MsgErrCode_ISig_3 255;
BA_ "GenSigSendType" SG_ 41 PLCMsgStat_TxRetryCnt_ISig_3 1;
BA_ "GenSigCycleTime" SG_ 41 PLCMsgStat_TxRetryCnt_ISig_3 100;
BA_ "GenSigCycleTimeActive" SG_ 41 PLCMsgStat_TxRetryCnt_ISig_3 100;
BA_ "GenSigStartValue" SG_ 41 PLCMsgStat_TxRetryCnt_ISig_3 255;
BA_ "GenSigSendType" SG_ 41 PLCMsgStat_TxArbtrnFailCnt_ISig_ 1;
BA_ "GenSigCycleTime" SG_ 41 PLCMsgStat_TxArbtrnFailCnt_ISig_ 100;
BA_ "GenSigCycleTimeActive" SG_ 41 PLCMsgStat_TxArbtrnFailCnt_ISig_ 100;
BA_ "GenSigStartValue" SG_ 41 PLCMsgStat_TxArbtrnFailCnt_ISig_ 255;
BA_ "SystemSignalLongSymbol" SG_ 41 PLCMsgStat_TxArbtrnFailCnt_ISig_ "PLCMsgStat_TxArbtrnFailCnt_ISig_3";
BA_ "GenSigSendType" SG_ 41 PLCMsgStat_MsgStatus_ISig_3 1;
BA_ "GenSigCycleTime" SG_ 41 PLCMsgStat_MsgStatus_ISig_3 100;
BA_ "GenSigCycleTimeActive" SG_ 41 PLCMsgStat_MsgStatus_ISig_3 100;
BA_ "GenSigStartValue" SG_ 41 PLCMsgStat_MsgStatus_ISig_3 255;
BA_ "GenSigSendType" SG_ 1505 PhyDiagBrk2TPMReqSig_ISig_3 1;
BA_ "GenSigCycleTime" SG_ 1505 PhyDiagBrk2TPMReqSig_ISig_3 100;
BA_ "GenSigCycleTimeActive" SG_ 1505 PhyDiagBrk2TPMReqSig_ISig_3 100;
BA_ "GenSigCycleTime" SG_ 296 FrontAxleSpeed_ISig_3 100;
BA_ "GenSigCycleTimeActive" SG_ 296 FrontAxleSpeed_ISig_3 100;
BA_ "GenSigStartValue" SG_ 296 FrontAxleSpeed_ISig_3 65535;
BA_ "GenSigCycleTime" SG_ 832 WhlSpdSenTothCnt456_TimeStamp_IS 100;
BA_ "GenSigCycleTimeActive" SG_ 832 WhlSpdSenTothCnt456_TimeStamp_IS 100;
BA_ "GenSigStartValue" SG_ 832 WhlSpdSenTothCnt456_TimeStamp_IS 65535;
BA_ "SystemSignalLongSymbol" SG_ 832 WhlSpdSenTothCnt456_TimeStamp_IS "WhlSpdSenTothCnt456_TimeStamp_ISig_3";
BA_ "GenSigCycleTime" SG_ 832 WhlSpdSenTothCnt456_Axle6Right_I 100;
BA_ "GenSigCycleTimeActive" SG_ 832 WhlSpdSenTothCnt456_Axle6Right_I 100;
BA_ "GenSigStartValue" SG_ 832 WhlSpdSenTothCnt456_Axle6Right_I 255;
BA_ "SystemSignalLongSymbol" SG_ 832 WhlSpdSenTothCnt456_Axle6Right_I "WhlSpdSenTothCnt456_Axle6Right_ISig_3";
BA_ "GenSigCycleTime" SG_ 832 WhlSpdSenTothCnt456_Axle5Left_IS 100;
BA_ "GenSigCycleTimeActive" SG_ 832 WhlSpdSenTothCnt456_Axle5Left_IS 100;
BA_ "GenSigStartValue" SG_ 832 WhlSpdSenTothCnt456_Axle5Left_IS 255;
BA_ "SystemSignalLongSymbol" SG_ 832 WhlSpdSenTothCnt456_Axle5Left_IS "WhlSpdSenTothCnt456_Axle5Left_ISig_3";
BA_ "GenSigCycleTime" SG_ 832 WhlSpdSenTothCnt456_Axle4Right_I 100;
BA_ "GenSigCycleTimeActive" SG_ 832 WhlSpdSenTothCnt456_Axle4Right_I 100;
BA_ "GenSigStartValue" SG_ 832 WhlSpdSenTothCnt456_Axle4Right_I 255;
BA_ "SystemSignalLongSymbol" SG_ 832 WhlSpdSenTothCnt456_Axle4Right_I "WhlSpdSenTothCnt456_Axle4Right_ISig_3";
BA_ "GenSigCycleTime" SG_ 832 WhlSpdSenTothCnt456_Axle5Right_I 100;
BA_ "GenSigCycleTimeActive" SG_ 832 WhlSpdSenTothCnt456_Axle5Right_I 100;
BA_ "GenSigStartValue" SG_ 832 WhlSpdSenTothCnt456_Axle5Right_I 255;
BA_ "SystemSignalLongSymbol" SG_ 832 WhlSpdSenTothCnt456_Axle5Right_I "WhlSpdSenTothCnt456_Axle5Right_ISig_3";
BA_ "GenSigCycleTime" SG_ 832 WhlSpdSenTothCnt123_Axle2Left_IS 100;
BA_ "GenSigCycleTimeActive" SG_ 832 WhlSpdSenTothCnt123_Axle2Left_IS 100;
BA_ "GenSigStartValue" SG_ 832 WhlSpdSenTothCnt123_Axle2Left_IS 255;
BA_ "SystemSignalLongSymbol" SG_ 832 WhlSpdSenTothCnt123_Axle2Left_IS "WhlSpdSenTothCnt123_Axle2Left_ISig_3";
BA_ "GenSigCycleTime" SG_ 832 WhlSpdSenTothCnt123_TimeStamp_IS 100;
BA_ "GenSigCycleTimeActive" SG_ 832 WhlSpdSenTothCnt123_TimeStamp_IS 100;
BA_ "GenSigStartValue" SG_ 832 WhlSpdSenTothCnt123_TimeStamp_IS 65535;
BA_ "SystemSignalLongSymbol" SG_ 832 WhlSpdSenTothCnt123_TimeStamp_IS "WhlSpdSenTothCnt123_TimeStamp_ISig_3";
BA_ "GenSigCycleTime" SG_ 832 WhlSpdSenTothCnt456_Axle4Left_IS 100;
BA_ "GenSigCycleTimeActive" SG_ 832 WhlSpdSenTothCnt456_Axle4Left_IS 100;
BA_ "GenSigStartValue" SG_ 832 WhlSpdSenTothCnt456_Axle4Left_IS 255;
BA_ "SystemSignalLongSymbol" SG_ 832 WhlSpdSenTothCnt456_Axle4Left_IS "WhlSpdSenTothCnt456_Axle4Left_ISig_3";
BA_ "GenSigCycleTime" SG_ 832 WhlSpdSenTothCnt123_Axle3Left_IS 100;
BA_ "GenSigCycleTimeActive" SG_ 832 WhlSpdSenTothCnt123_Axle3Left_IS 100;
BA_ "GenSigStartValue" SG_ 832 WhlSpdSenTothCnt123_Axle3Left_IS 255;
BA_ "SystemSignalLongSymbol" SG_ 832 WhlSpdSenTothCnt123_Axle3Left_IS "WhlSpdSenTothCnt123_Axle3Left_ISig_3";
BA_ "GenSigCycleTime" SG_ 832 WhlSpdSenTothCnt123_Axle1Right_I 100;
BA_ "GenSigCycleTimeActive" SG_ 832 WhlSpdSenTothCnt123_Axle1Right_I 100;
BA_ "GenSigStartValue" SG_ 832 WhlSpdSenTothCnt123_Axle1Right_I 255;
BA_ "SystemSignalLongSymbol" SG_ 832 WhlSpdSenTothCnt123_Axle1Right_I "WhlSpdSenTothCnt123_Axle1Right_ISig_3";
BA_ "GenSigCycleTime" SG_ 832 WhlSpdSenTothCnt123_Axle3Right_I 100;
BA_ "GenSigCycleTimeActive" SG_ 832 WhlSpdSenTothCnt123_Axle3Right_I 100;
BA_ "GenSigStartValue" SG_ 832 WhlSpdSenTothCnt123_Axle3Right_I 255;
BA_ "SystemSignalLongSymbol" SG_ 832 WhlSpdSenTothCnt123_Axle3Right_I "WhlSpdSenTothCnt123_Axle3Right_ISig_3";
BA_ "GenSigCycleTime" SG_ 832 WhlSpdSenTothCnt456_Axle6Left_IS 100;
BA_ "GenSigCycleTimeActive" SG_ 832 WhlSpdSenTothCnt456_Axle6Left_IS 100;
BA_ "GenSigStartValue" SG_ 832 WhlSpdSenTothCnt456_Axle6Left_IS 255;
BA_ "SystemSignalLongSymbol" SG_ 832 WhlSpdSenTothCnt456_Axle6Left_IS "WhlSpdSenTothCnt456_Axle6Left_ISig_3";
BA_ "GenSigCycleTime" SG_ 832 WhlSpdSenTothCnt123_Axle2Right_I 100;
BA_ "GenSigCycleTimeActive" SG_ 832 WhlSpdSenTothCnt123_Axle2Right_I 100;
BA_ "GenSigStartValue" SG_ 832 WhlSpdSenTothCnt123_Axle2Right_I 255;
BA_ "SystemSignalLongSymbol" SG_ 832 WhlSpdSenTothCnt123_Axle2Right_I "WhlSpdSenTothCnt123_Axle2Right_ISig_3";
BA_ "GenSigCycleTime" SG_ 832 WhlSpdSenTothCnt123_Axle1Left_IS 100;
BA_ "GenSigCycleTimeActive" SG_ 832 WhlSpdSenTothCnt123_Axle1Left_IS 100;
BA_ "GenSigStartValue" SG_ 832 WhlSpdSenTothCnt123_Axle1Left_IS 255;
BA_ "SystemSignalLongSymbol" SG_ 832 WhlSpdSenTothCnt123_Axle1Left_IS "WhlSpdSenTothCnt123_Axle1Left_ISig_3";
BA_ "GenSigCycleTime" SG_ 1507 PLCBusStatus_ISig_3 100;
BA_ "GenSigCycleTimeActive" SG_ 1507 PLCBusStatus_ISig_3 100;
BA_ "GenSigStartValue" SG_ 1507 PLCBusStatus_ISig_3 255;
BA_ "GenSigCycleTime" SG_ 1105 XPRRequest_EBS 100;
BA_ "GenSigCycleTimeActive" SG_ 1105 XPRRequest_EBS 100;
BA_ "GenSigStartValue" SG_ 1105 XPRRequest_EBS 255;
BA_ "GenSigCycleTime" SG_ 1105 XBRSystemState_ISig_3 100;
BA_ "GenSigCycleTimeActive" SG_ 1105 XBRSystemState_ISig_3 100;
BA_ "GenSigStartValue" SG_ 1105 XBRSystemState_ISig_3 3;
BA_ "GenSigMaxLatency" SG_ 1105 XBRSystemState_ISig_3 100;
BA_ "GenSigCycleTime" SG_ 1105 ABSFullyOperational_ISig_3 100;
BA_ "GenSigCycleTimeActive" SG_ 1105 ABSFullyOperational_ISig_3 100;
BA_ "GenSigStartValue" SG_ 1105 ABSFullyOperational_ISig_3 3;
BA_ "GenSigCycleTime" SG_ 1105 TrailerCommunicationType_ISig_3 100;
BA_ "GenSigCycleTimeActive" SG_ 1105 TrailerCommunicationType_ISig_3 100;
BA_ "GenSigStartValue" SG_ 1105 TrailerCommunicationType_ISig_3 7;
BA_ "GenSigMaxLatency" SG_ 1105 TrailerCommunicationType_ISig_3 100;
BA_ "GenSigCycleTime" SG_ 439 ABSAxle5Active 100;
BA_ "GenSigCycleTimeActive" SG_ 439 ABSAxle5Active 100;
BA_ "GenSigStartValue" SG_ 439 ABSAxle5Active 3;
BA_ "GenSigMaxLatency" SG_ 439 ABSAxle5Active 20;
BA_ "GenSigCycleTime" SG_ 439 EACompound_CRC 100;
BA_ "GenSigCycleTimeActive" SG_ 439 EACompound_CRC 100;
BA_ "GenSigStartValue" SG_ 439 EACompound_CRC 255;
BA_ "GenSigMaxLatency" SG_ 439 EACompound_CRC 20;
BA_ "E2EDataId" SG_ 439 EACompound_CRC 106;
BA_ "E2EDataLength" SG_ 439 EACompound_CRC 24;
BA_ "E2EProfile" SG_ 439 EACompound_CRC "P01";
BA_ "GenSigCycleTime" SG_ 439 RrAxle1RtWhlBrakeApplPrsHiRng 100;
BA_ "GenSigCycleTimeActive" SG_ 439 RrAxle1RtWhlBrakeApplPrsHiRng 100;
BA_ "GenSigStartValue" SG_ 439 RrAxle1RtWhlBrakeApplPrsHiRng 255;
BA_ "GenSigMaxLatency" SG_ 439 RrAxle1RtWhlBrakeApplPrsHiRng 20;
BA_ "GenSigCycleTime" SG_ 439 RrAxle3RtWhlBrakeApplPrsHiRng 100;
BA_ "GenSigCycleTimeActive" SG_ 439 RrAxle3RtWhlBrakeApplPrsHiRng 100;
BA_ "GenSigStartValue" SG_ 439 RrAxle3RtWhlBrakeApplPrsHiRng 255;
BA_ "GenSigMaxLatency" SG_ 439 RrAxle3RtWhlBrakeApplPrsHiRng 20;
BA_ "GenSigCycleTime" SG_ 439 Trailer1TractionHelp_ISig_3 100;
BA_ "GenSigCycleTimeActive" SG_ 439 Trailer1TractionHelp_ISig_3 100;
BA_ "GenSigStartValue" SG_ 439 Trailer1TractionHelp_ISig_3 3;
BA_ "GenSigCycleTime" SG_ 439 FrAxleRtWhlBrakeApplPrsHiRng 100;
BA_ "GenSigCycleTimeActive" SG_ 439 FrAxleRtWhlBrakeApplPrsHiRng 100;
BA_ "GenSigStartValue" SG_ 439 FrAxleRtWhlBrakeApplPrsHiRng 255;
BA_ "GenSigMaxLatency" SG_ 439 FrAxleRtWhlBrakeApplPrsHiRng 20;
BA_ "GenSigCycleTime" SG_ 439 EBSBrakeSwitch_ISig_3 100;
BA_ "GenSigCycleTimeActive" SG_ 439 EBSBrakeSwitch_ISig_3 100;
BA_ "GenSigStartValue" SG_ 439 EBSBrakeSwitch_ISig_3 3;
BA_ "GenSigCycleTime" SG_ 439 EACompound_SystemState 100;
BA_ "GenSigCycleTimeActive" SG_ 439 EACompound_SystemState 100;
BA_ "GenSigStartValue" SG_ 439 EACompound_SystemState 3;
BA_ "GenSigMaxLatency" SG_ 439 EACompound_SystemState 20;
BA_ "GenSigCycleTime" SG_ 439 EBSBrakePedalPosition 100;
BA_ "GenSigCycleTimeActive" SG_ 439 EBSBrakePedalPosition 100;
BA_ "GenSigStartValue" SG_ 439 EBSBrakePedalPosition 255;
BA_ "GenSigCycleTime" SG_ 439 AntiLockBrakingActive_ISig_3 100;
BA_ "GenSigCycleTimeActive" SG_ 439 AntiLockBrakingActive_ISig_3 100;
BA_ "GenSigStartValue" SG_ 439 AntiLockBrakingActive_ISig_3 3;
BA_ "GenSigMaxLatency" SG_ 439 AntiLockBrakingActive_ISig_3 20;
BA_ "GenSigCycleTime" SG_ 439 StretchBrake_Stat_ISig_3 100;
BA_ "GenSigCycleTimeActive" SG_ 439 StretchBrake_Stat_ISig_3 100;
BA_ "GenSigStartValue" SG_ 439 StretchBrake_Stat_ISig_3 7;
BA_ "GenSigMaxLatency" SG_ 439 StretchBrake_Stat_ISig_3 20;
BA_ "GenSigCycleTime" SG_ 439 HillHolderMode_ISig_3 100;
BA_ "GenSigCycleTimeActive" SG_ 439 HillHolderMode_ISig_3 100;
BA_ "GenSigStartValue" SG_ 439 HillHolderMode_ISig_3 7;
BA_ "GenSigMaxLatency" SG_ 439 HillHolderMode_ISig_3 20;
BA_ "GenSigCycleTime" SG_ 439 ABSAxle4Active 100;
BA_ "GenSigCycleTimeActive" SG_ 439 ABSAxle4Active 100;
BA_ "GenSigStartValue" SG_ 439 ABSAxle4Active 3;
BA_ "GenSigMaxLatency" SG_ 439 ABSAxle4Active 20;
BA_ "GenSigCycleTime" SG_ 439 TrailerBrake_Stat_ISig_3 100;
BA_ "GenSigCycleTimeActive" SG_ 439 TrailerBrake_Stat_ISig_3 100;
BA_ "GenSigStartValue" SG_ 439 TrailerBrake_Stat_ISig_3 3;
BA_ "GenSigMaxLatency" SG_ 439 TrailerBrake_Stat_ISig_3 20;
BA_ "GenSigCycleTime" SG_ 439 CombinedWheelSpeed_CRC 100;
BA_ "GenSigCycleTimeActive" SG_ 439 CombinedWheelSpeed_CRC 100;
BA_ "GenSigStartValue" SG_ 439 CombinedWheelSpeed_CRC 255;
BA_ "GenSigMaxLatency" SG_ 439 CombinedWheelSpeed_CRC 20;
BA_ "E2EDataId" SG_ 439 CombinedWheelSpeed_CRC 221;
BA_ "E2EDataLength" SG_ 439 CombinedWheelSpeed_CRC 32;
BA_ "E2EProfile" SG_ 439 CombinedWheelSpeed_CRC "P01";
BA_ "GenSigCycleTime" SG_ 439 ABSAxle2Active 100;
BA_ "GenSigCycleTimeActive" SG_ 439 ABSAxle2Active 100;
BA_ "GenSigStartValue" SG_ 439 ABSAxle2Active 3;
BA_ "GenSigMaxLatency" SG_ 439 ABSAxle2Active 20;
BA_ "GenSigCycleTime" SG_ 439 TrailerEBSAmberWarning_ISig_3 100;
BA_ "GenSigCycleTimeActive" SG_ 439 TrailerEBSAmberWarning_ISig_3 100;
BA_ "GenSigStartValue" SG_ 439 TrailerEBSAmberWarning_ISig_3 3;
BA_ "GenSigMaxLatency" SG_ 439 TrailerEBSAmberWarning_ISig_3 20;
BA_ "GenSigCycleTime" SG_ 439 CombinedWheelSpeed_SqC 100;
BA_ "GenSigCycleTimeActive" SG_ 439 CombinedWheelSpeed_SqC 100;
BA_ "GenSigStartValue" SG_ 439 CombinedWheelSpeed_SqC 14;
BA_ "GenSigMaxLatency" SG_ 439 CombinedWheelSpeed_SqC 20;
BA_ "GenSigCycleTime" SG_ 439 ABSAxle1Active 100;
BA_ "GenSigCycleTimeActive" SG_ 439 ABSAxle1Active 100;
BA_ "GenSigStartValue" SG_ 439 ABSAxle1Active 3;
BA_ "GenSigMaxLatency" SG_ 439 ABSAxle1Active 20;
BA_ "GenSigCycleTime" SG_ 439 RrAxle2LtWhlBrakeApplPrsHiRng 100;
BA_ "GenSigCycleTimeActive" SG_ 439 RrAxle2LtWhlBrakeApplPrsHiRng 100;
BA_ "GenSigStartValue" SG_ 439 RrAxle2LtWhlBrakeApplPrsHiRng 255;
BA_ "GenSigMaxLatency" SG_ 439 RrAxle2LtWhlBrakeApplPrsHiRng 20;
BA_ "GenSigCycleTime" SG_ 439 ABSAxle3Active 100;
BA_ "GenSigCycleTimeActive" SG_ 439 ABSAxle3Active 100;
BA_ "GenSigStartValue" SG_ 439 ABSAxle3Active 3;
BA_ "GenSigMaxLatency" SG_ 439 ABSAxle3Active 20;
BA_ "GenSigCycleTime" SG_ 439 TCMSupply_SqC 100;
BA_ "GenSigCycleTimeActive" SG_ 439 TCMSupply_SqC 100;
BA_ "GenSigStartValue" SG_ 439 TCMSupply_SqC 14;
BA_ "GenSigMaxLatency" SG_ 439 TCMSupply_SqC 20;
BA_ "GenSigCycleTime" SG_ 439 PusherLiftAxleLoweringInhibit_IS 100;
BA_ "GenSigCycleTimeActive" SG_ 439 PusherLiftAxleLoweringInhibit_IS 100;
BA_ "GenSigStartValue" SG_ 439 PusherLiftAxleLoweringInhibit_IS 3;
BA_ "SystemSignalLongSymbol" SG_ 439 PusherLiftAxleLoweringInhibit_IS "PusherLiftAxleLoweringInhibit_ISig_3";
BA_ "GenSigCycleTime" SG_ 439 CombinedWheelSpeed_Quality 100;
BA_ "GenSigCycleTimeActive" SG_ 439 CombinedWheelSpeed_Quality 100;
BA_ "GenSigStartValue" SG_ 439 CombinedWheelSpeed_Quality 7;
BA_ "GenSigMaxLatency" SG_ 439 CombinedWheelSpeed_Quality 20;
BA_ "GenSigCycleTime" SG_ 439 SplitBoxDiffLockActvnFuncReq_ISi 100;
BA_ "GenSigCycleTimeActive" SG_ 439 SplitBoxDiffLockActvnFuncReq_ISi 100;
BA_ "GenSigStartValue" SG_ 439 SplitBoxDiffLockActvnFuncReq_ISi 3;
BA_ "GenSigMaxLatency" SG_ 439 SplitBoxDiffLockActvnFuncReq_ISi 20;
BA_ "SystemSignalLongSymbol" SG_ 439 SplitBoxDiffLockActvnFuncReq_ISi "SplitBoxDiffLockActvnFuncReq_ISig_3";
BA_ "GenSigCycleTime" SG_ 439 SteerableLiftAxleLoweringInhib 100;
BA_ "GenSigCycleTimeActive" SG_ 439 SteerableLiftAxleLoweringInhib 100;
BA_ "GenSigStartValue" SG_ 439 SteerableLiftAxleLoweringInhib 3;
BA_ "GenSigMaxLatency" SG_ 439 SteerableLiftAxleLoweringInhib 20;
BA_ "GenSigCycleTime" SG_ 439 RrAxle3LtWhlBrakeApplPrsHiRng 100;
BA_ "GenSigCycleTimeActive" SG_ 439 RrAxle3LtWhlBrakeApplPrsHiRng 100;
BA_ "GenSigStartValue" SG_ 439 RrAxle3LtWhlBrakeApplPrsHiRng 255;
BA_ "GenSigMaxLatency" SG_ 439 RrAxle3LtWhlBrakeApplPrsHiRng 20;
BA_ "GenSigCycleTime" SG_ 439 EACompound_AppliedRatio 100;
BA_ "GenSigCycleTimeActive" SG_ 439 EACompound_AppliedRatio 100;
BA_ "GenSigStartValue" SG_ 439 EACompound_AppliedRatio 255;
BA_ "GenSigMaxLatency" SG_ 439 EACompound_AppliedRatio 20;
BA_ "GenSigCycleTime" SG_ 439 BrakingSystemPressureLim_rqst_IS 100;
BA_ "GenSigCycleTimeActive" SG_ 439 BrakingSystemPressureLim_rqst_IS 100;
BA_ "GenSigStartValue" SG_ 439 BrakingSystemPressureLim_rqst_IS 3;
BA_ "GenSigMaxLatency" SG_ 439 BrakingSystemPressureLim_rqst_IS 20;
BA_ "SystemSignalLongSymbol" SG_ 439 BrakingSystemPressureLim_rqst_IS "BrakingSystemPressureLim_rqst_ISig_3";
BA_ "GenSigCycleTime" SG_ 439 RrAxle1LtWhlBrakeApplPrsHiRng 100;
BA_ "GenSigCycleTimeActive" SG_ 439 RrAxle1LtWhlBrakeApplPrsHiRng 100;
BA_ "GenSigStartValue" SG_ 439 RrAxle1LtWhlBrakeApplPrsHiRng 255;
BA_ "GenSigMaxLatency" SG_ 439 RrAxle1LtWhlBrakeApplPrsHiRng 20;
BA_ "GenSigCycleTime" SG_ 439 EACompound_SqC 100;
BA_ "GenSigCycleTimeActive" SG_ 439 EACompound_SqC 100;
BA_ "GenSigStartValue" SG_ 439 EACompound_SqC 14;
BA_ "GenSigMaxLatency" SG_ 439 EACompound_SqC 20;
BA_ "GenSigCycleTime" SG_ 439 TCMSupply_CRC 100;
BA_ "GenSigCycleTimeActive" SG_ 439 TCMSupply_CRC 100;
BA_ "GenSigStartValue" SG_ 439 TCMSupply_CRC 255;
BA_ "GenSigMaxLatency" SG_ 439 TCMSupply_CRC 20;
BA_ "E2EDataId" SG_ 439 TCMSupply_CRC 109;
BA_ "E2EDataLength" SG_ 439 TCMSupply_CRC 24;
BA_ "E2EProfile" SG_ 439 TCMSupply_CRC "P01";
BA_ "GenSigCycleTime" SG_ 439 TrailerControlPressure 100;
BA_ "GenSigCycleTimeActive" SG_ 439 TrailerControlPressure 100;
BA_ "GenSigStartValue" SG_ 439 TrailerControlPressure 255;
BA_ "GenSigMaxLatency" SG_ 439 TrailerControlPressure 20;
BA_ "GenSigCycleTime" SG_ 439 RrAxle2RtWhlBrakeApplPrsHiRng 100;
BA_ "GenSigCycleTimeActive" SG_ 439 RrAxle2RtWhlBrakeApplPrsHiRng 100;
BA_ "GenSigStartValue" SG_ 439 RrAxle2RtWhlBrakeApplPrsHiRng 255;
BA_ "GenSigMaxLatency" SG_ 439 RrAxle2RtWhlBrakeApplPrsHiRng 20;
BA_ "GenSigCycleTime" SG_ 439 ScndRrAxlDiffLckActvnFuncReq_ISi 100;
BA_ "GenSigCycleTimeActive" SG_ 439 ScndRrAxlDiffLckActvnFuncReq_ISi 100;
BA_ "GenSigStartValue" SG_ 439 ScndRrAxlDiffLckActvnFuncReq_ISi 3;
BA_ "GenSigMaxLatency" SG_ 439 ScndRrAxlDiffLckActvnFuncReq_ISi 20;
BA_ "SystemSignalLongSymbol" SG_ 439 ScndRrAxlDiffLckActvnFuncReq_ISi "ScndRrAxlDiffLckActvnFuncReq_ISig_3";
BA_ "GenSigCycleTime" SG_ 439 TCMSupply_TrailerPressure 100;
BA_ "GenSigCycleTimeActive" SG_ 439 TCMSupply_TrailerPressure 100;
BA_ "GenSigStartValue" SG_ 439 TCMSupply_TrailerPressure 255;
BA_ "GenSigMaxLatency" SG_ 439 TCMSupply_TrailerPressure 20;
BA_ "GenSigCycleTime" SG_ 439 CombinedWheelSpeed_Speed 100;
BA_ "GenSigCycleTimeActive" SG_ 439 CombinedWheelSpeed_Speed 100;
BA_ "GenSigStartValue" SG_ 439 CombinedWheelSpeed_Speed 65535;
BA_ "GenSigMaxLatency" SG_ 439 CombinedWheelSpeed_Speed 20;
BA_ "GenSigCycleTime" SG_ 439 HSAState 100;
BA_ "GenSigCycleTimeActive" SG_ 439 HSAState 100;
BA_ "GenSigStartValue" SG_ 439 HSAState 3;
BA_ "GenSigMaxLatency" SG_ 439 HSAState 20;
BA_ "GenSigCycleTime" SG_ 439 FrAxleLtWhlBrakeApplPrsHiRng 100;
BA_ "GenSigCycleTimeActive" SG_ 439 FrAxleLtWhlBrakeApplPrsHiRng 100;
BA_ "GenSigStartValue" SG_ 439 FrAxleLtWhlBrakeApplPrsHiRng 255;
BA_ "GenSigMaxLatency" SG_ 439 FrAxleLtWhlBrakeApplPrsHiRng 20;
BA_ "GenSigCycleTime" SG_ 315 FrontAxleLeftWheelSpeed_ISig_3 100;
BA_ "GenSigCycleTimeActive" SG_ 315 FrontAxleLeftWheelSpeed_ISig_3 100;
BA_ "GenSigStartValue" SG_ 315 FrontAxleLeftWheelSpeed_ISig_3 65535;
BA_ "GenSigMaxLatency" SG_ 315 FrontAxleLeftWheelSpeed_ISig_3 10;
BA_ "GenSigCycleTime" SG_ 315 SteeringWheel_AngleCRC 100;
BA_ "GenSigCycleTimeActive" SG_ 315 SteeringWheel_AngleCRC 100;
BA_ "GenSigMaxLatency" SG_ 315 SteeringWheel_AngleCRC 10;
BA_ "GenSigCycleTime" SG_ 315 SteeringWheelTurnCounter 100;
BA_ "GenSigCycleTimeActive" SG_ 315 SteeringWheelTurnCounter 100;
BA_ "GenSigStartValue" SG_ 315 SteeringWheelTurnCounter 63;
BA_ "GenSigCycleTime" SG_ 315 SteeringWheel_AngleCounter 100;
BA_ "GenSigCycleTimeActive" SG_ 315 SteeringWheel_AngleCounter 100;
BA_ "GenSigMaxLatency" SG_ 315 SteeringWheel_AngleCounter 10;
BA_ "GenSigCycleTime" SG_ 315 FrontAxleRightWheelSpeed_ISig_3 100;
BA_ "GenSigCycleTimeActive" SG_ 315 FrontAxleRightWheelSpeed_ISig_3 100;
BA_ "GenSigStartValue" SG_ 315 FrontAxleRightWheelSpeed_ISig_3 65535;
BA_ "GenSigMaxLatency" SG_ 315 FrontAxleRightWheelSpeed_ISig_3 10;
BA_ "GenSigCycleTime" SG_ 315 LateralAcceleration_ISig_3 100;
BA_ "GenSigCycleTimeActive" SG_ 315 LateralAcceleration_ISig_3 100;
BA_ "GenSigStartValue" SG_ 315 LateralAcceleration_ISig_3 65535;
BA_ "GenSigCycleTime" SG_ 315 SteeringWheelAngleSensorType 100;
BA_ "GenSigCycleTimeActive" SG_ 315 SteeringWheelAngleSensorType 100;
BA_ "GenSigStartValue" SG_ 315 SteeringWheelAngleSensorType 3;
BA_ "GenSigCycleTime" SG_ 315 BrakeLightActivationRequest_ISig 100;
BA_ "GenSigCycleTimeActive" SG_ 315 BrakeLightActivationRequest_ISig 100;
BA_ "GenSigStartValue" SG_ 315 BrakeLightActivationRequest_ISig 3;
BA_ "SystemSignalLongSymbol" SG_ 315 BrakeLightActivationRequest_ISig "BrakeLightActivationRequest_ISig_3";
BA_ "GenSigCycleTime" SG_ 315 SteeringWheel_AngleValue 100;
BA_ "GenSigCycleTimeActive" SG_ 315 SteeringWheel_AngleValue 100;
BA_ "GenSigStartValue" SG_ 315 SteeringWheel_AngleValue 65535;
BA_ "GenSigMaxLatency" SG_ 315 SteeringWheel_AngleValue 10;
BA_ "GenSigCycleTime" SG_ 315 LongitudinalAcceleration_ISig_3 100;
BA_ "GenSigCycleTimeActive" SG_ 315 LongitudinalAcceleration_ISig_3 100;
BA_ "GenSigStartValue" SG_ 315 LongitudinalAcceleration_ISig_3 65535;
BA_ "GenSigCycleTime" SG_ 315 SteeringWheelAngle_ISig_3 100;
BA_ "GenSigCycleTimeActive" SG_ 315 SteeringWheelAngle_ISig_3 100;
BA_ "GenSigStartValue" SG_ 315 SteeringWheelAngle_ISig_3 65535;
BA_ "GenSigMaxLatency" SG_ 315 SteeringWheelAngle_ISig_3 10;
BA_ "GenSigCycleTime" SG_ 315 SteeringWheelAngleComp 100;
BA_ "GenSigCycleTimeActive" SG_ 315 SteeringWheelAngleComp 100;
BA_ "GenSigStartValue" SG_ 315 SteeringWheelAngleComp 65535;
BA_ "GenSigMaxLatency" SG_ 315 SteeringWheelAngleComp 10;
BA_ "GenSigCycleTime" SG_ 315 YawRate_ISig_3 100;
BA_ "GenSigCycleTimeActive" SG_ 315 YawRate_ISig_3 100;
BA_ "GenSigStartValue" SG_ 315 YawRate_ISig_3 65535;
BA_ "GenSigMaxLatency" SG_ 315 YawRate_ISig_3 10;
BA_ "GenSigCycleTime" SG_ 315 VDCBrakeLightRequest_ISig_3 100;
BA_ "GenSigCycleTimeActive" SG_ 315 VDCBrakeLightRequest_ISig_3 100;
BA_ "GenSigStartValue" SG_ 315 VDCBrakeLightRequest_ISig_3 3;
BA_ "GenSigSendType" SG_ 2671964720 DiagUUDTRespSig_F2_30_ISig_3 7;
BA_ "GenSigSendType" SG_ 2671964707 DiagUUDTRespSig_F2_23_ISig_3 7;
BA_ "GenSigSendType" SG_ 2671834160 InternalTesterDiagSig_F4_30 7;
BA_ "GenSigSendType" SG_ 2671834147 InternalTesterDiagSig_F4_23 7;
BA_ "GenSigSendType" SG_ 2671784180 InternalTesterDiagSig_30_F4 7;
BA_ "GenSigSendType" SG_ 2671780852 InternalTesterDiagSig_23_F4 7;
BA_ "GenSigSendType" SG_ 1491 DiagFaultStat_FAS_sg_UB 7;
BA_ "GenSigSendType" SG_ 1491 DiagFaultStat_FAS_FailTA 3;
BA_ "NeedsUpdateBit" SG_ 1491 DiagFaultStat_FAS_FailTA 1;
BA_ "GenSigSendType" SG_ 1491 DiagFaultStat_FAS_EcuAdr 3;
BA_ "GenSigStartValue" SG_ 1491 DiagFaultStat_FAS_EcuAdr 255;
BA_ "NeedsUpdateBit" SG_ 1491 DiagFaultStat_FAS_EcuAdr 1;
BA_ "GenSigSendType" SG_ 1491 DiagFaultStat_FAS_DtcIdA 3;
BA_ "NeedsUpdateBit" SG_ 1491 DiagFaultStat_FAS_DtcIdA 1;
BA_ "GenSigSendType" SG_ 1491 DiagFaultStat_FAS_DtcIdB 3;
BA_ "NeedsUpdateBit" SG_ 1491 DiagFaultStat_FAS_DtcIdB 1;
BA_ "GenSigSendType" SG_ 1491 DiagFaultStat_FAS_FailTB 3;
BA_ "NeedsUpdateBit" SG_ 1491 DiagFaultStat_FAS_FailTB 1;
BA_ "GenSigSendType" SG_ 1954 Debug_9_FAS 1;
BA_ "GenSigSendType" SG_ 1949 Debug_8_FAS 1;
BA_ "GenSigSendType" SG_ 1944 Debug_7_FAS 1;
BA_ "GenSigSendType" SG_ 1938 Debug_6_FAS 1;
BA_ "GenSigSendType" SG_ 1930 Debug_5_FAS 1;
BA_ "GenSigSendType" SG_ 1922 Debug_4_FAS 1;
BA_ "GenSigSendType" SG_ 1914 Debug_3_FAS 1;
BA_ "GenSigSendType" SG_ 1906 Debug_2_FAS 1;
BA_ "GenSigSendType" SG_ 1898 Debug_1_FAS 1;
BA_ "GenSigSendType" SG_ 1959 Debug_16_FAS 1;
BA_ "GenSigSendType" SG_ 1891 Debug_15_FAS 1;
BA_ "GenSigSendType" SG_ 1890 Debug_14_FAS 1;
BA_ "GenSigSendType" SG_ 1889 Debug_13_FAS 1;
BA_ "GenSigSendType" SG_ 1888 Debug_12_FAS 1;
BA_ "GenSigSendType" SG_ 1887 Debug_11_FAS 1;
BA_ "GenSigSendType" SG_ 1886 Debug_10_FAS 1;
BA_ "GenSigSendType" SG_ 2041 DSPTesterRespSigFAS 1;
BA_ "GenSigCycleTimeActive" SG_ 2041 DSPTesterRespSigFAS 100;
BA_ "GenSigSendType" SG_ 2047 DSPTesterReqSigFAS 1;
BA_ "GenSigCycleTime" SG_ 2047 DSPTesterReqSigFAS 100;
BA_ "GenSigCycleTimeActive" SG_ 2047 DSPTesterReqSigFAS 100;
BA_ "GenSigSendType" SG_ 1703 AnmSig_VCM_CAN03 1;
BA_ "GenSigCycleTime" SG_ 1703 AnmSig_VCM_CAN03 100;
BA_ "GenSigCycleTimeActive" SG_ 1703 AnmSig_VCM_CAN03 100;
BA_ "MmAnSignal" SG_ 1703 AnmSig_VCM_CAN03 1;
BA_ "GenSigSendType" SG_ 1701 AnmSig_FAS_CAN03 1;
BA_ "GenSigCycleTime" SG_ 1701 AnmSig_FAS_CAN03 100;
BA_ "GenSigCycleTimeActive" SG_ 1701 AnmSig_FAS_CAN03 100;
BA_ "MmAnSignal" SG_ 1701 AnmSig_FAS_CAN03 1;
BA_ "GenSigSendType" SG_ 1704 AnmSig_EBS_CAN03 1;
BA_ "GenSigCycleTime" SG_ 1704 AnmSig_EBS_CAN03 100;
BA_ "GenSigCycleTimeActive" SG_ 1704 AnmSig_EBS_CAN03 100;
BA_ "MmAnSignal" SG_ 1704 AnmSig_EBS_CAN03 1;
BA_ "GenSigSendType" SG_ 1702 AnmSig_APM_CAN03 1;
BA_ "GenSigCycleTime" SG_ 1702 AnmSig_APM_CAN03 100;
BA_ "GenSigCycleTimeActive" SG_ 1702 AnmSig_APM_CAN03 100;
BA_ "MmAnSignal" SG_ 1702 AnmSig_APM_CAN03 1;
BA_ "GenSigSendType" SG_ 1152 DiagFaultStat_APM_EcuAdr 3;
BA_ "GenSigStartValue" SG_ 1152 DiagFaultStat_APM_EcuAdr 255;
BA_ "NeedsUpdateBit" SG_ 1152 DiagFaultStat_APM_EcuAdr 1;
BA_ "GenSigSendType" SG_ 1152 DiagFaultStat_APM_sg_UB 7;
BA_ "GenSigSendType" SG_ 1152 DiagFaultStat_APM_FailTB 3;
BA_ "GenSigStartValue" SG_ 1152 DiagFaultStat_APM_FailTB 255;
BA_ "NeedsUpdateBit" SG_ 1152 DiagFaultStat_APM_FailTB 1;
BA_ "GenSigSendType" SG_ 1152 DiagFaultStat_APM_DtcIdB 3;
BA_ "GenSigStartValue" SG_ 1152 DiagFaultStat_APM_DtcIdB 65535;
BA_ "NeedsUpdateBit" SG_ 1152 DiagFaultStat_APM_DtcIdB 1;
BA_ "GenSigSendType" SG_ 1152 DiagFaultStat_APM_FailTA 3;
BA_ "GenSigStartValue" SG_ 1152 DiagFaultStat_APM_FailTA 255;
BA_ "NeedsUpdateBit" SG_ 1152 DiagFaultStat_APM_FailTA 1;
BA_ "GenSigSendType" SG_ 1152 DiagFaultStat_APM_DtcIdA 3;
BA_ "GenSigStartValue" SG_ 1152 DiagFaultStat_APM_DtcIdA 65535;
BA_ "NeedsUpdateBit" SG_ 1152 DiagFaultStat_APM_DtcIdA 1;
BA_ "GenSigCycleTime" SG_ 1536 AirCartridgeWearingPercentage 100;
BA_ "GenSigCycleTimeActive" SG_ 1536 AirCartridgeWearingPercentage 100;
BA_ "GenSigStartValue" SG_ 1536 AirCartridgeWearingPercentage 255;
BA_ "GenSigCycleTime" SG_ 1536 TotAirVolCurrentAirDryerFilter 100;
BA_ "GenSigCycleTimeActive" SG_ 1536 TotAirVolCurrentAirDryerFilter 100;
BA_ "GenSigStartValue" SG_ 1536 TotAirVolCurrentAirDryerFilter 1023;
BA_ "GenSigCycleTime" SG_ 896 PBSensorRawADCValue 100;
BA_ "GenSigCycleTimeActive" SG_ 896 PBSensorRawADCValue 100;
BA_ "GenSigStartValue" SG_ 896 PBSensorRawADCValue 4095;
BA_ "GenSigCycleTime" SG_ 896 ServiceBrakeAirPrsCircuit2_ISig_ 100;
BA_ "GenSigCycleTimeActive" SG_ 896 ServiceBrakeAirPrsCircuit2_ISig_ 100;
BA_ "GenSigStartValue" SG_ 896 ServiceBrakeAirPrsCircuit2_ISig_ 255;
BA_ "SystemSignalLongSymbol" SG_ 896 ServiceBrakeAirPrsCircuit2_ISig_ "ServiceBrakeAirPrsCircuit2_ISig_3";
BA_ "GenSigCycleTime" SG_ 896 ParkingAndTrailerAirPressure 100;
BA_ "GenSigCycleTimeActive" SG_ 896 ParkingAndTrailerAirPressure 100;
BA_ "GenSigStartValue" SG_ 896 ParkingAndTrailerAirPressure 255;
BA_ "GenSigCycleTime" SG_ 896 ServiceBrakeAirPrsCircuit1_ISig_ 100;
BA_ "GenSigCycleTimeActive" SG_ 896 ServiceBrakeAirPrsCircuit1_ISig_ 100;
BA_ "GenSigStartValue" SG_ 896 ServiceBrakeAirPrsCircuit1_ISig_ 255;
BA_ "SystemSignalLongSymbol" SG_ 896 ServiceBrakeAirPrsCircuit1_ISig_ "ServiceBrakeAirPrsCircuit1_ISig_3";
BA_ "GenSigCycleTime" SG_ 640 APMSafetyWarning_YellowRqst_ISig 100;
BA_ "GenSigCycleTimeActive" SG_ 640 APMSafetyWarning_YellowRqst_ISig 100;
BA_ "GenSigStartValue" SG_ 640 APMSafetyWarning_YellowRqst_ISig 3;
BA_ "SystemSignalLongSymbol" SG_ 640 APMSafetyWarning_YellowRqst_ISig "APMSafetyWarning_YellowRqst_ISig_3";
BA_ "GenSigCycleTime" SG_ 640 TrailerStatus_IntegrityLvl_ISig_ 100;
BA_ "GenSigCycleTimeActive" SG_ 640 TrailerStatus_IntegrityLvl_ISig_ 100;
BA_ "GenSigStartValue" SG_ 640 TrailerStatus_IntegrityLvl_ISig_ 3;
BA_ "SystemSignalLongSymbol" SG_ 640 TrailerStatus_IntegrityLvl_ISig_ "TrailerStatus_IntegrityLvl_ISig_3";
BA_ "GenSigCycleTime" SG_ 640 PBAirLvl_SqC 100;
BA_ "GenSigCycleTimeActive" SG_ 640 PBAirLvl_SqC 100;
BA_ "GenSigStartValue" SG_ 640 PBAirLvl_SqC 14;
BA_ "GenSigMaxLatency" SG_ 640 PBAirLvl_SqC 100;
BA_ "GenSigCycleTime" SG_ 640 RedGladHand_SqC_ISig_3 100;
BA_ "GenSigCycleTimeActive" SG_ 640 RedGladHand_SqC_ISig_3 100;
BA_ "GenSigStartValue" SG_ 640 RedGladHand_SqC_ISig_3 14;
BA_ "GenSigCycleTime" SG_ 640 LowAirPressureAlert_ISig_3 100;
BA_ "GenSigCycleTimeActive" SG_ 640 LowAirPressureAlert_ISig_3 100;
BA_ "GenSigStartValue" SG_ 640 LowAirPressureAlert_ISig_3 3;
BA_ "GenSigCycleTime" SG_ 640 TrailerStatus_CRC_ISig_3 100;
BA_ "GenSigCycleTimeActive" SG_ 640 TrailerStatus_CRC_ISig_3 100;
BA_ "GenSigStartValue" SG_ 640 TrailerStatus_CRC_ISig_3 255;
BA_ "E2EDataId" SG_ 640 TrailerStatus_CRC_ISig_3 116;
BA_ "E2EDataLength" SG_ 640 TrailerStatus_CRC_ISig_3 24;
BA_ "E2EProfile" SG_ 640 TrailerStatus_CRC_ISig_3 "P01";
BA_ "GenSigCycleTime" SG_ 640 PBPositionLeverCopy 100;
BA_ "GenSigCycleTimeActive" SG_ 640 PBPositionLeverCopy 100;
BA_ "GenSigStartValue" SG_ 640 PBPositionLeverCopy 63;
BA_ "GenSigCycleTime" SG_ 640 DynamicPB_ActiveStatus 100;
BA_ "GenSigCycleTimeActive" SG_ 640 DynamicPB_ActiveStatus 100;
BA_ "GenSigStartValue" SG_ 640 DynamicPB_ActiveStatus 7;
BA_ "GenSigCycleTime" SG_ 640 PBStatus_CRC_ISig_3 100;
BA_ "GenSigCycleTimeActive" SG_ 640 PBStatus_CRC_ISig_3 100;
BA_ "GenSigStartValue" SG_ 640 PBStatus_CRC_ISig_3 255;
BA_ "GenSigMaxLatency" SG_ 640 PBStatus_CRC_ISig_3 100;
BA_ "E2EDataId" SG_ 640 PBStatus_CRC_ISig_3 107;
BA_ "E2EDataLength" SG_ 640 PBStatus_CRC_ISig_3 24;
BA_ "E2EProfile" SG_ 640 PBStatus_CRC_ISig_3 "P01";
BA_ "GenSigCycleTime" SG_ 640 PBAirLvl_AntiCompoundRatio 100;
BA_ "GenSigCycleTimeActive" SG_ 640 PBAirLvl_AntiCompoundRatio 100;
BA_ "GenSigStartValue" SG_ 640 PBAirLvl_AntiCompoundRatio 255;
BA_ "GenSigMaxLatency" SG_ 640 PBAirLvl_AntiCompoundRatio 100;
BA_ "GenSigCycleTime" SG_ 640 PB2HCUAreaCopy 100;
BA_ "GenSigCycleTimeActive" SG_ 640 PB2HCUAreaCopy 100;
BA_ "GenSigStartValue" SG_ 640 PB2HCUAreaCopy 7;
BA_ "GenSigCycleTime" SG_ 640 PBStatus_SqC_ISig_3 100;
BA_ "GenSigCycleTimeActive" SG_ 640 PBStatus_SqC_ISig_3 100;
BA_ "GenSigStartValue" SG_ 640 PBStatus_SqC_ISig_3 14;
BA_ "GenSigMaxLatency" SG_ 640 PBStatus_SqC_ISig_3 100;
BA_ "GenSigCycleTime" SG_ 640 TrailerStatus_Actuation_ISig_3 100;
BA_ "GenSigCycleTimeActive" SG_ 640 TrailerStatus_Actuation_ISig_3 100;
BA_ "GenSigStartValue" SG_ 640 TrailerStatus_Actuation_ISig_3 7;
BA_ "GenSigCycleTime" SG_ 640 RedGladHand_ConnectStatus_ISig_3 100;
BA_ "GenSigCycleTimeActive" SG_ 640 RedGladHand_ConnectStatus_ISig_3 100;
BA_ "GenSigStartValue" SG_ 640 RedGladHand_ConnectStatus_ISig_3 3;
BA_ "GenSigCycleTime" SG_ 640 PBHCUAreaCopy 100;
BA_ "GenSigCycleTimeActive" SG_ 640 PBHCUAreaCopy 100;
BA_ "GenSigStartValue" SG_ 640 PBHCUAreaCopy 7;
BA_ "GenSigCycleTime" SG_ 640 PBStatus_IntegrityLvl_ISig_3 100;
BA_ "GenSigCycleTimeActive" SG_ 640 PBStatus_IntegrityLvl_ISig_3 100;
BA_ "GenSigStartValue" SG_ 640 PBStatus_IntegrityLvl_ISig_3 3;
BA_ "GenSigMaxLatency" SG_ 640 PBStatus_IntegrityLvl_ISig_3 100;
BA_ "GenSigCycleTime" SG_ 640 TrPositionLeverCopy 100;
BA_ "GenSigCycleTimeActive" SG_ 640 TrPositionLeverCopy 100;
BA_ "GenSigStartValue" SG_ 640 TrPositionLeverCopy 63;
BA_ "GenSigCycleTime" SG_ 640 AutoPBRelease_stat_ISig_3 100;
BA_ "GenSigCycleTimeActive" SG_ 640 AutoPBRelease_stat_ISig_3 100;
BA_ "GenSigStartValue" SG_ 640 AutoPBRelease_stat_ISig_3 3;
BA_ "GenSigCycleTime" SG_ 640 APMSafetyWarning_CRC_ISig_3 100;
BA_ "GenSigCycleTimeActive" SG_ 640 APMSafetyWarning_CRC_ISig_3 100;
BA_ "GenSigStartValue" SG_ 640 APMSafetyWarning_CRC_ISig_3 255;
BA_ "E2EDataId" SG_ 640 APMSafetyWarning_CRC_ISig_3 181;
BA_ "E2EDataLength" SG_ 640 APMSafetyWarning_CRC_ISig_3 16;
BA_ "E2EProfile" SG_ 640 APMSafetyWarning_CRC_ISig_3 "P01";
BA_ "GenSigCycleTime" SG_ 640 TrHCUAreaCopy 100;
BA_ "GenSigCycleTimeActive" SG_ 640 TrHCUAreaCopy 100;
BA_ "GenSigStartValue" SG_ 640 TrHCUAreaCopy 7;
BA_ "GenSigCycleTime" SG_ 640 DynamicPB_SqC 100;
BA_ "GenSigCycleTimeActive" SG_ 640 DynamicPB_SqC 100;
BA_ "GenSigCycleTime" SG_ 640 RedGladHand_CRC_ISig_3 100;
BA_ "GenSigCycleTimeActive" SG_ 640 RedGladHand_CRC_ISig_3 100;
BA_ "GenSigStartValue" SG_ 640 RedGladHand_CRC_ISig_3 255;
BA_ "E2EDataId" SG_ 640 RedGladHand_CRC_ISig_3 146;
BA_ "E2EDataLength" SG_ 640 RedGladHand_CRC_ISig_3 16;
BA_ "E2EProfile" SG_ 640 RedGladHand_CRC_ISig_3 "P01";
BA_ "GenSigCycleTime" SG_ 640 TrailerSupplyInflationMode 100;
BA_ "GenSigCycleTimeActive" SG_ 640 TrailerSupplyInflationMode 100;
BA_ "GenSigStartValue" SG_ 640 TrailerSupplyInflationMode 15;
BA_ "GenSigCycleTime" SG_ 640 DynamicPB_CRC 100;
BA_ "GenSigCycleTimeActive" SG_ 640 DynamicPB_CRC 100;
BA_ "E2EDataId" SG_ 640 DynamicPB_CRC 320;
BA_ "E2EDataLength" SG_ 640 DynamicPB_CRC 16;
BA_ "E2EProfile" SG_ 640 DynamicPB_CRC "P01";
BA_ "GenSigCycleTime" SG_ 640 TLInflationAcceptance_stat_ISig_ 100;
BA_ "GenSigCycleTimeActive" SG_ 640 TLInflationAcceptance_stat_ISig_ 100;
BA_ "GenSigStartValue" SG_ 640 TLInflationAcceptance_stat_ISig_ 7;
BA_ "SystemSignalLongSymbol" SG_ 640 TLInflationAcceptance_stat_ISig_ "TLInflationAcceptance_stat_ISig_3";
BA_ "GenSigCycleTime" SG_ 640 TrailerInflationPossible_stat_IS 100;
BA_ "GenSigCycleTimeActive" SG_ 640 TrailerInflationPossible_stat_IS 100;
BA_ "GenSigStartValue" SG_ 640 TrailerInflationPossible_stat_IS 3;
BA_ "SystemSignalLongSymbol" SG_ 640 TrailerInflationPossible_stat_IS "TrailerInflationPossible_stat_ISig_3";
BA_ "GenSigCycleTime" SG_ 640 SecondRVAirPressure_Out 100;
BA_ "GenSigCycleTimeActive" SG_ 640 SecondRVAirPressure_Out 100;
BA_ "GenSigStartValue" SG_ 640 SecondRVAirPressure_Out 255;
BA_ "GenSigCycleTime" SG_ 640 APMSafetyWarning_RedRqst_ISig_3 100;
BA_ "GenSigCycleTimeActive" SG_ 640 APMSafetyWarning_RedRqst_ISig_3 100;
BA_ "GenSigStartValue" SG_ 640 APMSafetyWarning_RedRqst_ISig_3 3;
BA_ "GenSigCycleTime" SG_ 640 PBAirLvl_CRC 100;
BA_ "GenSigCycleTimeActive" SG_ 640 PBAirLvl_CRC 100;
BA_ "GenSigStartValue" SG_ 640 PBAirLvl_CRC 255;
BA_ "GenSigMaxLatency" SG_ 640 PBAirLvl_CRC 100;
BA_ "E2EDataId" SG_ 640 PBAirLvl_CRC 108;
BA_ "E2EDataLength" SG_ 640 PBAirLvl_CRC 32;
BA_ "E2EProfile" SG_ 640 PBAirLvl_CRC "P01";
BA_ "GenSigCycleTime" SG_ 640 RedGladHand_ConfidenceLvl_ISig_3 100;
BA_ "GenSigCycleTimeActive" SG_ 640 RedGladHand_ConfidenceLvl_ISig_3 100;
BA_ "GenSigStartValue" SG_ 640 RedGladHand_ConfidenceLvl_ISig_3 3;
BA_ "GenSigCycleTime" SG_ 640 TrailerSupplyDeflationMode 100;
BA_ "GenSigCycleTimeActive" SG_ 640 TrailerSupplyDeflationMode 100;
BA_ "GenSigStartValue" SG_ 640 TrailerSupplyDeflationMode 15;
BA_ "GenSigCycleTime" SG_ 640 APMSafetyWarning_SqC_ISig_3 100;
BA_ "GenSigCycleTimeActive" SG_ 640 APMSafetyWarning_SqC_ISig_3 100;
BA_ "GenSigStartValue" SG_ 640 APMSafetyWarning_SqC_ISig_3 14;
BA_ "GenSigCycleTime" SG_ 640 AirProdPressureRangeModeStatus 100;
BA_ "GenSigCycleTimeActive" SG_ 640 AirProdPressureRangeModeStatus 100;
BA_ "GenSigStartValue" SG_ 640 AirProdPressureRangeModeStatus 15;
BA_ "GenSigCycleTime" SG_ 640 PB2PositionLeverCopy 100;
BA_ "GenSigCycleTimeActive" SG_ 640 PB2PositionLeverCopy 100;
BA_ "GenSigStartValue" SG_ 640 PB2PositionLeverCopy 63;
BA_ "GenSigCycleTime" SG_ 640 PBAirLvl_PressureInChamber 100;
BA_ "GenSigCycleTimeActive" SG_ 640 PBAirLvl_PressureInChamber 100;
BA_ "GenSigStartValue" SG_ 640 PBAirLvl_PressureInChamber 255;
BA_ "GenSigMaxLatency" SG_ 640 PBAirLvl_PressureInChamber 100;
BA_ "GenSigCycleTime" SG_ 640 PBStatus_Actuation_ISig_3 100;
BA_ "GenSigCycleTimeActive" SG_ 640 PBStatus_Actuation_ISig_3 100;
BA_ "GenSigStartValue" SG_ 640 PBStatus_Actuation_ISig_3 7;
BA_ "GenSigMaxLatency" SG_ 640 PBStatus_Actuation_ISig_3 100;
BA_ "GenSigCycleTime" SG_ 640 TrailerStatus_SqC_ISig_3 100;
BA_ "GenSigCycleTimeActive" SG_ 640 TrailerStatus_SqC_ISig_3 100;
BA_ "GenSigStartValue" SG_ 640 TrailerStatus_SqC_ISig_3 14;
BA_ "GenSigCycleTime" SG_ 386 RGHDetect_CRC 100;
BA_ "GenSigCycleTimeActive" SG_ 386 RGHDetect_CRC 100;
BA_ "E2EDataId" SG_ 386 RGHDetect_CRC 165;
BA_ "E2EDataLength" SG_ 386 RGHDetect_CRC 16;
BA_ "E2EProfile" SG_ 386 RGHDetect_CRC "P01";
BA_ "GenSigCycleTime" SG_ 386 ParkBrakeChamberAirPressure 100;
BA_ "GenSigCycleTimeActive" SG_ 386 ParkBrakeChamberAirPressure 100;
BA_ "GenSigStartValue" SG_ 386 ParkBrakeChamberAirPressure 255;
BA_ "GenSigCycleTime" SG_ 386 XPRGSystemState_AppliedPriority 100;
BA_ "GenSigCycleTimeActive" SG_ 386 XPRGSystemState_AppliedPriority 100;
BA_ "GenSigStartValue" SG_ 386 XPRGSystemState_AppliedPriority 15;
BA_ "GenSigCycleTime" SG_ 386 UnLoaderValveStatus 100;
BA_ "GenSigCycleTimeActive" SG_ 386 UnLoaderValveStatus 100;
BA_ "GenSigStartValue" SG_ 386 UnLoaderValveStatus 3;
BA_ "GenSigCycleTime" SG_ 386 XPRGSystemCap_SqC_ISig_3 100;
BA_ "GenSigCycleTimeActive" SG_ 386 XPRGSystemCap_SqC_ISig_3 100;
BA_ "GenSigStartValue" SG_ 386 XPRGSystemCap_SqC_ISig_3 14;
BA_ "GenSigCycleTime" SG_ 386 PBStatusDisplay_cmd_ISig_3 100;
BA_ "GenSigCycleTimeActive" SG_ 386 PBStatusDisplay_cmd_ISig_3 100;
BA_ "GenSigStartValue" SG_ 386 PBStatusDisplay_cmd_ISig_3 3;
BA_ "GenSigCycleTime" SG_ 386 ParkBrakeApplicationMode2_ISig_3 100;
BA_ "GenSigCycleTimeActive" SG_ 386 ParkBrakeApplicationMode2_ISig_3 100;
BA_ "GenSigStartValue" SG_ 386 ParkBrakeApplicationMode2_ISig_3 15;
BA_ "GenSigCycleTime" SG_ 386 XPRGSystemState_CRC 100;
BA_ "GenSigCycleTimeActive" SG_ 386 XPRGSystemState_CRC 100;
BA_ "GenSigStartValue" SG_ 386 XPRGSystemState_CRC 255;
BA_ "E2EDataId" SG_ 386 XPRGSystemState_CRC 145;
BA_ "E2EDataLength" SG_ 386 XPRGSystemState_CRC 16;
BA_ "E2EProfile" SG_ 386 XPRGSystemState_CRC "P01";
BA_ "GenSigCycleTime" SG_ 386 XPRGSystemCap_AllowedGradCtrlTl_ 100;
BA_ "GenSigCycleTimeActive" SG_ 386 XPRGSystemCap_AllowedGradCtrlTl_ 100;
BA_ "SystemSignalLongSymbol" SG_ 386 XPRGSystemCap_AllowedGradCtrlTl_ "XPRGSystemCap_AllowedGradCtrlTl_ISig_3";
BA_ "GenSigCycleTime" SG_ 386 XPRGSystemCap_AllowedGradCtrlTc_ 100;
BA_ "GenSigCycleTimeActive" SG_ 386 XPRGSystemCap_AllowedGradCtrlTc_ 100;
BA_ "SystemSignalLongSymbol" SG_ 386 XPRGSystemCap_AllowedGradCtrlTc_ "XPRGSystemCap_AllowedGradCtrlTc_ISig_3";
BA_ "GenSigCycleTime" SG_ 386 XPRGSystemCap_AllowedRelInhibit_ 100;
BA_ "GenSigCycleTimeActive" SG_ 386 XPRGSystemCap_AllowedRelInhibit_ 100;
BA_ "GenSigStartValue" SG_ 386 XPRGSystemCap_AllowedRelInhibit_ 7;
BA_ "SystemSignalLongSymbol" SG_ 386 XPRGSystemCap_AllowedRelInhibit_ "XPRGSystemCap_AllowedRelInhibit_ISig_3";
BA_ "GenSigCycleTime" SG_ 386 ParkBrakeReleasePossible_stat_IS 100;
BA_ "GenSigCycleTimeActive" SG_ 386 ParkBrakeReleasePossible_stat_IS 100;
BA_ "GenSigStartValue" SG_ 386 ParkBrakeReleasePossible_stat_IS 3;
BA_ "SystemSignalLongSymbol" SG_ 386 ParkBrakeReleasePossible_stat_IS "ParkBrakeReleasePossible_stat_ISig_3";
BA_ "GenSigCycleTime" SG_ 386 PBReleaseAcceptance_stat_ISig_3 100;
BA_ "GenSigCycleTimeActive" SG_ 386 PBReleaseAcceptance_stat_ISig_3 100;
BA_ "GenSigStartValue" SG_ 386 PBReleaseAcceptance_stat_ISig_3 7;
BA_ "GenSigCycleTime" SG_ 386 AirCompressorStatus_ISig_3 100;
BA_ "GenSigCycleTimeActive" SG_ 386 AirCompressorStatus_ISig_3 100;
BA_ "GenSigStartValue" SG_ 386 AirCompressorStatus_ISig_3 3;
BA_ "GenSigCycleTime" SG_ 386 RGHDetect_SqC 100;
BA_ "GenSigCycleTimeActive" SG_ 386 RGHDetect_SqC 100;
BA_ "GenSigCycleTime" SG_ 386 TrailerTest_stat_ISig_3 100;
BA_ "GenSigCycleTimeActive" SG_ 386 TrailerTest_stat_ISig_3 100;
BA_ "GenSigStartValue" SG_ 386 TrailerTest_stat_ISig_3 7;
BA_ "GenSigCycleTime" SG_ 386 XPRGSystemState_SqC 100;
BA_ "GenSigCycleTimeActive" SG_ 386 XPRGSystemState_SqC 100;
BA_ "GenSigStartValue" SG_ 386 XPRGSystemState_SqC 14;
BA_ "GenSigCycleTime" SG_ 386 PoorAirPressureInfo_ISig_3 100;
BA_ "GenSigCycleTimeActive" SG_ 386 PoorAirPressureInfo_ISig_3 100;
BA_ "GenSigStartValue" SG_ 386 PoorAirPressureInfo_ISig_3 3;
BA_ "GenSigCycleTime" SG_ 386 RGHDetect_ActiveProcess 100;
BA_ "GenSigCycleTimeActive" SG_ 386 RGHDetect_ActiveProcess 100;
BA_ "GenSigStartValue" SG_ 386 RGHDetect_ActiveProcess 3;
BA_ "GenSigCycleTime" SG_ 386 XPRGSystemCap_Priority_ISig_3 100;
BA_ "GenSigCycleTimeActive" SG_ 386 XPRGSystemCap_Priority_ISig_3 100;
BA_ "GenSigStartValue" SG_ 386 XPRGSystemCap_Priority_ISig_3 7;
BA_ "GenSigCycleTime" SG_ 386 XPRGSystemCap_AllowedPBApp_ISig_ 100;
BA_ "GenSigCycleTimeActive" SG_ 386 XPRGSystemCap_AllowedPBApp_ISig_ 100;
BA_ "SystemSignalLongSymbol" SG_ 386 XPRGSystemCap_AllowedPBApp_ISig_ "XPRGSystemCap_AllowedPBApp_ISig_3";
BA_ "GenSigCycleTime" SG_ 386 XPRGSystemCap_AllowedPBRel_ISig_ 100;
BA_ "GenSigCycleTimeActive" SG_ 386 XPRGSystemCap_AllowedPBRel_ISig_ 100;
BA_ "SystemSignalLongSymbol" SG_ 386 XPRGSystemCap_AllowedPBRel_ISig_ "XPRGSystemCap_AllowedPBRel_ISig_3";
BA_ "GenSigCycleTime" SG_ 386 AirProductionRqst 100;
BA_ "GenSigCycleTimeActive" SG_ 386 AirProductionRqst 100;
BA_ "GenSigStartValue" SG_ 386 AirProductionRqst 3;
BA_ "GenSigCycleTime" SG_ 386 XPRGSystemCap_AllowedDeflation_I 100;
BA_ "GenSigCycleTimeActive" SG_ 386 XPRGSystemCap_AllowedDeflation_I 100;
BA_ "SystemSignalLongSymbol" SG_ 386 XPRGSystemCap_AllowedDeflation_I "XPRGSystemCap_AllowedDeflation_ISig_3";
BA_ "GenSigCycleTime" SG_ 386 XPRGSystemCap_AllowedInflation_I 100;
BA_ "GenSigCycleTimeActive" SG_ 386 XPRGSystemCap_AllowedInflation_I 100;
BA_ "SystemSignalLongSymbol" SG_ 386 XPRGSystemCap_AllowedInflation_I "XPRGSystemCap_AllowedInflation_ISig_3";
BA_ "GenSigCycleTime" SG_ 386 EPBHSARequest 100;
BA_ "GenSigCycleTimeActive" SG_ 386 EPBHSARequest 100;
BA_ "GenSigStartValue" SG_ 386 EPBHSARequest 7;
BA_ "GenSigMaxLatency" SG_ 386 EPBHSARequest 50;
BA_ "GenSigCycleTime" SG_ 386 XPRGSystemCap_AllowedInfInhibit_ 100;
BA_ "GenSigCycleTimeActive" SG_ 386 XPRGSystemCap_AllowedInfInhibit_ 100;
BA_ "GenSigStartValue" SG_ 386 XPRGSystemCap_AllowedInfInhibit_ 7;
BA_ "SystemSignalLongSymbol" SG_ 386 XPRGSystemCap_AllowedInfInhibit_ "XPRGSystemCap_AllowedInfInhibit_ISig_3";
BA_ "GenSigCycleTime" SG_ 386 XPRGSystemCap_CRC_ISig_3 100;
BA_ "GenSigCycleTimeActive" SG_ 386 XPRGSystemCap_CRC_ISig_3 100;
BA_ "GenSigStartValue" SG_ 386 XPRGSystemCap_CRC_ISig_3 255;
BA_ "E2EDataId" SG_ 386 XPRGSystemCap_CRC_ISig_3 144;
BA_ "E2EDataLength" SG_ 386 XPRGSystemCap_CRC_ISig_3 32;
BA_ "E2EProfile" SG_ 386 XPRGSystemCap_CRC_ISig_3 "P01";
BA_ "GenSigCycleTime" SG_ 260 OverrunMode_stat 100;
BA_ "GenSigCycleTimeActive" SG_ 260 OverrunMode_stat 100;
BA_ "GenSigStartValue" SG_ 260 OverrunMode_stat 3;
BA_ "GenSigCycleTime" SG_ 260 EPBPowerFeedRequest_ISig_3 100;
BA_ "GenSigCycleTimeActive" SG_ 260 EPBPowerFeedRequest_ISig_3 100;
BA_ "GenSigStartValue" SG_ 260 EPBPowerFeedRequest_ISig_3 3;
BA_ "GenSigCycleTime" SG_ 260 AirDryerCurrentAirVolNotRegen 100;
BA_ "GenSigCycleTimeActive" SG_ 260 AirDryerCurrentAirVolNotRegen 100;
BA_ "GenSigStartValue" SG_ 260 AirDryerCurrentAirVolNotRegen 255;
BA_ "GenSigCycleTime" SG_ 260 ParkBrakeReleaseMode2_ISig_3 100;
BA_ "GenSigCycleTimeActive" SG_ 260 ParkBrakeReleaseMode2_ISig_3 100;
BA_ "GenSigStartValue" SG_ 260 ParkBrakeReleaseMode2_ISig_3 15;
BA_ "GenSigMaxLatency" SG_ 260 ParkBrakeReleaseMode2_ISig_3 30;
BA_ "GenSigCycleTime" SG_ 260 LowVMPBInfoReq 100;
BA_ "GenSigCycleTimeActive" SG_ 260 LowVMPBInfoReq 100;
BA_ "GenSigStartValue" SG_ 260 LowVMPBInfoReq 7;
BA_ "GenSigCycleTime" SG_ 260 ParkBrakeWorkshopMode_ISig_3 100;
BA_ "GenSigCycleTimeActive" SG_ 260 ParkBrakeWorkshopMode_ISig_3 100;
BA_ "GenSigStartValue" SG_ 260 ParkBrakeWorkshopMode_ISig_3 3;
BA_ "GenSigCycleTime" SG_ 260 AirDryerCartridgeReset_ack 100;
BA_ "GenSigCycleTimeActive" SG_ 260 AirDryerCartridgeReset_ack 100;
BA_ "GenSigStartValue" SG_ 260 AirDryerCartridgeReset_ack 3;
BA_ "GenSigCycleTime" SG_ 256 XBRPB_Priority 100;
BA_ "GenSigCycleTimeActive" SG_ 256 XBRPB_Priority 100;
BA_ "GenSigStartValue" SG_ 256 XBRPB_Priority 3;
BA_ "GenSigCycleTime" SG_ 256 ParkingBrake_stat_ISig_3 100;
BA_ "GenSigCycleTimeActive" SG_ 256 ParkingBrake_stat_ISig_3 100;
BA_ "GenSigStartValue" SG_ 256 ParkingBrake_stat_ISig_3 3;
BA_ "GenSigMaxLatency" SG_ 256 ParkingBrake_stat_ISig_3 20;
BA_ "GenSigCycleTime" SG_ 256 XBRPB_CompensationMode 100;
BA_ "GenSigCycleTimeActive" SG_ 256 XBRPB_CompensationMode 100;
BA_ "GenSigStartValue" SG_ 256 XBRPB_CompensationMode 3;
BA_ "GenSigCycleTime" SG_ 256 XBRPB_EBIMode 100;
BA_ "GenSigCycleTimeActive" SG_ 256 XBRPB_EBIMode 100;
BA_ "GenSigStartValue" SG_ 256 XBRPB_EBIMode 3;
BA_ "GenSigCycleTime" SG_ 256 XBRPB_SqC 100;
BA_ "GenSigCycleTimeActive" SG_ 256 XBRPB_SqC 100;
BA_ "GenSigStartValue" SG_ 256 XBRPB_SqC 14;
BA_ "GenSigCycleTime" SG_ 256 XBRPB_CRC 100;
BA_ "GenSigCycleTimeActive" SG_ 256 XBRPB_CRC 100;
BA_ "GenSigStartValue" SG_ 256 XBRPB_CRC 255;
BA_ "E2EDataId" SG_ 256 XBRPB_CRC 180;
BA_ "E2EDataLength" SG_ 256 XBRPB_CRC 48;
BA_ "E2EProfile" SG_ 256 XBRPB_CRC "P01";
BA_ "GenSigCycleTime" SG_ 256 XBRPB_ExtAccelDemand 100;
BA_ "GenSigCycleTimeActive" SG_ 256 XBRPB_ExtAccelDemand 100;
BA_ "GenSigStartValue" SG_ 256 XBRPB_ExtAccelDemand 65535;
BA_ "GenSigCycleTime" SG_ 256 ParkBrakeActuationStatus_ISig_3 100;
BA_ "GenSigCycleTimeActive" SG_ 256 ParkBrakeActuationStatus_ISig_3 100;
BA_ "GenSigStartValue" SG_ 256 ParkBrakeActuationStatus_ISig_3 7;
BA_ "GenSigCycleTime" SG_ 256 XBRPB_ControlMode 100;
BA_ "GenSigCycleTimeActive" SG_ 256 XBRPB_ControlMode 100;
BA_ "GenSigStartValue" SG_ 256 XBRPB_ControlMode 3;
BA_ "GenSigCycleTime" SG_ 256 XBRPB_Urgency 100;
BA_ "GenSigCycleTimeActive" SG_ 256 XBRPB_Urgency 100;
BA_ "GenSigStartValue" SG_ 256 XBRPB_Urgency 255;
BA_ "GenSigSendType" SG_ 480 ECU2VIN_stat 1;
BA_REL_ "GenSigFirstTimeoutTime" BU_SG_REL_ VCM SG_ 592 CpbtyAxle3_BrkEgyCpctyQltyLe 3000;
BA_REL_ "GenSigTimeoutTime" BU_SG_REL_ VCM SG_ 592 CpbtyAxle3_BrkEgyCpctyQltyLe 300;
BA_REL_ "GenSigFirstTimeoutTime" BU_SG_REL_ VCM SG_ 592 CpbtyAxle3_TqCpbtyRateIncLeLe 3000;
BA_REL_ "GenSigTimeoutTime" BU_SG_REL_ VCM SG_ 592 CpbtyAxle3_TqCpbtyRateIncLeLe 300;
BA_REL_ "GenSigFirstTimeoutTime" BU_SG_REL_ VCM SG_ 592 CpbtyAxle3_TqCpbtyRateQltyRi 3000;
BA_REL_ "GenSigTimeoutTime" BU_SG_REL_ VCM SG_ 592 CpbtyAxle3_TqCpbtyRateQltyRi 300;
BA_REL_ "GenSigFirstTimeoutTime" BU_SG_REL_ VCM SG_ 592 CpbtyAxle1_PadWearQltyLe 3000;
BA_REL_ "GenSigTimeoutTime" BU_SG_REL_ VCM SG_ 592 CpbtyAxle1_PadWearQltyLe 300;
BA_REL_ "GenSigFirstTimeoutTime" BU_SG_REL_ VCM SG_ 592 CpbtyAxle1_SlipCtrlEna 3000;
BA_REL_ "GenSigTimeoutTime" BU_SG_REL_ VCM SG_ 592 CpbtyAxle1_SlipCtrlEna 300;
BA_REL_ "GenSigFirstTimeoutTime" BU_SG_REL_ VCM SG_ 592 CpbtyAxle2_PadWearRi 3000;
BA_REL_ "GenSigTimeoutTime" BU_SG_REL_ VCM SG_ 592 CpbtyAxle2_PadWearRi 300;
BA_REL_ "GenSigFirstTimeoutTime" BU_SG_REL_ VCM SG_ 592 CpbtyAxle3_TqCpbtyRateQltyLe 3000;
BA_REL_ "GenSigTimeoutTime" BU_SG_REL_ VCM SG_ 592 CpbtyAxle3_TqCpbtyRateQltyLe 300;
BA_REL_ "GenSigFirstTimeoutTime" BU_SG_REL_ VCM SG_ 592 CpbtyAxle1_BrkEgyCpctyQltyRi 3000;
BA_REL_ "GenSigTimeoutTime" BU_SG_REL_ VCM SG_ 592 CpbtyAxle1_BrkEgyCpctyQltyRi 300;
BA_REL_ "GenSigFirstTimeoutTime" BU_SG_REL_ VCM SG_ 592 CpbtyAxle2_TqCpbtyMaxRi 3000;
BA_REL_ "GenSigTimeoutTime" BU_SG_REL_ VCM SG_ 592 CpbtyAxle2_TqCpbtyMaxRi 300;
BA_REL_ "GenSigFirstTimeoutTime" BU_SG_REL_ VCM SG_ 592 CpbtyAxle2_TqCpbtyMinLe 3000;
BA_REL_ "GenSigTimeoutTime" BU_SG_REL_ VCM SG_ 592 CpbtyAxle2_TqCpbtyMinLe 300;
BA_REL_ "GenSigFirstTimeoutTime" BU_SG_REL_ VCM SG_ 592 CpbtyAxle2_BrkEgyCpctyQltyLe 3000;
BA_REL_ "GenSigTimeoutTime" BU_SG_REL_ VCM SG_ 592 CpbtyAxle2_BrkEgyCpctyQltyLe 300;
BA_REL_ "GenSigFirstTimeoutTime" BU_SG_REL_ VCM SG_ 592 CpbtyAxle2_TqCpbtyRateDecLe 3000;
BA_REL_ "GenSigTimeoutTime" BU_SG_REL_ VCM SG_ 592 CpbtyAxle2_TqCpbtyRateDecLe 300;
BA_REL_ "GenSigFirstTimeoutTime" BU_SG_REL_ VCM SG_ 592 CpbtyAxle3_SlipCtrlEna 3000;
BA_REL_ "GenSigTimeoutTime" BU_SG_REL_ VCM SG_ 592 CpbtyAxle3_SlipCtrlEna 300;
BA_REL_ "GenSigFirstTimeoutTime" BU_SG_REL_ VCM SG_ 592 CpbtyAxle3_TqCpbtyQltyLe 3000;
BA_REL_ "GenSigTimeoutTime" BU_SG_REL_ VCM SG_ 592 CpbtyAxle3_TqCpbtyQltyLe 300;
BA_REL_ "GenSigFirstTimeoutTime" BU_SG_REL_ VCM SG_ 592 CpbtyAxle3_BrkEgyCpctyRi 3000;
BA_REL_ "GenSigTimeoutTime" BU_SG_REL_ VCM SG_ 592 CpbtyAxle3_BrkEgyCpctyRi 300;
BA_REL_ "GenSigFirstTimeoutTime" BU_SG_REL_ VCM SG_ 592 CpbtyAxle1_SqC 3000;
BA_REL_ "GenSigTimeoutTime" BU_SG_REL_ VCM SG_ 592 CpbtyAxle1_SqC 300;
BA_REL_ "GenSigFirstTimeoutTime" BU_SG_REL_ VCM SG_ 592 CpbtyAxle1_TqCpbtyQltyLe 3000;
BA_REL_ "GenSigTimeoutTime" BU_SG_REL_ VCM SG_ 592 CpbtyAxle1_TqCpbtyQltyLe 300;
BA_REL_ "GenSigFirstTimeoutTime" BU_SG_REL_ VCM SG_ 592 CpbtyAxle2_TqCpbtyRateDecRi 3000;
BA_REL_ "GenSigTimeoutTime" BU_SG_REL_ VCM SG_ 592 CpbtyAxle2_TqCpbtyRateDecRi 300;
BA_REL_ "GenSigFirstTimeoutTime" BU_SG_REL_ VCM SG_ 592 CpbtyAxle1_TqCpbtyRateIncLeLe 3000;
BA_REL_ "GenSigTimeoutTime" BU_SG_REL_ VCM SG_ 592 CpbtyAxle1_TqCpbtyRateIncLeLe 300;
BA_REL_ "GenSigFirstTimeoutTime" BU_SG_REL_ VCM SG_ 592 CpbtyAxle3_BrkEgyCpctyQltyRi 3000;
BA_REL_ "GenSigTimeoutTime" BU_SG_REL_ VCM SG_ 592 CpbtyAxle3_BrkEgyCpctyQltyRi 300;
BA_REL_ "GenSigFirstTimeoutTime" BU_SG_REL_ VCM SG_ 592 CpbtyAxle3_TqCpbtyRateDecLe 3000;
BA_REL_ "GenSigTimeoutTime" BU_SG_REL_ VCM SG_ 592 CpbtyAxle3_TqCpbtyRateDecLe 300;
BA_REL_ "GenSigFirstTimeoutTime" BU_SG_REL_ VCM SG_ 592 CpbtyAxle3_TqCpbtyRateDecRi 3000;
BA_REL_ "GenSigTimeoutTime" BU_SG_REL_ VCM SG_ 592 CpbtyAxle3_TqCpbtyRateDecRi 300;
BA_REL_ "GenSigFirstTimeoutTime" BU_SG_REL_ VCM SG_ 592 CpbtyAxle1_PadWearRi 3000;
BA_REL_ "GenSigTimeoutTime" BU_SG_REL_ VCM SG_ 592 CpbtyAxle1_PadWearRi 300;
BA_REL_ "GenSigFirstTimeoutTime" BU_SG_REL_ VCM SG_ 592 CpbtyAxle2_TqCpbtyMaxLe 3000;
BA_REL_ "GenSigTimeoutTime" BU_SG_REL_ VCM SG_ 592 CpbtyAxle2_TqCpbtyMaxLe 300;
BA_REL_ "GenSigFirstTimeoutTime" BU_SG_REL_ VCM SG_ 592 CpbtyAxle3_TqCpbtyQltyRi 3000;
BA_REL_ "GenSigTimeoutTime" BU_SG_REL_ VCM SG_ 592 CpbtyAxle3_TqCpbtyQltyRi 300;
BA_REL_ "GenSigFirstTimeoutTime" BU_SG_REL_ VCM SG_ 592 CpbtyAxle1_TqCpbtyRateDecLe 3000;
BA_REL_ "GenSigTimeoutTime" BU_SG_REL_ VCM SG_ 592 CpbtyAxle1_TqCpbtyRateDecLe 300;
BA_REL_ "GenSigFirstTimeoutTime" BU_SG_REL_ VCM SG_ 592 CpbtyAxle1_BrkEgyCpctyRi 3000;
BA_REL_ "GenSigTimeoutTime" BU_SG_REL_ VCM SG_ 592 CpbtyAxle1_BrkEgyCpctyRi 300;
BA_REL_ "GenSigFirstTimeoutTime" BU_SG_REL_ VCM SG_ 592 CpbtyAxle3_TqCpbtyMinLe 3000;
BA_REL_ "GenSigTimeoutTime" BU_SG_REL_ VCM SG_ 592 CpbtyAxle3_TqCpbtyMinLe 300;
BA_REL_ "GenSigFirstTimeoutTime" BU_SG_REL_ VCM SG_ 592 CpbtyAxle3_TqCpbtyMinRi 3000;
BA_REL_ "GenSigTimeoutTime" BU_SG_REL_ VCM SG_ 592 CpbtyAxle3_TqCpbtyMinRi 300;
BA_REL_ "GenSigFirstTimeoutTime" BU_SG_REL_ VCM SG_ 592 CpbtyAxle2_BrkEgyCpctyQltyRi 3000;
BA_REL_ "GenSigTimeoutTime" BU_SG_REL_ VCM SG_ 592 CpbtyAxle2_BrkEgyCpctyQltyRi 300;
BA_REL_ "GenSigFirstTimeoutTime" BU_SG_REL_ VCM SG_ 592 CpbtyAxle2_PadWearLe 3000;
BA_REL_ "GenSigTimeoutTime" BU_SG_REL_ VCM SG_ 592 CpbtyAxle2_PadWearLe 300;
BA_REL_ "GenSigFirstTimeoutTime" BU_SG_REL_ VCM SG_ 592 CpbtyAxle2_TqCpbtyQltyRi 3000;
BA_REL_ "GenSigTimeoutTime" BU_SG_REL_ VCM SG_ 592 CpbtyAxle2_TqCpbtyQltyRi 300;
BA_REL_ "GenSigFirstTimeoutTime" BU_SG_REL_ VCM SG_ 592 CpbtyAxle2_PadWearQltyRi 3000;
BA_REL_ "GenSigTimeoutTime" BU_SG_REL_ VCM SG_ 592 CpbtyAxle2_PadWearQltyRi 300;
BA_REL_ "GenSigFirstTimeoutTime" BU_SG_REL_ VCM SG_ 592 CpbtyAxle3_PadWearRi 3000;
BA_REL_ "GenSigTimeoutTime" BU_SG_REL_ VCM SG_ 592 CpbtyAxle3_PadWearRi 300;
BA_REL_ "GenSigFirstTimeoutTime" BU_SG_REL_ VCM SG_ 592 CpbtyAxle3_PadWearQltyRi 3000;
BA_REL_ "GenSigTimeoutTime" BU_SG_REL_ VCM SG_ 592 CpbtyAxle3_PadWearQltyRi 300;
BA_REL_ "GenSigFirstTimeoutTime" BU_SG_REL_ VCM SG_ 592 CpbtyAxle1_TqCpbtyMaxRi 3000;
BA_REL_ "GenSigTimeoutTime" BU_SG_REL_ VCM SG_ 592 CpbtyAxle1_TqCpbtyMaxRi 300;
BA_REL_ "GenSigFirstTimeoutTime" BU_SG_REL_ VCM SG_ 592 CpbtyAxle2_TqCpbtyRateQltyRi 3000;
BA_REL_ "GenSigTimeoutTime" BU_SG_REL_ VCM SG_ 592 CpbtyAxle2_TqCpbtyRateQltyRi 300;
BA_REL_ "GenSigFirstTimeoutTime" BU_SG_REL_ VCM SG_ 592 CpbtyAxle1_BrkEgyCpctyLe 3000;
BA_REL_ "GenSigTimeoutTime" BU_SG_REL_ VCM SG_ 592 CpbtyAxle1_BrkEgyCpctyLe 300;
BA_REL_ "GenSigFirstTimeoutTime" BU_SG_REL_ VCM SG_ 592 CpbtyAxle2_SlipCtrlEna 3000;
BA_REL_ "GenSigTimeoutTime" BU_SG_REL_ VCM SG_ 592 CpbtyAxle2_SlipCtrlEna 300;
BA_REL_ "GenSigFirstTimeoutTime" BU_SG_REL_ VCM SG_ 592 CpbtyAxle1_TqCpbtyRateIncLeRi 3000;
BA_REL_ "GenSigTimeoutTime" BU_SG_REL_ VCM SG_ 592 CpbtyAxle1_TqCpbtyRateIncLeRi 300;
BA_REL_ "GenSigFirstTimeoutTime" BU_SG_REL_ VCM SG_ 592 CpbtyAxle2_TqCpbtyMinRi 3000;
BA_REL_ "GenSigTimeoutTime" BU_SG_REL_ VCM SG_ 592 CpbtyAxle2_TqCpbtyMinRi 300;
BA_REL_ "GenSigFirstTimeoutTime" BU_SG_REL_ VCM SG_ 592 CpbtyAxle3_TqCpbtyMaxLe 3000;
BA_REL_ "GenSigTimeoutTime" BU_SG_REL_ VCM SG_ 592 CpbtyAxle3_TqCpbtyMaxLe 300;
BA_REL_ "GenSigFirstTimeoutTime" BU_SG_REL_ VCM SG_ 592 CpbtyAxle1_TqCpbtyRateQltyRi 3000;
BA_REL_ "GenSigTimeoutTime" BU_SG_REL_ VCM SG_ 592 CpbtyAxle1_TqCpbtyRateQltyRi 300;
BA_REL_ "GenSigFirstTimeoutTime" BU_SG_REL_ VCM SG_ 592 CpbtyAxle1_CRC 3000;
BA_REL_ "GenSigTimeoutTime" BU_SG_REL_ VCM SG_ 592 CpbtyAxle1_CRC 300;
BA_REL_ "GenSigFirstTimeoutTime" BU_SG_REL_ VCM SG_ 592 CpbtyAxle1_PadWearQltyRi 3000;
BA_REL_ "GenSigTimeoutTime" BU_SG_REL_ VCM SG_ 592 CpbtyAxle1_PadWearQltyRi 300;
BA_REL_ "GenSigFirstTimeoutTime" BU_SG_REL_ VCM SG_ 592 CpbtyAxle2_CRC 3000;
BA_REL_ "GenSigTimeoutTime" BU_SG_REL_ VCM SG_ 592 CpbtyAxle2_CRC 300;
BA_REL_ "GenSigFirstTimeoutTime" BU_SG_REL_ VCM SG_ 592 CpbtyAxle2_SqC 3000;
BA_REL_ "GenSigTimeoutTime" BU_SG_REL_ VCM SG_ 592 CpbtyAxle2_SqC 300;
BA_REL_ "GenSigFirstTimeoutTime" BU_SG_REL_ VCM SG_ 592 CpbtyAxle2_TqCpbtyRateIncLeLe 3000;
BA_REL_ "GenSigTimeoutTime" BU_SG_REL_ VCM SG_ 592 CpbtyAxle2_TqCpbtyRateIncLeLe 300;
BA_REL_ "GenSigFirstTimeoutTime" BU_SG_REL_ VCM SG_ 592 CpbtyAxle2_TqCpbtyRateIncLeRi 3000;
BA_REL_ "GenSigTimeoutTime" BU_SG_REL_ VCM SG_ 592 CpbtyAxle2_TqCpbtyRateIncLeRi 300;
BA_REL_ "GenSigFirstTimeoutTime" BU_SG_REL_ VCM SG_ 592 CpbtyAxle2_BrkEgyCpctyLe 3000;
BA_REL_ "GenSigTimeoutTime" BU_SG_REL_ VCM SG_ 592 CpbtyAxle2_BrkEgyCpctyLe 300;
BA_REL_ "GenSigFirstTimeoutTime" BU_SG_REL_ VCM SG_ 592 CpbtyAxle1_TqCpbtyRateDecRi 3000;
BA_REL_ "GenSigTimeoutTime" BU_SG_REL_ VCM SG_ 592 CpbtyAxle1_TqCpbtyRateDecRi 300;
BA_REL_ "GenSigFirstTimeoutTime" BU_SG_REL_ VCM SG_ 592 CpbtyAxle3_TqCpbtyMaxRi 3000;
BA_REL_ "GenSigTimeoutTime" BU_SG_REL_ VCM SG_ 592 CpbtyAxle3_TqCpbtyMaxRi 300;
BA_REL_ "GenSigFirstTimeoutTime" BU_SG_REL_ VCM SG_ 592 CpbtyAxle3_PadWearQltyLe 3000;
BA_REL_ "GenSigTimeoutTime" BU_SG_REL_ VCM SG_ 592 CpbtyAxle3_PadWearQltyLe 300;
BA_REL_ "GenSigFirstTimeoutTime" BU_SG_REL_ VCM SG_ 592 CpbtyAxle3_PadWearLe 3000;
BA_REL_ "GenSigTimeoutTime" BU_SG_REL_ VCM SG_ 592 CpbtyAxle3_PadWearLe 300;
BA_REL_ "GenSigFirstTimeoutTime" BU_SG_REL_ VCM SG_ 592 CpbtyAxle1_TqCpbtyRateQltyLe 3000;
BA_REL_ "GenSigTimeoutTime" BU_SG_REL_ VCM SG_ 592 CpbtyAxle1_TqCpbtyRateQltyLe 300;
BA_REL_ "GenSigFirstTimeoutTime" BU_SG_REL_ VCM SG_ 592 CpbtyAxle1_PadWearLe 3000;
BA_REL_ "GenSigTimeoutTime" BU_SG_REL_ VCM SG_ 592 CpbtyAxle1_PadWearLe 300;
BA_REL_ "GenSigFirstTimeoutTime" BU_SG_REL_ VCM SG_ 592 CpbtyAxle1_TqCpbtyMinRi 3000;
BA_REL_ "GenSigTimeoutTime" BU_SG_REL_ VCM SG_ 592 CpbtyAxle1_TqCpbtyMinRi 300;
BA_REL_ "GenSigFirstTimeoutTime" BU_SG_REL_ VCM SG_ 592 CpbtyAxle1_TqCpbtyQltyRi 3000;
BA_REL_ "GenSigTimeoutTime" BU_SG_REL_ VCM SG_ 592 CpbtyAxle1_TqCpbtyQltyRi 300;
BA_REL_ "GenSigFirstTimeoutTime" BU_SG_REL_ VCM SG_ 592 CpbtyAxle3_BrkEgyCpctyLe 3000;
BA_REL_ "GenSigTimeoutTime" BU_SG_REL_ VCM SG_ 592 CpbtyAxle3_BrkEgyCpctyLe 300;
BA_REL_ "GenSigFirstTimeoutTime" BU_SG_REL_ VCM SG_ 592 CpbtyAxle3_TqCpbtyRateIncLeRi 3000;
BA_REL_ "GenSigTimeoutTime" BU_SG_REL_ VCM SG_ 592 CpbtyAxle3_TqCpbtyRateIncLeRi 300;
BA_REL_ "GenSigFirstTimeoutTime" BU_SG_REL_ VCM SG_ 592 CpbtyAxle1_TqCpbtyMinLe 3000;
BA_REL_ "GenSigTimeoutTime" BU_SG_REL_ VCM SG_ 592 CpbtyAxle1_TqCpbtyMinLe 300;
BA_REL_ "GenSigFirstTimeoutTime" BU_SG_REL_ VCM SG_ 592 CpbtyAxle2_TqCpbtyQltyLe 3000;
BA_REL_ "GenSigTimeoutTime" BU_SG_REL_ VCM SG_ 592 CpbtyAxle2_TqCpbtyQltyLe 300;
BA_REL_ "GenSigFirstTimeoutTime" BU_SG_REL_ VCM SG_ 592 CpbtyAxle2_TqCpbtyRateQltyLe 3000;
BA_REL_ "GenSigTimeoutTime" BU_SG_REL_ VCM SG_ 592 CpbtyAxle2_TqCpbtyRateQltyLe 300;
BA_REL_ "GenSigFirstTimeoutTime" BU_SG_REL_ VCM SG_ 592 CpbtyAxle2_BrkEgyCpctyRi 3000;
BA_REL_ "GenSigTimeoutTime" BU_SG_REL_ VCM SG_ 592 CpbtyAxle2_BrkEgyCpctyRi 300;
BA_REL_ "GenSigFirstTimeoutTime" BU_SG_REL_ VCM SG_ 592 CpbtyAxle1_BrkEgyCpctyQltyLe 3000;
BA_REL_ "GenSigTimeoutTime" BU_SG_REL_ VCM SG_ 592 CpbtyAxle1_BrkEgyCpctyQltyLe 300;
BA_REL_ "GenSigFirstTimeoutTime" BU_SG_REL_ VCM SG_ 592 CpbtyAxle2_PadWearQltyLe 3000;
BA_REL_ "GenSigTimeoutTime" BU_SG_REL_ VCM SG_ 592 CpbtyAxle2_PadWearQltyLe 300;
BA_REL_ "GenSigFirstTimeoutTime" BU_SG_REL_ VCM SG_ 592 CpbtyAxle1_TqCpbtyMaxLe 3000;
BA_REL_ "GenSigTimeoutTime" BU_SG_REL_ VCM SG_ 592 CpbtyAxle1_TqCpbtyMaxLe 300;
BA_REL_ "GenSigFirstTimeoutTime" BU_SG_REL_ VCM SG_ 592 CpbtyAxle3_CRC 3000;
BA_REL_ "GenSigTimeoutTime" BU_SG_REL_ VCM SG_ 592 CpbtyAxle3_CRC 300;
BA_REL_ "GenSigFirstTimeoutTime" BU_SG_REL_ VCM SG_ 592 CpbtyAxle3_SqC 3000;
BA_REL_ "GenSigTimeoutTime" BU_SG_REL_ VCM SG_ 592 CpbtyAxle3_SqC 300;
BA_REL_ "GenSigFirstTimeoutTime" BU_SG_REL_ VCM SG_ 41 PLCMsgStat_MsgStatus_ISig_3 24000;
BA_REL_ "GenSigTimeoutTime" BU_SG_REL_ VCM SG_ 41 PLCMsgStat_MsgStatus_ISig_3 6000;
BA_REL_ "GenSigFirstTimeoutTime" BU_SG_REL_ APM SG_ 296 FrontAxleSpeed_ISig_3 3000;
BA_REL_ "GenSigTimeoutTime" BU_SG_REL_ APM SG_ 296 FrontAxleSpeed_ISig_3 180;
BA_REL_ "GenSigFirstTimeoutTime" BU_SG_REL_ VCM SG_ 832 WhlSpdSenTothCnt456_TimeStamp_IS 3000;
BA_REL_ "GenSigTimeoutTime" BU_SG_REL_ VCM SG_ 832 WhlSpdSenTothCnt456_TimeStamp_IS 300;
BA_REL_ "GenSigFirstTimeoutTime" BU_SG_REL_ VCM SG_ 832 WhlSpdSenTothCnt456_Axle6Right_I 3000;
BA_REL_ "GenSigTimeoutTime" BU_SG_REL_ VCM SG_ 832 WhlSpdSenTothCnt456_Axle6Right_I 300;
BA_REL_ "GenSigFirstTimeoutTime" BU_SG_REL_ VCM SG_ 832 WhlSpdSenTothCnt456_Axle5Left_IS 3000;
BA_REL_ "GenSigTimeoutTime" BU_SG_REL_ VCM SG_ 832 WhlSpdSenTothCnt456_Axle5Left_IS 300;
BA_REL_ "GenSigFirstTimeoutTime" BU_SG_REL_ VCM SG_ 832 WhlSpdSenTothCnt456_Axle4Right_I 3000;
BA_REL_ "GenSigTimeoutTime" BU_SG_REL_ VCM SG_ 832 WhlSpdSenTothCnt456_Axle4Right_I 300;
BA_REL_ "GenSigFirstTimeoutTime" BU_SG_REL_ VCM SG_ 832 WhlSpdSenTothCnt456_Axle5Right_I 3000;
BA_REL_ "GenSigTimeoutTime" BU_SG_REL_ VCM SG_ 832 WhlSpdSenTothCnt456_Axle5Right_I 300;
BA_REL_ "GenSigFirstTimeoutTime" BU_SG_REL_ VCM SG_ 832 WhlSpdSenTothCnt123_Axle2Left_IS 3000;
BA_REL_ "GenSigTimeoutTime" BU_SG_REL_ VCM SG_ 832 WhlSpdSenTothCnt123_Axle2Left_IS 300;
BA_REL_ "GenSigFirstTimeoutTime" BU_SG_REL_ VCM SG_ 832 WhlSpdSenTothCnt123_TimeStamp_IS 3000;
BA_REL_ "GenSigTimeoutTime" BU_SG_REL_ VCM SG_ 832 WhlSpdSenTothCnt123_TimeStamp_IS 300;
BA_REL_ "GenSigFirstTimeoutTime" BU_SG_REL_ VCM SG_ 832 WhlSpdSenTothCnt456_Axle4Left_IS 3000;
BA_REL_ "GenSigTimeoutTime" BU_SG_REL_ VCM SG_ 832 WhlSpdSenTothCnt456_Axle4Left_IS 300;
BA_REL_ "GenSigFirstTimeoutTime" BU_SG_REL_ VCM SG_ 832 WhlSpdSenTothCnt123_Axle3Left_IS 3000;
BA_REL_ "GenSigTimeoutTime" BU_SG_REL_ VCM SG_ 832 WhlSpdSenTothCnt123_Axle3Left_IS 300;
BA_REL_ "GenSigFirstTimeoutTime" BU_SG_REL_ VCM SG_ 832 WhlSpdSenTothCnt123_Axle1Right_I 3000;
BA_REL_ "GenSigTimeoutTime" BU_SG_REL_ VCM SG_ 832 WhlSpdSenTothCnt123_Axle1Right_I 300;
BA_REL_ "GenSigFirstTimeoutTime" BU_SG_REL_ VCM SG_ 832 WhlSpdSenTothCnt123_Axle3Right_I 3000;
BA_REL_ "GenSigTimeoutTime" BU_SG_REL_ VCM SG_ 832 WhlSpdSenTothCnt123_Axle3Right_I 300;
BA_REL_ "GenSigFirstTimeoutTime" BU_SG_REL_ VCM SG_ 832 WhlSpdSenTothCnt456_Axle6Left_IS 3000;
BA_REL_ "GenSigTimeoutTime" BU_SG_REL_ VCM SG_ 832 WhlSpdSenTothCnt456_Axle6Left_IS 300;
BA_REL_ "GenSigFirstTimeoutTime" BU_SG_REL_ VCM SG_ 832 WhlSpdSenTothCnt123_Axle2Right_I 3000;
BA_REL_ "GenSigTimeoutTime" BU_SG_REL_ VCM SG_ 832 WhlSpdSenTothCnt123_Axle2Right_I 300;
BA_REL_ "GenSigFirstTimeoutTime" BU_SG_REL_ VCM SG_ 832 WhlSpdSenTothCnt123_Axle1Left_IS 3000;
BA_REL_ "GenSigTimeoutTime" BU_SG_REL_ VCM SG_ 832 WhlSpdSenTothCnt123_Axle1Left_IS 300;
BA_REL_ "GenSigFirstTimeoutTime" BU_SG_REL_ VCM SG_ 1507 PLCBusStatus_ISig_3 24000;
BA_REL_ "GenSigTimeoutTime" BU_SG_REL_ VCM SG_ 1507 PLCBusStatus_ISig_3 6000;
BA_REL_ "GenSigFirstTimeoutTime" BU_SG_REL_ VCM SG_ 1105 XPRRequest_EBS 3000;
BA_REL_ "GenSigTimeoutTime" BU_SG_REL_ VCM SG_ 1105 XPRRequest_EBS 600;
BA_REL_ "GenSigFirstTimeoutTime" BU_SG_REL_ VCM SG_ 1105 XBRSystemState_ISig_3 3000;
BA_REL_ "GenSigTimeoutTime" BU_SG_REL_ VCM SG_ 1105 XBRSystemState_ISig_3 600;
BA_REL_ "GenSigFirstTimeoutTime" BU_SG_REL_ APM SG_ 1105 XBRSystemState_ISig_3 3000;
BA_REL_ "GenSigTimeoutTime" BU_SG_REL_ APM SG_ 1105 XBRSystemState_ISig_3 600;
BA_REL_ "GenSigFirstTimeoutTime" BU_SG_REL_ APM SG_ 1105 ABSFullyOperational_ISig_3 3000;
BA_REL_ "GenSigTimeoutTime" BU_SG_REL_ APM SG_ 1105 ABSFullyOperational_ISig_3 600;
BA_REL_ "GenSigFirstTimeoutTime" BU_SG_REL_ VCM SG_ 1105 TrailerCommunicationType_ISig_3 3000;
BA_REL_ "GenSigTimeoutTime" BU_SG_REL_ VCM SG_ 1105 TrailerCommunicationType_ISig_3 600;
BA_REL_ "GenSigFirstTimeoutTime" BU_SG_REL_ VCM SG_ 439 ABSAxle5Active 3000;
BA_REL_ "GenSigTimeoutTime" BU_SG_REL_ VCM SG_ 439 ABSAxle5Active 120;
BA_REL_ "GenSigFirstTimeoutTime" BU_SG_REL_ APM SG_ 439 ABSAxle5Active 3000;
BA_REL_ "GenSigTimeoutTime" BU_SG_REL_ APM SG_ 439 ABSAxle5Active 120;
BA_REL_ "GenSigFirstTimeoutTime" BU_SG_REL_ VCM SG_ 439 EACompound_CRC 3000;
BA_REL_ "GenSigTimeoutTime" BU_SG_REL_ VCM SG_ 439 EACompound_CRC 120;
BA_REL_ "GenSigFirstTimeoutTime" BU_SG_REL_ APM SG_ 439 EACompound_CRC 3000;
BA_REL_ "GenSigTimeoutTime" BU_SG_REL_ APM SG_ 439 EACompound_CRC 120;
BA_REL_ "GenSigFirstTimeoutTime" BU_SG_REL_ VCM SG_ 439 RrAxle1RtWhlBrakeApplPrsHiRng 3000;
BA_REL_ "GenSigTimeoutTime" BU_SG_REL_ VCM SG_ 439 RrAxle1RtWhlBrakeApplPrsHiRng 120;
BA_REL_ "GenSigFirstTimeoutTime" BU_SG_REL_ VCM SG_ 439 RrAxle3RtWhlBrakeApplPrsHiRng 3000;
BA_REL_ "GenSigTimeoutTime" BU_SG_REL_ VCM SG_ 439 RrAxle3RtWhlBrakeApplPrsHiRng 120;
BA_REL_ "GenSigFirstTimeoutTime" BU_SG_REL_ VCM SG_ 439 Trailer1TractionHelp_ISig_3 3000;
BA_REL_ "GenSigTimeoutTime" BU_SG_REL_ VCM SG_ 439 Trailer1TractionHelp_ISig_3 120;
BA_REL_ "GenSigFirstTimeoutTime" BU_SG_REL_ VCM SG_ 439 FrAxleRtWhlBrakeApplPrsHiRng 3000;
BA_REL_ "GenSigTimeoutTime" BU_SG_REL_ VCM SG_ 439 FrAxleRtWhlBrakeApplPrsHiRng 120;
BA_REL_ "GenSigFirstTimeoutTime" BU_SG_REL_ APM SG_ 439 EBSBrakeSwitch_ISig_3 3000;
BA_REL_ "GenSigTimeoutTime" BU_SG_REL_ APM SG_ 439 EBSBrakeSwitch_ISig_3 120;
BA_REL_ "GenSigFirstTimeoutTime" BU_SG_REL_ VCM SG_ 439 EBSBrakeSwitch_ISig_3 3000;
BA_REL_ "GenSigTimeoutTime" BU_SG_REL_ VCM SG_ 439 EBSBrakeSwitch_ISig_3 120;
BA_REL_ "GenSigFirstTimeoutTime" BU_SG_REL_ VCM SG_ 439 EACompound_SystemState 3000;
BA_REL_ "GenSigTimeoutTime" BU_SG_REL_ VCM SG_ 439 EACompound_SystemState 120;
BA_REL_ "GenSigFirstTimeoutTime" BU_SG_REL_ APM SG_ 439 EACompound_SystemState 3000;
BA_REL_ "GenSigTimeoutTime" BU_SG_REL_ APM SG_ 439 EACompound_SystemState 120;
BA_REL_ "GenSigFirstTimeoutTime" BU_SG_REL_ VCM SG_ 439 EBSBrakePedalPosition 3000;
BA_REL_ "GenSigTimeoutTime" BU_SG_REL_ VCM SG_ 439 EBSBrakePedalPosition 120;
BA_REL_ "GenSigFirstTimeoutTime" BU_SG_REL_ APM SG_ 439 EBSBrakePedalPosition 3000;
BA_REL_ "GenSigTimeoutTime" BU_SG_REL_ APM SG_ 439 EBSBrakePedalPosition 120;
BA_REL_ "GenSigFirstTimeoutTime" BU_SG_REL_ FAS SG_ 439 AntiLockBrakingActive_ISig_3 3000;
BA_REL_ "GenSigTimeoutTime" BU_SG_REL_ FAS SG_ 439 AntiLockBrakingActive_ISig_3 120;
BA_REL_ "GenSigFirstTimeoutTime" BU_SG_REL_ APM SG_ 439 AntiLockBrakingActive_ISig_3 3000;
BA_REL_ "GenSigTimeoutTime" BU_SG_REL_ APM SG_ 439 AntiLockBrakingActive_ISig_3 120;
BA_REL_ "GenSigFirstTimeoutTime" BU_SG_REL_ VCM SG_ 439 AntiLockBrakingActive_ISig_3 3000;
BA_REL_ "GenSigTimeoutTime" BU_SG_REL_ VCM SG_ 439 AntiLockBrakingActive_ISig_3 120;
BA_REL_ "GenSigFirstTimeoutTime" BU_SG_REL_ VCM SG_ 439 StretchBrake_Stat_ISig_3 3000;
BA_REL_ "GenSigTimeoutTime" BU_SG_REL_ VCM SG_ 439 StretchBrake_Stat_ISig_3 120;
BA_REL_ "GenSigFirstTimeoutTime" BU_SG_REL_ VCM SG_ 439 HillHolderMode_ISig_3 3000;
BA_REL_ "GenSigTimeoutTime" BU_SG_REL_ VCM SG_ 439 HillHolderMode_ISig_3 120;
BA_REL_ "GenSigFirstTimeoutTime" BU_SG_REL_ APM SG_ 439 HillHolderMode_ISig_3 3000;
BA_REL_ "GenSigTimeoutTime" BU_SG_REL_ APM SG_ 439 HillHolderMode_ISig_3 120;
BA_REL_ "GenSigFirstTimeoutTime" BU_SG_REL_ VCM SG_ 439 ABSAxle4Active 3000;
BA_REL_ "GenSigTimeoutTime" BU_SG_REL_ VCM SG_ 439 ABSAxle4Active 120;
BA_REL_ "GenSigFirstTimeoutTime" BU_SG_REL_ APM SG_ 439 ABSAxle4Active 3000;
BA_REL_ "GenSigTimeoutTime" BU_SG_REL_ APM SG_ 439 ABSAxle4Active 120;
BA_REL_ "GenSigFirstTimeoutTime" BU_SG_REL_ VCM SG_ 439 TrailerBrake_Stat_ISig_3 3000;
BA_REL_ "GenSigTimeoutTime" BU_SG_REL_ VCM SG_ 439 TrailerBrake_Stat_ISig_3 120;
BA_REL_ "GenSigFirstTimeoutTime" BU_SG_REL_ VCM SG_ 439 CombinedWheelSpeed_CRC 3000;
BA_REL_ "GenSigTimeoutTime" BU_SG_REL_ VCM SG_ 439 CombinedWheelSpeed_CRC 120;
BA_REL_ "GenSigFirstTimeoutTime" BU_SG_REL_ APM SG_ 439 CombinedWheelSpeed_CRC 3000;
BA_REL_ "GenSigTimeoutTime" BU_SG_REL_ APM SG_ 439 CombinedWheelSpeed_CRC 120;
BA_REL_ "GenSigFirstTimeoutTime" BU_SG_REL_ VCM SG_ 439 ABSAxle2Active 3000;
BA_REL_ "GenSigTimeoutTime" BU_SG_REL_ VCM SG_ 439 ABSAxle2Active 120;
BA_REL_ "GenSigFirstTimeoutTime" BU_SG_REL_ APM SG_ 439 ABSAxle2Active 3000;
BA_REL_ "GenSigTimeoutTime" BU_SG_REL_ APM SG_ 439 ABSAxle2Active 120;
BA_REL_ "GenSigFirstTimeoutTime" BU_SG_REL_ VCM SG_ 439 TrailerEBSAmberWarning_ISig_3 3000;
BA_REL_ "GenSigTimeoutTime" BU_SG_REL_ VCM SG_ 439 TrailerEBSAmberWarning_ISig_3 120;
BA_REL_ "GenSigFirstTimeoutTime" BU_SG_REL_ VCM SG_ 439 CombinedWheelSpeed_SqC 3000;
BA_REL_ "GenSigTimeoutTime" BU_SG_REL_ VCM SG_ 439 CombinedWheelSpeed_SqC 120;
BA_REL_ "GenSigFirstTimeoutTime" BU_SG_REL_ APM SG_ 439 CombinedWheelSpeed_SqC 3000;
BA_REL_ "GenSigTimeoutTime" BU_SG_REL_ APM SG_ 439 CombinedWheelSpeed_SqC 120;
BA_REL_ "GenSigFirstTimeoutTime" BU_SG_REL_ VCM SG_ 439 ABSAxle1Active 3000;
BA_REL_ "GenSigTimeoutTime" BU_SG_REL_ VCM SG_ 439 ABSAxle1Active 120;
BA_REL_ "GenSigFirstTimeoutTime" BU_SG_REL_ APM SG_ 439 ABSAxle1Active 3000;
BA_REL_ "GenSigTimeoutTime" BU_SG_REL_ APM SG_ 439 ABSAxle1Active 120;
BA_REL_ "GenSigFirstTimeoutTime" BU_SG_REL_ VCM SG_ 439 RrAxle2LtWhlBrakeApplPrsHiRng 3000;
BA_REL_ "GenSigTimeoutTime" BU_SG_REL_ VCM SG_ 439 RrAxle2LtWhlBrakeApplPrsHiRng 120;
BA_REL_ "GenSigFirstTimeoutTime" BU_SG_REL_ VCM SG_ 439 ABSAxle3Active 3000;
BA_REL_ "GenSigTimeoutTime" BU_SG_REL_ VCM SG_ 439 ABSAxle3Active 120;
BA_REL_ "GenSigFirstTimeoutTime" BU_SG_REL_ APM SG_ 439 ABSAxle3Active 3000;
BA_REL_ "GenSigTimeoutTime" BU_SG_REL_ APM SG_ 439 ABSAxle3Active 120;
BA_REL_ "GenSigFirstTimeoutTime" BU_SG_REL_ VCM SG_ 439 TCMSupply_SqC 3000;
BA_REL_ "GenSigTimeoutTime" BU_SG_REL_ VCM SG_ 439 TCMSupply_SqC 120;
BA_REL_ "GenSigFirstTimeoutTime" BU_SG_REL_ APM SG_ 439 TCMSupply_SqC 3000;
BA_REL_ "GenSigTimeoutTime" BU_SG_REL_ APM SG_ 439 TCMSupply_SqC 120;
BA_REL_ "GenSigFirstTimeoutTime" BU_SG_REL_ VCM SG_ 439 PusherLiftAxleLoweringInhibit_IS 3000;
BA_REL_ "GenSigTimeoutTime" BU_SG_REL_ VCM SG_ 439 PusherLiftAxleLoweringInhibit_IS 120;
BA_REL_ "GenSigFirstTimeoutTime" BU_SG_REL_ VCM SG_ 439 CombinedWheelSpeed_Quality 3000;
BA_REL_ "GenSigTimeoutTime" BU_SG_REL_ VCM SG_ 439 CombinedWheelSpeed_Quality 120;
BA_REL_ "GenSigFirstTimeoutTime" BU_SG_REL_ APM SG_ 439 CombinedWheelSpeed_Quality 3000;
BA_REL_ "GenSigTimeoutTime" BU_SG_REL_ APM SG_ 439 CombinedWheelSpeed_Quality 120;
BA_REL_ "GenSigFirstTimeoutTime" BU_SG_REL_ VCM SG_ 439 SplitBoxDiffLockActvnFuncReq_ISi 3000;
BA_REL_ "GenSigTimeoutTime" BU_SG_REL_ VCM SG_ 439 SplitBoxDiffLockActvnFuncReq_ISi 120;
BA_REL_ "GenSigFirstTimeoutTime" BU_SG_REL_ VCM SG_ 439 SteerableLiftAxleLoweringInhib 3000;
BA_REL_ "GenSigTimeoutTime" BU_SG_REL_ VCM SG_ 439 SteerableLiftAxleLoweringInhib 120;
BA_REL_ "GenSigFirstTimeoutTime" BU_SG_REL_ VCM SG_ 439 RrAxle3LtWhlBrakeApplPrsHiRng 3000;
BA_REL_ "GenSigTimeoutTime" BU_SG_REL_ VCM SG_ 439 RrAxle3LtWhlBrakeApplPrsHiRng 120;
BA_REL_ "GenSigFirstTimeoutTime" BU_SG_REL_ VCM SG_ 439 EACompound_AppliedRatio 3000;
BA_REL_ "GenSigTimeoutTime" BU_SG_REL_ VCM SG_ 439 EACompound_AppliedRatio 120;
BA_REL_ "GenSigFirstTimeoutTime" BU_SG_REL_ APM SG_ 439 EACompound_AppliedRatio 3000;
BA_REL_ "GenSigTimeoutTime" BU_SG_REL_ APM SG_ 439 EACompound_AppliedRatio 120;
BA_REL_ "GenSigFirstTimeoutTime" BU_SG_REL_ VCM SG_ 439 BrakingSystemPressureLim_rqst_IS 3000;
BA_REL_ "GenSigTimeoutTime" BU_SG_REL_ VCM SG_ 439 BrakingSystemPressureLim_rqst_IS 120;
BA_REL_ "GenSigFirstTimeoutTime" BU_SG_REL_ VCM SG_ 439 RrAxle1LtWhlBrakeApplPrsHiRng 3000;
BA_REL_ "GenSigTimeoutTime" BU_SG_REL_ VCM SG_ 439 RrAxle1LtWhlBrakeApplPrsHiRng 120;
BA_REL_ "GenSigFirstTimeoutTime" BU_SG_REL_ APM SG_ 439 EACompound_SqC 3000;
BA_REL_ "GenSigTimeoutTime" BU_SG_REL_ APM SG_ 439 EACompound_SqC 120;
BA_REL_ "GenSigFirstTimeoutTime" BU_SG_REL_ VCM SG_ 439 EACompound_SqC 3000;
BA_REL_ "GenSigTimeoutTime" BU_SG_REL_ VCM SG_ 439 EACompound_SqC 120;
BA_REL_ "GenSigFirstTimeoutTime" BU_SG_REL_ APM SG_ 439 TCMSupply_CRC 3000;
BA_REL_ "GenSigTimeoutTime" BU_SG_REL_ APM SG_ 439 TCMSupply_CRC 120;
BA_REL_ "GenSigFirstTimeoutTime" BU_SG_REL_ VCM SG_ 439 TCMSupply_CRC 3000;
BA_REL_ "GenSigTimeoutTime" BU_SG_REL_ VCM SG_ 439 TCMSupply_CRC 120;
BA_REL_ "GenSigFirstTimeoutTime" BU_SG_REL_ VCM SG_ 439 TrailerControlPressure 3000;
BA_REL_ "GenSigTimeoutTime" BU_SG_REL_ VCM SG_ 439 TrailerControlPressure 120;
BA_REL_ "GenSigFirstTimeoutTime" BU_SG_REL_ VCM SG_ 439 RrAxle2RtWhlBrakeApplPrsHiRng 3000;
BA_REL_ "GenSigTimeoutTime" BU_SG_REL_ VCM SG_ 439 RrAxle2RtWhlBrakeApplPrsHiRng 120;
BA_REL_ "GenSigFirstTimeoutTime" BU_SG_REL_ VCM SG_ 439 ScndRrAxlDiffLckActvnFuncReq_ISi 3000;
BA_REL_ "GenSigTimeoutTime" BU_SG_REL_ VCM SG_ 439 ScndRrAxlDiffLckActvnFuncReq_ISi 120;
BA_REL_ "GenSigFirstTimeoutTime" BU_SG_REL_ VCM SG_ 439 TCMSupply_TrailerPressure 3000;
BA_REL_ "GenSigTimeoutTime" BU_SG_REL_ VCM SG_ 439 TCMSupply_TrailerPressure 120;
BA_REL_ "GenSigFirstTimeoutTime" BU_SG_REL_ APM SG_ 439 TCMSupply_TrailerPressure 3000;
BA_REL_ "GenSigTimeoutTime" BU_SG_REL_ APM SG_ 439 TCMSupply_TrailerPressure 120;
BA_REL_ "GenSigFirstTimeoutTime" BU_SG_REL_ APM SG_ 439 CombinedWheelSpeed_Speed 3000;
BA_REL_ "GenSigTimeoutTime" BU_SG_REL_ APM SG_ 439 CombinedWheelSpeed_Speed 120;
BA_REL_ "GenSigFirstTimeoutTime" BU_SG_REL_ VCM SG_ 439 CombinedWheelSpeed_Speed 3000;
BA_REL_ "GenSigTimeoutTime" BU_SG_REL_ VCM SG_ 439 CombinedWheelSpeed_Speed 120;
BA_REL_ "GenSigFirstTimeoutTime" BU_SG_REL_ VCM SG_ 439 HSAState 3000;
BA_REL_ "GenSigTimeoutTime" BU_SG_REL_ VCM SG_ 439 HSAState 120;
BA_REL_ "GenSigFirstTimeoutTime" BU_SG_REL_ VCM SG_ 439 FrAxleLtWhlBrakeApplPrsHiRng 3000;
BA_REL_ "GenSigTimeoutTime" BU_SG_REL_ VCM SG_ 439 FrAxleLtWhlBrakeApplPrsHiRng 120;
BA_REL_ "GenSigFirstTimeoutTime" BU_SG_REL_ FAS SG_ 315 FrontAxleLeftWheelSpeed_ISig_3 3000;
BA_REL_ "GenSigTimeoutTime" BU_SG_REL_ FAS SG_ 315 FrontAxleLeftWheelSpeed_ISig_3 100;
BA_REL_ "GenSigFirstTimeoutTime" BU_SG_REL_ VCM SG_ 315 SteeringWheel_AngleCRC 3000;
BA_REL_ "GenSigTimeoutTime" BU_SG_REL_ VCM SG_ 315 SteeringWheel_AngleCRC 100;
BA_REL_ "GenSigFirstTimeoutTime" BU_SG_REL_ VCM SG_ 315 SteeringWheelTurnCounter 3000;
BA_REL_ "GenSigTimeoutTime" BU_SG_REL_ VCM SG_ 315 SteeringWheelTurnCounter 100;
BA_REL_ "GenSigFirstTimeoutTime" BU_SG_REL_ VCM SG_ 315 SteeringWheel_AngleCounter 3000;
BA_REL_ "GenSigTimeoutTime" BU_SG_REL_ VCM SG_ 315 SteeringWheel_AngleCounter 100;
BA_REL_ "GenSigFirstTimeoutTime" BU_SG_REL_ FAS SG_ 315 FrontAxleRightWheelSpeed_ISig_3 3000;
BA_REL_ "GenSigTimeoutTime" BU_SG_REL_ FAS SG_ 315 FrontAxleRightWheelSpeed_ISig_3 100;
BA_REL_ "GenSigFirstTimeoutTime" BU_SG_REL_ VCM SG_ 315 LateralAcceleration_ISig_3 3000;
BA_REL_ "GenSigTimeoutTime" BU_SG_REL_ VCM SG_ 315 LateralAcceleration_ISig_3 100;
BA_REL_ "GenSigFirstTimeoutTime" BU_SG_REL_ VCM SG_ 315 SteeringWheelAngleSensorType 3000;
BA_REL_ "GenSigTimeoutTime" BU_SG_REL_ VCM SG_ 315 SteeringWheelAngleSensorType 100;
BA_REL_ "GenSigFirstTimeoutTime" BU_SG_REL_ VCM SG_ 315 BrakeLightActivationRequest_ISig 3000;
BA_REL_ "GenSigTimeoutTime" BU_SG_REL_ VCM SG_ 315 BrakeLightActivationRequest_ISig 100;
BA_REL_ "GenSigFirstTimeoutTime" BU_SG_REL_ VCM SG_ 315 SteeringWheel_AngleValue 3000;
BA_REL_ "GenSigTimeoutTime" BU_SG_REL_ VCM SG_ 315 SteeringWheel_AngleValue 100;
BA_REL_ "GenSigFirstTimeoutTime" BU_SG_REL_ VCM SG_ 315 LongitudinalAcceleration_ISig_3 3000;
BA_REL_ "GenSigTimeoutTime" BU_SG_REL_ VCM SG_ 315 LongitudinalAcceleration_ISig_3 100;
BA_REL_ "GenSigFirstTimeoutTime" BU_SG_REL_ VCM SG_ 315 SteeringWheelAngle_ISig_3 3000;
BA_REL_ "GenSigTimeoutTime" BU_SG_REL_ VCM SG_ 315 SteeringWheelAngle_ISig_3 100;
BA_REL_ "GenSigFirstTimeoutTime" BU_SG_REL_ FAS SG_ 315 SteeringWheelAngle_ISig_3 3000;
BA_REL_ "GenSigTimeoutTime" BU_SG_REL_ FAS SG_ 315 SteeringWheelAngle_ISig_3 100;
BA_REL_ "GenSigFirstTimeoutTime" BU_SG_REL_ VCM SG_ 315 SteeringWheelAngleComp 3000;
BA_REL_ "GenSigTimeoutTime" BU_SG_REL_ VCM SG_ 315 SteeringWheelAngleComp 100;
BA_REL_ "GenSigFirstTimeoutTime" BU_SG_REL_ FAS SG_ 315 SteeringWheelAngleComp 3000;
BA_REL_ "GenSigTimeoutTime" BU_SG_REL_ FAS SG_ 315 SteeringWheelAngleComp 100;
BA_REL_ "GenSigFirstTimeoutTime" BU_SG_REL_ FAS SG_ 315 YawRate_ISig_3 3000;
BA_REL_ "GenSigTimeoutTime" BU_SG_REL_ FAS SG_ 315 YawRate_ISig_3 100;
BA_REL_ "GenSigFirstTimeoutTime" BU_SG_REL_ VCM SG_ 315 YawRate_ISig_3 3000;
BA_REL_ "GenSigTimeoutTime" BU_SG_REL_ VCM SG_ 315 YawRate_ISig_3 100;
BA_REL_ "GenSigFirstTimeoutTime" BU_SG_REL_ VCM SG_ 315 VDCBrakeLightRequest_ISig_3 3000;
BA_REL_ "GenSigTimeoutTime" BU_SG_REL_ VCM SG_ 315 VDCBrakeLightRequest_ISig_3 100;
BA_REL_ "GenSigFirstTimeoutTime" BU_SG_REL_ VCM SG_ 1491 DiagFaultStat_FAS_FailTA 24000;
BA_REL_ "GenSigTimeoutTime" BU_SG_REL_ VCM SG_ 1491 DiagFaultStat_FAS_FailTA 6000;
BA_REL_ "GenSigFirstTimeoutTime" BU_SG_REL_ VCM SG_ 1491 DiagFaultStat_FAS_EcuAdr 24000;
BA_REL_ "GenSigTimeoutTime" BU_SG_REL_ VCM SG_ 1491 DiagFaultStat_FAS_EcuAdr 6000;
BA_REL_ "GenSigFirstTimeoutTime" BU_SG_REL_ VCM SG_ 1491 DiagFaultStat_FAS_DtcIdA 24000;
BA_REL_ "GenSigTimeoutTime" BU_SG_REL_ VCM SG_ 1491 DiagFaultStat_FAS_DtcIdA 6000;
BA_REL_ "GenSigFirstTimeoutTime" BU_SG_REL_ VCM SG_ 1491 DiagFaultStat_FAS_DtcIdB 24000;
BA_REL_ "GenSigTimeoutTime" BU_SG_REL_ VCM SG_ 1491 DiagFaultStat_FAS_DtcIdB 6000;
BA_REL_ "GenSigFirstTimeoutTime" BU_SG_REL_ VCM SG_ 1491 DiagFaultStat_FAS_FailTB 24000;
BA_REL_ "GenSigTimeoutTime" BU_SG_REL_ VCM SG_ 1491 DiagFaultStat_FAS_FailTB 6000;
BA_REL_ "GenSigFirstTimeoutTime" BU_SG_REL_ VCM SG_ 1152 DiagFaultStat_APM_EcuAdr 24000;
BA_REL_ "GenSigTimeoutTime" BU_SG_REL_ VCM SG_ 1152 DiagFaultStat_APM_EcuAdr 6000;
BA_REL_ "GenSigFirstTimeoutTime" BU_SG_REL_ VCM SG_ 1152 DiagFaultStat_APM_sg_UB 24000;
BA_REL_ "GenSigTimeoutTime" BU_SG_REL_ VCM SG_ 1152 DiagFaultStat_APM_sg_UB 6000;
BA_REL_ "GenSigFirstTimeoutTime" BU_SG_REL_ VCM SG_ 1152 DiagFaultStat_APM_FailTB 24000;
BA_REL_ "GenSigTimeoutTime" BU_SG_REL_ VCM SG_ 1152 DiagFaultStat_APM_FailTB 6000;
BA_REL_ "GenSigFirstTimeoutTime" BU_SG_REL_ VCM SG_ 1152 DiagFaultStat_APM_DtcIdB 24000;
BA_REL_ "GenSigTimeoutTime" BU_SG_REL_ VCM SG_ 1152 DiagFaultStat_APM_DtcIdB 6000;
BA_REL_ "GenSigFirstTimeoutTime" BU_SG_REL_ VCM SG_ 1152 DiagFaultStat_APM_FailTA 24000;
BA_REL_ "GenSigTimeoutTime" BU_SG_REL_ VCM SG_ 1152 DiagFaultStat_APM_FailTA 6000;
BA_REL_ "GenSigFirstTimeoutTime" BU_SG_REL_ VCM SG_ 1152 DiagFaultStat_APM_DtcIdA 24000;
BA_REL_ "GenSigTimeoutTime" BU_SG_REL_ VCM SG_ 1152 DiagFaultStat_APM_DtcIdA 6000;
BA_REL_ "GenSigFirstTimeoutTime" BU_SG_REL_ VCM SG_ 1536 AirCartridgeWearingPercentage 48000;
BA_REL_ "GenSigTimeoutTime" BU_SG_REL_ VCM SG_ 1536 AirCartridgeWearingPercentage 12000;
BA_REL_ "GenSigFirstTimeoutTime" BU_SG_REL_ VCM SG_ 1536 TotAirVolCurrentAirDryerFilter 48000;
BA_REL_ "GenSigTimeoutTime" BU_SG_REL_ VCM SG_ 1536 TotAirVolCurrentAirDryerFilter 12000;
BA_REL_ "GenSigFirstTimeoutTime" BU_SG_REL_ VCM SG_ 896 PBSensorRawADCValue 6000;
BA_REL_ "GenSigTimeoutTime" BU_SG_REL_ VCM SG_ 896 PBSensorRawADCValue 1500;
BA_REL_ "GenSigFirstTimeoutTime" BU_SG_REL_ EBS SG_ 896 ServiceBrakeAirPrsCircuit2_ISig_ 6000;
BA_REL_ "GenSigTimeoutTime" BU_SG_REL_ EBS SG_ 896 ServiceBrakeAirPrsCircuit2_ISig_ 1500;
BA_REL_ "GenSigFirstTimeoutTime" BU_SG_REL_ VCM SG_ 896 ServiceBrakeAirPrsCircuit2_ISig_ 6000;
BA_REL_ "GenSigTimeoutTime" BU_SG_REL_ VCM SG_ 896 ServiceBrakeAirPrsCircuit2_ISig_ 1500;
BA_REL_ "GenSigFirstTimeoutTime" BU_SG_REL_ VCM SG_ 896 ParkingAndTrailerAirPressure 6000;
BA_REL_ "GenSigTimeoutTime" BU_SG_REL_ VCM SG_ 896 ParkingAndTrailerAirPressure 1500;
BA_REL_ "GenSigFirstTimeoutTime" BU_SG_REL_ EBS SG_ 896 ParkingAndTrailerAirPressure 6000;
BA_REL_ "GenSigTimeoutTime" BU_SG_REL_ EBS SG_ 896 ParkingAndTrailerAirPressure 1500;
BA_REL_ "GenSigFirstTimeoutTime" BU_SG_REL_ VCM SG_ 896 ServiceBrakeAirPrsCircuit1_ISig_ 6000;
BA_REL_ "GenSigTimeoutTime" BU_SG_REL_ VCM SG_ 896 ServiceBrakeAirPrsCircuit1_ISig_ 1500;
BA_REL_ "GenSigFirstTimeoutTime" BU_SG_REL_ EBS SG_ 896 ServiceBrakeAirPrsCircuit1_ISig_ 6000;
BA_REL_ "GenSigTimeoutTime" BU_SG_REL_ EBS SG_ 896 ServiceBrakeAirPrsCircuit1_ISig_ 1500;
BA_REL_ "GenSigFirstTimeoutTime" BU_SG_REL_ VCM SG_ 640 APMSafetyWarning_YellowRqst_ISig 3000;
BA_REL_ "GenSigTimeoutTime" BU_SG_REL_ VCM SG_ 640 APMSafetyWarning_YellowRqst_ISig 600;
BA_REL_ "GenSigFirstTimeoutTime" BU_SG_REL_ VCM SG_ 640 TrailerStatus_IntegrityLvl_ISig_ 3000;
BA_REL_ "GenSigTimeoutTime" BU_SG_REL_ VCM SG_ 640 TrailerStatus_IntegrityLvl_ISig_ 600;
BA_REL_ "GenSigFirstTimeoutTime" BU_SG_REL_ EBS SG_ 640 TrailerStatus_IntegrityLvl_ISig_ 3000;
BA_REL_ "GenSigTimeoutTime" BU_SG_REL_ EBS SG_ 640 TrailerStatus_IntegrityLvl_ISig_ 600;
BA_REL_ "GenSigFirstTimeoutTime" BU_SG_REL_ VCM SG_ 640 PBAirLvl_SqC 3000;
BA_REL_ "GenSigTimeoutTime" BU_SG_REL_ VCM SG_ 640 PBAirLvl_SqC 600;
BA_REL_ "GenSigFirstTimeoutTime" BU_SG_REL_ EBS SG_ 640 PBAirLvl_SqC 3000;
BA_REL_ "GenSigTimeoutTime" BU_SG_REL_ EBS SG_ 640 PBAirLvl_SqC 600;
BA_REL_ "GenSigFirstTimeoutTime" BU_SG_REL_ VCM SG_ 640 RedGladHand_SqC_ISig_3 3000;
BA_REL_ "GenSigTimeoutTime" BU_SG_REL_ VCM SG_ 640 RedGladHand_SqC_ISig_3 600;
BA_REL_ "GenSigFirstTimeoutTime" BU_SG_REL_ EBS SG_ 640 LowAirPressureAlert_ISig_3 3000;
BA_REL_ "GenSigTimeoutTime" BU_SG_REL_ EBS SG_ 640 LowAirPressureAlert_ISig_3 600;
BA_REL_ "GenSigFirstTimeoutTime" BU_SG_REL_ VCM SG_ 640 LowAirPressureAlert_ISig_3 3000;
BA_REL_ "GenSigTimeoutTime" BU_SG_REL_ VCM SG_ 640 LowAirPressureAlert_ISig_3 600;
BA_REL_ "GenSigFirstTimeoutTime" BU_SG_REL_ VCM SG_ 640 TrailerStatus_CRC_ISig_3 3000;
BA_REL_ "GenSigTimeoutTime" BU_SG_REL_ VCM SG_ 640 TrailerStatus_CRC_ISig_3 600;
BA_REL_ "GenSigFirstTimeoutTime" BU_SG_REL_ EBS SG_ 640 TrailerStatus_CRC_ISig_3 3000;
BA_REL_ "GenSigTimeoutTime" BU_SG_REL_ EBS SG_ 640 TrailerStatus_CRC_ISig_3 600;
BA_REL_ "GenSigFirstTimeoutTime" BU_SG_REL_ VCM SG_ 640 PBPositionLeverCopy 3000;
BA_REL_ "GenSigTimeoutTime" BU_SG_REL_ VCM SG_ 640 PBPositionLeverCopy 600;
BA_REL_ "GenSigFirstTimeoutTime" BU_SG_REL_ VCM SG_ 640 DynamicPB_ActiveStatus 3000;
BA_REL_ "GenSigTimeoutTime" BU_SG_REL_ VCM SG_ 640 DynamicPB_ActiveStatus 600;
BA_REL_ "GenSigFirstTimeoutTime" BU_SG_REL_ EBS SG_ 640 PBStatus_CRC_ISig_3 3000;
BA_REL_ "GenSigTimeoutTime" BU_SG_REL_ EBS SG_ 640 PBStatus_CRC_ISig_3 600;
BA_REL_ "GenSigFirstTimeoutTime" BU_SG_REL_ VCM SG_ 640 PBStatus_CRC_ISig_3 3000;
BA_REL_ "GenSigTimeoutTime" BU_SG_REL_ VCM SG_ 640 PBStatus_CRC_ISig_3 600;
BA_REL_ "GenSigFirstTimeoutTime" BU_SG_REL_ VCM SG_ 640 PBAirLvl_AntiCompoundRatio 3000;
BA_REL_ "GenSigTimeoutTime" BU_SG_REL_ VCM SG_ 640 PBAirLvl_AntiCompoundRatio 600;
BA_REL_ "GenSigFirstTimeoutTime" BU_SG_REL_ EBS SG_ 640 PBAirLvl_AntiCompoundRatio 3000;
BA_REL_ "GenSigTimeoutTime" BU_SG_REL_ EBS SG_ 640 PBAirLvl_AntiCompoundRatio 600;
BA_REL_ "GenSigFirstTimeoutTime" BU_SG_REL_ VCM SG_ 640 PB2HCUAreaCopy 3000;
BA_REL_ "GenSigTimeoutTime" BU_SG_REL_ VCM SG_ 640 PB2HCUAreaCopy 600;
BA_REL_ "GenSigFirstTimeoutTime" BU_SG_REL_ VCM SG_ 640 PBStatus_SqC_ISig_3 3000;
BA_REL_ "GenSigTimeoutTime" BU_SG_REL_ VCM SG_ 640 PBStatus_SqC_ISig_3 600;
BA_REL_ "GenSigFirstTimeoutTime" BU_SG_REL_ EBS SG_ 640 PBStatus_SqC_ISig_3 3000;
BA_REL_ "GenSigTimeoutTime" BU_SG_REL_ EBS SG_ 640 PBStatus_SqC_ISig_3 600;
BA_REL_ "GenSigFirstTimeoutTime" BU_SG_REL_ EBS SG_ 640 TrailerStatus_Actuation_ISig_3 3000;
BA_REL_ "GenSigTimeoutTime" BU_SG_REL_ EBS SG_ 640 TrailerStatus_Actuation_ISig_3 600;
BA_REL_ "GenSigFirstTimeoutTime" BU_SG_REL_ VCM SG_ 640 TrailerStatus_Actuation_ISig_3 3000;
BA_REL_ "GenSigTimeoutTime" BU_SG_REL_ VCM SG_ 640 TrailerStatus_Actuation_ISig_3 600;
BA_REL_ "GenSigFirstTimeoutTime" BU_SG_REL_ VCM SG_ 640 RedGladHand_ConnectStatus_ISig_3 3000;
BA_REL_ "GenSigTimeoutTime" BU_SG_REL_ VCM SG_ 640 RedGladHand_ConnectStatus_ISig_3 600;
BA_REL_ "GenSigFirstTimeoutTime" BU_SG_REL_ VCM SG_ 640 PBHCUAreaCopy 3000;
BA_REL_ "GenSigTimeoutTime" BU_SG_REL_ VCM SG_ 640 PBHCUAreaCopy 600;
BA_REL_ "GenSigFirstTimeoutTime" BU_SG_REL_ VCM SG_ 640 PBStatus_IntegrityLvl_ISig_3 3000;
BA_REL_ "GenSigTimeoutTime" BU_SG_REL_ VCM SG_ 640 PBStatus_IntegrityLvl_ISig_3 600;
BA_REL_ "GenSigFirstTimeoutTime" BU_SG_REL_ EBS SG_ 640 PBStatus_IntegrityLvl_ISig_3 3000;
BA_REL_ "GenSigTimeoutTime" BU_SG_REL_ EBS SG_ 640 PBStatus_IntegrityLvl_ISig_3 600;
BA_REL_ "GenSigFirstTimeoutTime" BU_SG_REL_ VCM SG_ 640 TrPositionLeverCopy 3000;
BA_REL_ "GenSigTimeoutTime" BU_SG_REL_ VCM SG_ 640 TrPositionLeverCopy 600;
BA_REL_ "GenSigFirstTimeoutTime" BU_SG_REL_ VCM SG_ 640 AutoPBRelease_stat_ISig_3 3000;
BA_REL_ "GenSigTimeoutTime" BU_SG_REL_ VCM SG_ 640 AutoPBRelease_stat_ISig_3 600;
BA_REL_ "GenSigFirstTimeoutTime" BU_SG_REL_ VCM SG_ 640 APMSafetyWarning_CRC_ISig_3 3000;
BA_REL_ "GenSigTimeoutTime" BU_SG_REL_ VCM SG_ 640 APMSafetyWarning_CRC_ISig_3 600;
BA_REL_ "GenSigFirstTimeoutTime" BU_SG_REL_ VCM SG_ 640 TrHCUAreaCopy 3000;
BA_REL_ "GenSigTimeoutTime" BU_SG_REL_ VCM SG_ 640 TrHCUAreaCopy 600;
BA_REL_ "GenSigFirstTimeoutTime" BU_SG_REL_ VCM SG_ 640 DynamicPB_SqC 3000;
BA_REL_ "GenSigTimeoutTime" BU_SG_REL_ VCM SG_ 640 DynamicPB_SqC 600;
BA_REL_ "GenSigFirstTimeoutTime" BU_SG_REL_ VCM SG_ 640 RedGladHand_CRC_ISig_3 3000;
BA_REL_ "GenSigTimeoutTime" BU_SG_REL_ VCM SG_ 640 RedGladHand_CRC_ISig_3 600;
BA_REL_ "GenSigFirstTimeoutTime" BU_SG_REL_ VCM SG_ 640 TrailerSupplyInflationMode 3000;
BA_REL_ "GenSigTimeoutTime" BU_SG_REL_ VCM SG_ 640 TrailerSupplyInflationMode 600;
BA_REL_ "GenSigFirstTimeoutTime" BU_SG_REL_ VCM SG_ 640 DynamicPB_CRC 3000;
BA_REL_ "GenSigTimeoutTime" BU_SG_REL_ VCM SG_ 640 DynamicPB_CRC 600;
BA_REL_ "GenSigFirstTimeoutTime" BU_SG_REL_ VCM SG_ 640 TLInflationAcceptance_stat_ISig_ 3000;
BA_REL_ "GenSigTimeoutTime" BU_SG_REL_ VCM SG_ 640 TLInflationAcceptance_stat_ISig_ 600;
BA_REL_ "GenSigFirstTimeoutTime" BU_SG_REL_ VCM SG_ 640 TrailerInflationPossible_stat_IS 3000;
BA_REL_ "GenSigTimeoutTime" BU_SG_REL_ VCM SG_ 640 TrailerInflationPossible_stat_IS 600;
BA_REL_ "GenSigFirstTimeoutTime" BU_SG_REL_ VCM SG_ 640 SecondRVAirPressure_Out 3000;
BA_REL_ "GenSigTimeoutTime" BU_SG_REL_ VCM SG_ 640 SecondRVAirPressure_Out 600;
BA_REL_ "GenSigFirstTimeoutTime" BU_SG_REL_ VCM SG_ 640 APMSafetyWarning_RedRqst_ISig_3 3000;
BA_REL_ "GenSigTimeoutTime" BU_SG_REL_ VCM SG_ 640 APMSafetyWarning_RedRqst_ISig_3 600;
BA_REL_ "GenSigFirstTimeoutTime" BU_SG_REL_ EBS SG_ 640 PBAirLvl_CRC 3000;
BA_REL_ "GenSigTimeoutTime" BU_SG_REL_ EBS SG_ 640 PBAirLvl_CRC 600;
BA_REL_ "GenSigFirstTimeoutTime" BU_SG_REL_ VCM SG_ 640 PBAirLvl_CRC 3000;
BA_REL_ "GenSigTimeoutTime" BU_SG_REL_ VCM SG_ 640 PBAirLvl_CRC 600;
BA_REL_ "GenSigFirstTimeoutTime" BU_SG_REL_ VCM SG_ 640 RedGladHand_ConfidenceLvl_ISig_3 3000;
BA_REL_ "GenSigTimeoutTime" BU_SG_REL_ VCM SG_ 640 RedGladHand_ConfidenceLvl_ISig_3 600;
BA_REL_ "GenSigFirstTimeoutTime" BU_SG_REL_ VCM SG_ 640 TrailerSupplyDeflationMode 3000;
BA_REL_ "GenSigTimeoutTime" BU_SG_REL_ VCM SG_ 640 TrailerSupplyDeflationMode 600;
BA_REL_ "GenSigFirstTimeoutTime" BU_SG_REL_ VCM SG_ 640 APMSafetyWarning_SqC_ISig_3 3000;
BA_REL_ "GenSigTimeoutTime" BU_SG_REL_ VCM SG_ 640 APMSafetyWarning_SqC_ISig_3 600;
BA_REL_ "GenSigFirstTimeoutTime" BU_SG_REL_ VCM SG_ 640 AirProdPressureRangeModeStatus 3000;
BA_REL_ "GenSigTimeoutTime" BU_SG_REL_ VCM SG_ 640 AirProdPressureRangeModeStatus 600;
BA_REL_ "GenSigFirstTimeoutTime" BU_SG_REL_ VCM SG_ 640 PB2PositionLeverCopy 3000;
BA_REL_ "GenSigTimeoutTime" BU_SG_REL_ VCM SG_ 640 PB2PositionLeverCopy 600;
BA_REL_ "GenSigFirstTimeoutTime" BU_SG_REL_ EBS SG_ 640 PBAirLvl_PressureInChamber 3000;
BA_REL_ "GenSigTimeoutTime" BU_SG_REL_ EBS SG_ 640 PBAirLvl_PressureInChamber 600;
BA_REL_ "GenSigFirstTimeoutTime" BU_SG_REL_ VCM SG_ 640 PBAirLvl_PressureInChamber 3000;
BA_REL_ "GenSigTimeoutTime" BU_SG_REL_ VCM SG_ 640 PBAirLvl_PressureInChamber 600;
BA_REL_ "GenSigFirstTimeoutTime" BU_SG_REL_ VCM SG_ 640 PBStatus_Actuation_ISig_3 3000;
BA_REL_ "GenSigTimeoutTime" BU_SG_REL_ VCM SG_ 640 PBStatus_Actuation_ISig_3 600;
BA_REL_ "GenSigFirstTimeoutTime" BU_SG_REL_ EBS SG_ 640 PBStatus_Actuation_ISig_3 3000;
BA_REL_ "GenSigTimeoutTime" BU_SG_REL_ EBS SG_ 640 PBStatus_Actuation_ISig_3 600;
BA_REL_ "GenSigFirstTimeoutTime" BU_SG_REL_ VCM SG_ 640 TrailerStatus_SqC_ISig_3 3000;
BA_REL_ "GenSigTimeoutTime" BU_SG_REL_ VCM SG_ 640 TrailerStatus_SqC_ISig_3 600;
BA_REL_ "GenSigFirstTimeoutTime" BU_SG_REL_ EBS SG_ 640 TrailerStatus_SqC_ISig_3 3000;
BA_REL_ "GenSigTimeoutTime" BU_SG_REL_ EBS SG_ 640 TrailerStatus_SqC_ISig_3 600;
BA_REL_ "GenSigFirstTimeoutTime" BU_SG_REL_ VCM SG_ 386 RGHDetect_CRC 3000;
BA_REL_ "GenSigTimeoutTime" BU_SG_REL_ VCM SG_ 386 RGHDetect_CRC 300;
BA_REL_ "GenSigFirstTimeoutTime" BU_SG_REL_ VCM SG_ 386 ParkBrakeChamberAirPressure 3000;
BA_REL_ "GenSigTimeoutTime" BU_SG_REL_ VCM SG_ 386 ParkBrakeChamberAirPressure 300;
BA_REL_ "GenSigFirstTimeoutTime" BU_SG_REL_ EBS SG_ 386 ParkBrakeChamberAirPressure 3000;
BA_REL_ "GenSigTimeoutTime" BU_SG_REL_ EBS SG_ 386 ParkBrakeChamberAirPressure 300;
BA_REL_ "GenSigFirstTimeoutTime" BU_SG_REL_ VCM SG_ 386 XPRGSystemState_AppliedPriority 3000;
BA_REL_ "GenSigTimeoutTime" BU_SG_REL_ VCM SG_ 386 XPRGSystemState_AppliedPriority 300;
BA_REL_ "GenSigFirstTimeoutTime" BU_SG_REL_ VCM SG_ 386 UnLoaderValveStatus 3000;
BA_REL_ "GenSigTimeoutTime" BU_SG_REL_ VCM SG_ 386 UnLoaderValveStatus 300;
BA_REL_ "GenSigFirstTimeoutTime" BU_SG_REL_ VCM SG_ 386 XPRGSystemCap_SqC_ISig_3 3000;
BA_REL_ "GenSigTimeoutTime" BU_SG_REL_ VCM SG_ 386 XPRGSystemCap_SqC_ISig_3 300;
BA_REL_ "GenSigFirstTimeoutTime" BU_SG_REL_ VCM SG_ 386 PBStatusDisplay_cmd_ISig_3 3000;
BA_REL_ "GenSigTimeoutTime" BU_SG_REL_ VCM SG_ 386 PBStatusDisplay_cmd_ISig_3 300;
BA_REL_ "GenSigFirstTimeoutTime" BU_SG_REL_ EBS SG_ 386 ParkBrakeApplicationMode2_ISig_3 3000;
BA_REL_ "GenSigTimeoutTime" BU_SG_REL_ EBS SG_ 386 ParkBrakeApplicationMode2_ISig_3 300;
BA_REL_ "GenSigFirstTimeoutTime" BU_SG_REL_ VCM SG_ 386 ParkBrakeApplicationMode2_ISig_3 3000;
BA_REL_ "GenSigTimeoutTime" BU_SG_REL_ VCM SG_ 386 ParkBrakeApplicationMode2_ISig_3 300;
BA_REL_ "GenSigFirstTimeoutTime" BU_SG_REL_ VCM SG_ 386 XPRGSystemState_CRC 3000;
BA_REL_ "GenSigTimeoutTime" BU_SG_REL_ VCM SG_ 386 XPRGSystemState_CRC 300;
BA_REL_ "GenSigFirstTimeoutTime" BU_SG_REL_ VCM SG_ 386 XPRGSystemCap_AllowedGradCtrlTl_ 3000;
BA_REL_ "GenSigTimeoutTime" BU_SG_REL_ VCM SG_ 386 XPRGSystemCap_AllowedGradCtrlTl_ 300;
BA_REL_ "GenSigFirstTimeoutTime" BU_SG_REL_ VCM SG_ 386 XPRGSystemCap_AllowedGradCtrlTc_ 3000;
BA_REL_ "GenSigTimeoutTime" BU_SG_REL_ VCM SG_ 386 XPRGSystemCap_AllowedGradCtrlTc_ 300;
BA_REL_ "GenSigFirstTimeoutTime" BU_SG_REL_ VCM SG_ 386 XPRGSystemCap_AllowedRelInhibit_ 3000;
BA_REL_ "GenSigTimeoutTime" BU_SG_REL_ VCM SG_ 386 XPRGSystemCap_AllowedRelInhibit_ 300;
BA_REL_ "GenSigFirstTimeoutTime" BU_SG_REL_ VCM SG_ 386 ParkBrakeReleasePossible_stat_IS 3000;
BA_REL_ "GenSigTimeoutTime" BU_SG_REL_ VCM SG_ 386 ParkBrakeReleasePossible_stat_IS 300;
BA_REL_ "GenSigFirstTimeoutTime" BU_SG_REL_ VCM SG_ 386 PBReleaseAcceptance_stat_ISig_3 3000;
BA_REL_ "GenSigTimeoutTime" BU_SG_REL_ VCM SG_ 386 PBReleaseAcceptance_stat_ISig_3 300;
BA_REL_ "GenSigFirstTimeoutTime" BU_SG_REL_ VCM SG_ 386 AirCompressorStatus_ISig_3 3000;
BA_REL_ "GenSigTimeoutTime" BU_SG_REL_ VCM SG_ 386 AirCompressorStatus_ISig_3 300;
BA_REL_ "GenSigFirstTimeoutTime" BU_SG_REL_ VCM SG_ 386 RGHDetect_SqC 3000;
BA_REL_ "GenSigTimeoutTime" BU_SG_REL_ VCM SG_ 386 RGHDetect_SqC 300;
BA_REL_ "GenSigFirstTimeoutTime" BU_SG_REL_ VCM SG_ 386 TrailerTest_stat_ISig_3 3000;
BA_REL_ "GenSigTimeoutTime" BU_SG_REL_ VCM SG_ 386 TrailerTest_stat_ISig_3 300;
BA_REL_ "GenSigFirstTimeoutTime" BU_SG_REL_ VCM SG_ 386 XPRGSystemState_SqC 3000;
BA_REL_ "GenSigTimeoutTime" BU_SG_REL_ VCM SG_ 386 XPRGSystemState_SqC 300;
BA_REL_ "GenSigFirstTimeoutTime" BU_SG_REL_ VCM SG_ 386 PoorAirPressureInfo_ISig_3 3000;
BA_REL_ "GenSigTimeoutTime" BU_SG_REL_ VCM SG_ 386 PoorAirPressureInfo_ISig_3 300;
BA_REL_ "GenSigFirstTimeoutTime" BU_SG_REL_ VCM SG_ 386 RGHDetect_ActiveProcess 3000;
BA_REL_ "GenSigTimeoutTime" BU_SG_REL_ VCM SG_ 386 RGHDetect_ActiveProcess 300;
BA_REL_ "GenSigFirstTimeoutTime" BU_SG_REL_ VCM SG_ 386 XPRGSystemCap_Priority_ISig_3 3000;
BA_REL_ "GenSigTimeoutTime" BU_SG_REL_ VCM SG_ 386 XPRGSystemCap_Priority_ISig_3 300;
BA_REL_ "GenSigFirstTimeoutTime" BU_SG_REL_ VCM SG_ 386 XPRGSystemCap_AllowedPBApp_ISig_ 3000;
BA_REL_ "GenSigTimeoutTime" BU_SG_REL_ VCM SG_ 386 XPRGSystemCap_AllowedPBApp_ISig_ 300;
BA_REL_ "GenSigFirstTimeoutTime" BU_SG_REL_ VCM SG_ 386 XPRGSystemCap_AllowedPBRel_ISig_ 3000;
BA_REL_ "GenSigTimeoutTime" BU_SG_REL_ VCM SG_ 386 XPRGSystemCap_AllowedPBRel_ISig_ 300;
BA_REL_ "GenSigFirstTimeoutTime" BU_SG_REL_ VCM SG_ 386 AirProductionRqst 3000;
BA_REL_ "GenSigTimeoutTime" BU_SG_REL_ VCM SG_ 386 AirProductionRqst 300;
BA_REL_ "GenSigFirstTimeoutTime" BU_SG_REL_ VCM SG_ 386 XPRGSystemCap_AllowedDeflation_I 3000;
BA_REL_ "GenSigTimeoutTime" BU_SG_REL_ VCM SG_ 386 XPRGSystemCap_AllowedDeflation_I 300;
BA_REL_ "GenSigFirstTimeoutTime" BU_SG_REL_ VCM SG_ 386 XPRGSystemCap_AllowedInflation_I 3000;
BA_REL_ "GenSigTimeoutTime" BU_SG_REL_ VCM SG_ 386 XPRGSystemCap_AllowedInflation_I 300;
BA_REL_ "GenSigFirstTimeoutTime" BU_SG_REL_ EBS SG_ 386 EPBHSARequest 3000;
BA_REL_ "GenSigTimeoutTime" BU_SG_REL_ EBS SG_ 386 EPBHSARequest 300;
BA_REL_ "GenSigFirstTimeoutTime" BU_SG_REL_ VCM SG_ 386 EPBHSARequest 3000;
BA_REL_ "GenSigTimeoutTime" BU_SG_REL_ VCM SG_ 386 EPBHSARequest 300;
BA_REL_ "GenSigFirstTimeoutTime" BU_SG_REL_ VCM SG_ 386 XPRGSystemCap_AllowedInfInhibit_ 3000;
BA_REL_ "GenSigTimeoutTime" BU_SG_REL_ VCM SG_ 386 XPRGSystemCap_AllowedInfInhibit_ 300;
BA_REL_ "GenSigFirstTimeoutTime" BU_SG_REL_ VCM SG_ 386 XPRGSystemCap_CRC_ISig_3 3000;
BA_REL_ "GenSigTimeoutTime" BU_SG_REL_ VCM SG_ 386 XPRGSystemCap_CRC_ISig_3 300;
BA_REL_ "GenSigFirstTimeoutTime" BU_SG_REL_ VCM SG_ 260 OverrunMode_stat 3000;
BA_REL_ "GenSigTimeoutTime" BU_SG_REL_ VCM SG_ 260 OverrunMode_stat 180;
BA_REL_ "GenSigFirstTimeoutTime" BU_SG_REL_ VCM SG_ 260 EPBPowerFeedRequest_ISig_3 3000;
BA_REL_ "GenSigTimeoutTime" BU_SG_REL_ VCM SG_ 260 EPBPowerFeedRequest_ISig_3 180;
BA_REL_ "GenSigFirstTimeoutTime" BU_SG_REL_ VCM SG_ 260 AirDryerCurrentAirVolNotRegen 3000;
BA_REL_ "GenSigTimeoutTime" BU_SG_REL_ VCM SG_ 260 AirDryerCurrentAirVolNotRegen 180;
BA_REL_ "GenSigFirstTimeoutTime" BU_SG_REL_ EBS SG_ 260 ParkBrakeReleaseMode2_ISig_3 3000;
BA_REL_ "GenSigTimeoutTime" BU_SG_REL_ EBS SG_ 260 ParkBrakeReleaseMode2_ISig_3 180;
BA_REL_ "GenSigFirstTimeoutTime" BU_SG_REL_ VCM SG_ 260 ParkBrakeReleaseMode2_ISig_3 3000;
BA_REL_ "GenSigTimeoutTime" BU_SG_REL_ VCM SG_ 260 ParkBrakeReleaseMode2_ISig_3 180;
BA_REL_ "GenSigFirstTimeoutTime" BU_SG_REL_ EBS SG_ 260 LowVMPBInfoReq 3000;
BA_REL_ "GenSigTimeoutTime" BU_SG_REL_ EBS SG_ 260 LowVMPBInfoReq 180;
BA_REL_ "GenSigFirstTimeoutTime" BU_SG_REL_ VCM SG_ 260 LowVMPBInfoReq 3000;
BA_REL_ "GenSigTimeoutTime" BU_SG_REL_ VCM SG_ 260 LowVMPBInfoReq 180;
BA_REL_ "GenSigFirstTimeoutTime" BU_SG_REL_ VCM SG_ 260 ParkBrakeWorkshopMode_ISig_3 3000;
BA_REL_ "GenSigTimeoutTime" BU_SG_REL_ VCM SG_ 260 ParkBrakeWorkshopMode_ISig_3 180;
BA_REL_ "GenSigFirstTimeoutTime" BU_SG_REL_ VCM SG_ 260 AirDryerCartridgeReset_ack 3000;
BA_REL_ "GenSigTimeoutTime" BU_SG_REL_ VCM SG_ 260 AirDryerCartridgeReset_ack 180;
BA_REL_ "GenSigFirstTimeoutTime" BU_SG_REL_ VCM SG_ 256 XBRPB_Priority 3000;
BA_REL_ "GenSigTimeoutTime" BU_SG_REL_ VCM SG_ 256 XBRPB_Priority 120;
BA_REL_ "GenSigFirstTimeoutTime" BU_SG_REL_ VCM SG_ 256 ParkingBrake_stat_ISig_3 3000;
BA_REL_ "GenSigTimeoutTime" BU_SG_REL_ VCM SG_ 256 ParkingBrake_stat_ISig_3 120;
BA_REL_ "GenSigFirstTimeoutTime" BU_SG_REL_ FAS SG_ 256 ParkingBrake_stat_ISig_3 3000;
BA_REL_ "GenSigTimeoutTime" BU_SG_REL_ FAS SG_ 256 ParkingBrake_stat_ISig_3 120;
BA_REL_ "GenSigFirstTimeoutTime" BU_SG_REL_ EBS SG_ 256 ParkingBrake_stat_ISig_3 3000;
BA_REL_ "GenSigTimeoutTime" BU_SG_REL_ EBS SG_ 256 ParkingBrake_stat_ISig_3 120;
BA_REL_ "GenSigFirstTimeoutTime" BU_SG_REL_ VCM SG_ 256 XBRPB_CompensationMode 3000;
BA_REL_ "GenSigTimeoutTime" BU_SG_REL_ VCM SG_ 256 XBRPB_CompensationMode 120;
BA_REL_ "GenSigFirstTimeoutTime" BU_SG_REL_ VCM SG_ 256 XBRPB_EBIMode 3000;
BA_REL_ "GenSigTimeoutTime" BU_SG_REL_ VCM SG_ 256 XBRPB_EBIMode 120;
BA_REL_ "GenSigFirstTimeoutTime" BU_SG_REL_ VCM SG_ 256 XBRPB_SqC 3000;
BA_REL_ "GenSigTimeoutTime" BU_SG_REL_ VCM SG_ 256 XBRPB_SqC 120;
BA_REL_ "GenSigFirstTimeoutTime" BU_SG_REL_ VCM SG_ 256 XBRPB_CRC 3000;
BA_REL_ "GenSigTimeoutTime" BU_SG_REL_ VCM SG_ 256 XBRPB_CRC 120;
BA_REL_ "GenSigFirstTimeoutTime" BU_SG_REL_ VCM SG_ 256 XBRPB_ExtAccelDemand 3000;
BA_REL_ "GenSigTimeoutTime" BU_SG_REL_ VCM SG_ 256 XBRPB_ExtAccelDemand 120;
BA_REL_ "GenSigFirstTimeoutTime" BU_SG_REL_ VCM SG_ 256 ParkBrakeActuationStatus_ISig_3 3000;
BA_REL_ "GenSigTimeoutTime" BU_SG_REL_ VCM SG_ 256 ParkBrakeActuationStatus_ISig_3 120;
BA_REL_ "GenSigFirstTimeoutTime" BU_SG_REL_ EBS SG_ 256 ParkBrakeActuationStatus_ISig_3 3000;
BA_REL_ "GenSigTimeoutTime" BU_SG_REL_ EBS SG_ 256 ParkBrakeActuationStatus_ISig_3 120;
BA_REL_ "GenSigFirstTimeoutTime" BU_SG_REL_ VCM SG_ 256 XBRPB_ControlMode 3000;
BA_REL_ "GenSigTimeoutTime" BU_SG_REL_ VCM SG_ 256 XBRPB_ControlMode 120;
BA_REL_ "GenSigFirstTimeoutTime" BU_SG_REL_ VCM SG_ 256 XBRPB_Urgency 3000;
BA_REL_ "GenSigTimeoutTime" BU_SG_REL_ VCM SG_ 256 XBRPB_Urgency 120;
VAL_ 592 CpbtyAxle3_BrkEgyCpctyQltyLe 3 "SignalQlty_NotAvailable" 2 "SignalQlty_Error" 1 "SignalQlty_Degraded" 0 "SignalQlty_Operational" ;
VAL_ 592 CpbtyAxle3_TqCpbtyRateQltyRi 3 "SignalQlty_NotAvailable" 2 "SignalQlty_Error" 1 "SignalQlty_Degraded" 0 "SignalQlty_Operational" ;
VAL_ 592 CpbtyAxle1_PadWearQltyLe 3 "SignalQlty_NotAvailable" 2 "SignalQlty_Error" 1 "SignalQlty_Degraded" 0 "SignalQlty_Operational" ;
VAL_ 592 CpbtyAxle1_SlipCtrlEna 3 "DisableEnable_NotAvailable" 2 "DisableEnable_Error" 1 "DisableEnable_Enable" 0 "DisableEnable_Disable" ;
VAL_ 592 CpbtyAxle3_TqCpbtyRateQltyLe 3 "SignalQlty_NotAvailable" 2 "SignalQlty_Error" 1 "SignalQlty_Degraded" 0 "SignalQlty_Operational" ;
VAL_ 592 CpbtyAxle1_BrkEgyCpctyQltyRi 3 "SignalQlty_NotAvailable" 2 "SignalQlty_Error" 1 "SignalQlty_Degraded" 0 "SignalQlty_Operational" ;
VAL_ 592 CpbtyAxle2_BrkEgyCpctyQltyLe 3 "SignalQlty_NotAvailable" 2 "SignalQlty_Error" 1 "SignalQlty_Degraded" 0 "SignalQlty_Operational" ;
VAL_ 592 CpbtyAxle3_SlipCtrlEna 3 "DisableEnable_NotAvailable" 2 "DisableEnable_Error" 1 "DisableEnable_Enable" 0 "DisableEnable_Disable" ;
VAL_ 592 CpbtyAxle3_TqCpbtyQltyLe 3 "SignalQlty_NotAvailable" 2 "SignalQlty_Error" 1 "SignalQlty_Degraded" 0 "SignalQlty_Operational" ;
VAL_ 592 CpbtyAxle1_TqCpbtyQltyLe 3 "SignalQlty_NotAvailable" 2 "SignalQlty_Error" 1 "SignalQlty_Degraded" 0 "SignalQlty_Operational" ;
VAL_ 592 CpbtyAxle3_BrkEgyCpctyQltyRi 3 "SignalQlty_NotAvailable" 2 "SignalQlty_Error" 1 "SignalQlty_Degraded" 0 "SignalQlty_Operational" ;
VAL_ 592 CpbtyAxle3_TqCpbtyQltyRi 3 "SignalQlty_NotAvailable" 2 "SignalQlty_Error" 1 "SignalQlty_Degraded" 0 "SignalQlty_Operational" ;
VAL_ 592 CpbtyAxle2_BrkEgyCpctyQltyRi 3 "SignalQlty_NotAvailable" 2 "SignalQlty_Error" 1 "SignalQlty_Degraded" 0 "SignalQlty_Operational" ;
VAL_ 592 CpbtyAxle2_TqCpbtyQltyRi 3 "SignalQlty_NotAvailable" 2 "SignalQlty_Error" 1 "SignalQlty_Degraded" 0 "SignalQlty_Operational" ;
VAL_ 592 CpbtyAxle2_PadWearQltyRi 3 "SignalQlty_NotAvailable" 2 "SignalQlty_Error" 1 "SignalQlty_Degraded" 0 "SignalQlty_Operational" ;
VAL_ 592 CpbtyAxle3_PadWearQltyRi 3 "SignalQlty_NotAvailable" 2 "SignalQlty_Error" 1 "SignalQlty_Degraded" 0 "SignalQlty_Operational" ;
VAL_ 592 CpbtyAxle2_TqCpbtyRateQltyRi 3 "SignalQlty_NotAvailable" 2 "SignalQlty_Error" 1 "SignalQlty_Degraded" 0 "SignalQlty_Operational" ;
VAL_ 592 CpbtyAxle2_SlipCtrlEna 3 "DisableEnable_NotAvailable" 2 "DisableEnable_Error" 1 "DisableEnable_Enable" 0 "DisableEnable_Disable" ;
VAL_ 592 CpbtyAxle1_TqCpbtyRateQltyRi 3 "SignalQlty_NotAvailable" 2 "SignalQlty_Error" 1 "SignalQlty_Degraded" 0 "SignalQlty_Operational" ;
VAL_ 592 CpbtyAxle1_PadWearQltyRi 3 "SignalQlty_NotAvailable" 2 "SignalQlty_Error" 1 "SignalQlty_Degraded" 0 "SignalQlty_Operational" ;
VAL_ 592 CpbtyAxle3_PadWearQltyLe 3 "SignalQlty_NotAvailable" 2 "SignalQlty_Error" 1 "SignalQlty_Degraded" 0 "SignalQlty_Operational" ;
VAL_ 592 CpbtyAxle1_TqCpbtyRateQltyLe 3 "SignalQlty_NotAvailable" 2 "SignalQlty_Error" 1 "SignalQlty_Degraded" 0 "SignalQlty_Operational" ;
VAL_ 592 CpbtyAxle1_TqCpbtyQltyRi 3 "SignalQlty_NotAvailable" 2 "SignalQlty_Error" 1 "SignalQlty_Degraded" 0 "SignalQlty_Operational" ;
VAL_ 592 CpbtyAxle2_TqCpbtyQltyLe 3 "SignalQlty_NotAvailable" 2 "SignalQlty_Error" 1 "SignalQlty_Degraded" 0 "SignalQlty_Operational" ;
VAL_ 592 CpbtyAxle2_TqCpbtyRateQltyLe 3 "SignalQlty_NotAvailable" 2 "SignalQlty_Error" 1 "SignalQlty_Degraded" 0 "SignalQlty_Operational" ;
VAL_ 592 CpbtyAxle1_BrkEgyCpctyQltyLe 3 "SignalQlty_NotAvailable" 2 "SignalQlty_Error" 1 "SignalQlty_Degraded" 0 "SignalQlty_Operational" ;
VAL_ 592 CpbtyAxle2_PadWearQltyLe 3 "SignalQlty_NotAvailable" 2 "SignalQlty_Error" 1 "SignalQlty_Degraded" 0 "SignalQlty_Operational" ;
VAL_ 1105 XBRSystemState_ISig_3 3 "XBRSystemState_NotAvailable" 2 "XBRSystemState_NoExternalBrakeDemandAccepted" 1 "XBRSystemState_OnlyHighestXBRPriorityDemandAccepted" 0 "XBRSystemState_ExternalBrakeDemandAccepted" ;
VAL_ 1105 ABSFullyOperational_ISig_3 3 "FullyOperational_NotAvailable" 2 "FullyOperational_Reserved" 1 "FullyOperational_FullyOperational" 0 "FullyOperational_NotFullyOperational" ;
VAL_ 1105 TrailerCommunicationType_ISig_3 7 "TrailerCommunicationType_NotAvailable" 6 "TrailerCommunicationType_Error" 5 "TrailerCommunicationType_Spare3" 4 "TrailerCommunicationType_Spare2" 3 "TrailerCommunicationType_Spare1" 2 "TrailerCommunicationType_SAE_J2497_Communication" 1 "TrailerCommunicationType_ISO_11992_2_Communication" 0 "TrailerCommunicationType_NoCommunication" ;
VAL_ 439 ABSAxle5Active 3 "OffOn_NotAvailable" 2 "OffOn_Error" 1 "OffOn_On" 0 "OffOn_Off" ;
VAL_ 439 Trailer1TractionHelp_ISig_3 3 "InactiveActive_NotAvailable" 2 "InactiveActive_Error" 1 "InactiveActive_Active" 0 "InactiveActive_Inactive" ;
VAL_ 439 EBSBrakeSwitch_ISig_3 3 "EBSBrakeSwitch_NotAvailable" 2 "EBSBrakeSwitch_Error" 1 "EBSBrakeSwitch_BrakePedalDepressed" 0 "EBSBrakeSwitch_BrakePedalReleased" ;
VAL_ 439 EACompound_SystemState 3 "OperationalState_NotAvailable" 2 "OperationalState_Error" 1 "OperationalState_FullyOperational" 0 "OperationalState_NotOperational" ;
VAL_ 439 AntiLockBrakingActive_ISig_3 3 "AntiLockBrakingActive_NotAvailable" 2 "AntiLockBrakingActive_Reserved" 1 "AntiLockBrakingActive_ABSActive" 0 "AntiLockBrakingActive_ABSPassiveButInstalled" ;
VAL_ 439 StretchBrake_Stat_ISig_3 7 "StretchBrake_Stat_NotAvailable" 6 "StretchBrake_Stat_Error" 5 "StretchBrake_Stat_Spare_02" 4 "StretchBrake_Stat_Spare_01" 3 "StretchBrake_Stat_Spare" 2 "StretchBrake_Stat_Active" 1 "StretchBrake_Stat_Enabled" 0 "StretchBrake_Stat_Disabled" ;
VAL_ 439 HillHolderMode_ISig_3 7 "HillHolderMode_NotAvailable" 6 "HillHolderMode_Reserved" 5 "HillHolderMode_Spare2" 4 "HillHolderMode_Spare1" 3 "HillHolderMode_OnHold_PressureApplied" 2 "HillHolderMode_Active_WillChangeToInactiveSoon" 1 "HillHolderMode_Active" 0 "HillHolderMode_Inactive" ;
VAL_ 439 ABSAxle4Active 3 "OffOn_NotAvailable" 2 "OffOn_Error" 1 "OffOn_On" 0 "OffOn_Off" ;
VAL_ 439 TrailerBrake_Stat_ISig_3 3 "InactiveActive_NotAvailable" 2 "InactiveActive_Error" 1 "InactiveActive_Active" 0 "InactiveActive_Inactive" ;
VAL_ 439 ABSAxle2Active 3 "OffOn_NotAvailable" 2 "OffOn_Error" 1 "OffOn_On" 0 "OffOn_Off" ;
VAL_ 439 TrailerEBSAmberWarning_ISig_3 3 "OffOn_NotAvailable" 2 "OffOn_Error" 1 "OffOn_On" 0 "OffOn_Off" ;
VAL_ 439 ABSAxle1Active 3 "OffOn_NotAvailable" 2 "OffOn_Error" 1 "OffOn_On" 0 "OffOn_Off" ;
VAL_ 439 ABSAxle3Active 3 "OffOn_NotAvailable" 2 "OffOn_Error" 1 "OffOn_On" 0 "OffOn_Off" ;
VAL_ 439 PusherLiftAxleLoweringInhibit_IS 3 "InhibitStatus_NotAvailable" 2 "InhibitStatus_Reserved" 1 "InhibitStatus_Inhibited" 0 "InhibitStatus_NotInhibited" ;
VAL_ 439 CombinedWheelSpeed_Quality 7 "Quality3bit_NotAvailable" 6 "Quality3bit_Error" 5 "Quality3bit_Reserved4" 4 "Quality3bit_ASIL_D" 3 "Quality3bit_Reserved3" 2 "Quality3bit_Reserved2" 1 "Quality3bit_Reserved1" 0 "Quality3bit_ASIL_QM" ;
VAL_ 439 SplitBoxDiffLockActvnFuncReq_ISi 3 "DisengageEngage_NotAvailable" 2 "DisengageEngage_Error" 1 "DisengageEngage_Engage" 0 "DisengageEngage_Disengage" ;
VAL_ 439 SteerableLiftAxleLoweringInhib 3 "InhibitStatus_NotAvailable" 2 "InhibitStatus_Reserved" 1 "InhibitStatus_Inhibited" 0 "InhibitStatus_NotInhibited" ;
VAL_ 439 BrakingSystemPressureLim_rqst_IS 3 "Request_NotAvailable" 2 "Request_Error" 1 "Request_RequestActive" 0 "Request_NotRequested" ;
VAL_ 439 ScndRrAxlDiffLckActvnFuncReq_ISi 3 "RearAxleDiffLockActvnFuncReq_TakeNoAction" 2 "RearAxleDiffLockActvnFuncReq_Reserved" 1 "RearAxleDiffLockActvnFuncReq_DisengageDifferentialLock" 0 "RearAxleDiffLockActvnFuncReq_EngageDifferentialLock" ;
VAL_ 439 HSAState 3 "HSAState_NotAvailable" 2 "HSAState_HSA_FunctionFullyOperational" 1 "HSAState_HSA_FunctionnotWorking" 0 "HSAState_HSA_FunctionRestrictedFunctionalityAvailable" ;
VAL_ 315 SteeringWheelAngleSensorType 3 "SteeringWheelAngleSensorType_NotAvailable" 2 "SteeringWheelAngleSensorType_Reserved" 1 "SteeringWheelAngleSensorType_AbsoluteMeasuringPrinciple" 0 "SteeringWheelAngleSensorType_RelativeMeasuringPrinciple" ;
VAL_ 315 BrakeLightActivationRequest_ISig 3 "OffOn_NotAvailable" 2 "OffOn_Error" 1 "OffOn_On" 0 "OffOn_Off" ;
VAL_ 315 VDCBrakeLightRequest_ISig_3 3 "VDCBrakeLightRequest_DontCareTakeNoAction" 2 "VDCBrakeLightRequest_Reserved" 1 "VDCBrakeLightRequest_TurnBrakeLightON" 0 "VDCBrakeLightRequest_TurnBrakeLightOFF" ;
VAL_ 640 APMSafetyWarning_YellowRqst_ISig 3 "NoRequestRequest_NotAvailable" 2 "NoRequestRequest_Error" 1 "NoRequestRequest_Request" 0 "NoRequestRequest_NoRequest" ;
VAL_ 640 TrailerStatus_IntegrityLvl_ISig_ 3 "IntegrityLvl_HighIntegrity" 2 "IntegrityLvl_Spare" 1 "IntegrityLvl_LowIntegrity" 0 "IntegrityLvl_Downgraded" ;
VAL_ 640 LowAirPressureAlert_ISig_3 3 "LowAirPressureAlert_NotAvailable" 2 "LowAirPressureAlert_Error" 1 "LowAirPressureAlert_LowPressure" 0 "LowAirPressureAlert_NormalPressure" ;
VAL_ 640 DynamicPB_ActiveStatus 7 "DynamicPBActiveStatus_NotAvailable" 6 "DynamicPBActiveStatus_Error" 5 "DynamicPBActiveStatus_Spare4" 4 "DynamicPBActiveStatus_Spare3" 3 "DynamicPBActiveStatus_Spare2" 2 "DynamicPBActiveStatus_NotOperational" 1 "DynamicPBActiveStatus_Spare1" 0 "DynamicPBActiveStatus_FullyOperational" ;
VAL_ 640 PB2HCUAreaCopy 7 "HCUArea_NotAvailable" 6 "HCUArea_Error" 5 "HCUArea_ReleaseArea" 4 "HCUArea_NeutralArea" 3 "HCUArea_ProportionalArea" 2 "HCUArea_ActuationArea" 1 "HCUArea_TrailerTestArea" 0 "HCUArea_ActuationAreaOrTrailerTestArea" ;
VAL_ 640 TrailerStatus_Actuation_ISig_3 7 "TrailerStatusActuation_NotAvailable" 6 "TrailerStatusActuation_Error" 5 "TrailerStatusActuation_Spare3" 4 "TrailerStatusActuation_Spare2" 3 "TrailerStatusActuation_Spare1" 2 "TrailerStatusActuation_Deflated" 1 "TrailerStatusActuation_Intermediate" 0 "TrailerStatusActuation_Inflated" ;
VAL_ 640 RedGladHand_ConnectStatus_ISig_3 3 "TLConnectStatus_NotAvailable" 2 "TLConnectStatus_Unknown" 1 "TLConnectStatus_Attached" 0 "TLConnectStatus_Detached" ;
VAL_ 640 PBHCUAreaCopy 7 "HCUArea_NotAvailable" 6 "HCUArea_Error" 5 "HCUArea_ReleaseArea" 4 "HCUArea_NeutralArea" 3 "HCUArea_ProportionalArea" 2 "HCUArea_ActuationArea" 1 "HCUArea_TrailerTestArea" 0 "HCUArea_ActuationAreaOrTrailerTestArea" ;
VAL_ 640 PBStatus_IntegrityLvl_ISig_3 3 "PBIntegrityLvl_HighIntegrity" 2 "PBIntegrityLvl_Spare" 1 "PBIntegrityLvl_LowIntegrity" 0 "PBIntegrityLvl_Downgraded" ;
VAL_ 640 AutoPBRelease_stat_ISig_3 3 "AutoPBRelease_stat_NotAvailable" 2 "AutoPBRelease_stat_Error" 1 "AutoPBRelease_stat_FunctionInhibited" 0 "AutoPBRelease_stat_FunctionAvailable" ;
VAL_ 640 TrHCUAreaCopy 7 "HCUArea_NotAvailable" 6 "HCUArea_Error" 5 "HCUArea_ReleaseArea" 4 "HCUArea_NeutralArea" 3 "HCUArea_ProportionalArea" 2 "HCUArea_ActuationArea" 1 "HCUArea_TrailerTestArea" 0 "HCUArea_ActuationAreaOrTrailerTestArea" ;
VAL_ 640 TrailerSupplyInflationMode 15 "TrailerSupplyInflationMode_NotAvailable" 14 "TrailerSupplyInflationMode_Error" 13 "TrailerSupplyInflationMode_Reserved7" 12 "TrailerSupplyInflationMode_Reserved6" 11 "TrailerSupplyInflationMode_Reserved5" 10 "TrailerSupplyInflationMode_Reserved4" 9 "TrailerSupplyInflationMode_Reserved3" 8 "TrailerSupplyInflationMode_Reserved2" 7 "TrailerSupplyInflationMode_RedundantExternalDemand" 6 "TrailerSupplyInflationMode_Reserved1" 5 "TrailerSupplyInflationMode_AutomaticInBackup" 4 "TrailerSupplyInflationMode_MainExternalDemand" 3 "TrailerSupplyInflationMode_AutomaticallyAtPreTakeOff" 2 "TrailerSupplyInflationMode_ManuallyAtStandstill" 1 "TrailerSupplyInflationMode_ManuallyInDriving" 0 "TrailerSupplyInflationMode_Idle" ;
VAL_ 640 TLInflationAcceptance_stat_ISig_ 7 "TLInflationAccept_stat_NotAvailable" 6 "TLInflationAccept_stat_Error" 5 "TLInflationAccept_stat_Spare4" 4 "TLInflationAccept_stat_Spare3" 3 "TLInflationAccept_stat_Spare2" 2 "TLInflationAccept_stat_TrailerInflationAccepted" 1 "TLInflationAccept_stat_BrakePedalRequested" 0 "TLInflationAccept_stat_NoRequestDetectedOrRequestAborted" ;
VAL_ 640 TrailerInflationPossible_stat_IS 3 "TrailerInflationPossible_stat_NotAvailable" 2 "TrailerInflationPossible_stat_Error" 1 "TrailerInflationPossible_stat_PossiblePressureOK" 0 "TrailerInflationPossible_stat_NotPossibleLowerPressure" ;
VAL_ 640 APMSafetyWarning_RedRqst_ISig_3 3 "NotRequested_NotAvailable" 2 "NotRequested_Error" 1 "NotRequested_Requested" 0 "NotRequested_NotRequested" ;
VAL_ 640 RedGladHand_ConfidenceLvl_ISig_3 3 "LowHigh_NotAvailable" 2 "LowHigh_Error" 1 "LowHigh_High" 0 "LowHigh_Low" ;
VAL_ 640 TrailerSupplyDeflationMode 15 "TrailerSupplyDeflationMode_NotAvailable" 14 "TrailerSupplyDeflationMode_Error" 13 "TrailerSupplyDeflationMode_Reserved8" 12 "TrailerSupplyDeflationMode_Reserved7" 11 "TrailerSupplyDeflationMode_Reserved6" 10 "TrailerSupplyDeflationMode_Reserved5" 9 "TrailerSupplyDeflationMode_Reserved4" 8 "TrailerSupplyDeflationMode_Reserved3" 7 "TrailerSupplyDeflationMode_Reserved2" 6 "TrailerSupplyDeflationMode_TearOffDetected" 5 "TrailerSupplyDeflationMode_RedundantExternalDemand" 4 "TrailerSupplyDeflationMode_MainExternalDemand" 3 "TrailerSupplyDeflationMode_AtTractorPBApplication" 2 "TrailerSupplyDeflationMode_ManuallyAtStandstill" 1 "TrailerSupplyDeflationMode_ManuallyInDriving" 0 "TrailerSupplyDeflationMode_Idle" ;
VAL_ 640 AirProdPressureRangeModeStatus 15 "AirProdPressureRangeModeStatus_NotAvailable" 14 "AirProdPressureRangeModeStatus_Error" 13 "AirProdPressureRangeModeStatus_HighPrioOrInterRegActive" 12 "AirProdPressureRangeModeStatus_Mode12Active" 11 "AirProdPressureRangeModeStatus_CPEorFinalRegActive" 10 "AirProdPressureRangeModeStatus_EngineStartHelpActive" 9 "AirProdPressureRangeModeStatus_SoftPressureModeActive" 8 "AirProdPressureRangeModeStatus_BrakePressureLimitationActive" 7 "AirProdPressureRangeModeStatus_Mode7Active" 6 "AirProdPressureRangeModeStatus_Mode6Active" 5 "AirProdPressureRangeModeStatus_Mode5Active" 4 "AirProdPressureRangeModeStatus_LowSpeedModeActive" 3 "AirProdPressureRangeModeStatus_OvertakeModeActive" 2 "AirProdPressureRangeModeStatus_OverunModeActive" 1 "AirProdPressureRangeModeStatus_DefaultModeActive" 0 "AirProdPressureRangeModeStatus_NoControlActive" ;
VAL_ 640 PBStatus_Actuation_ISig_3 7 "PBActuationStatus_NotAvailable" 6 "PBActuationStatus_Error" 5 "PBActuationStatus_Spare3" 4 "PBActuationStatus_Spare2" 3 "PBActuationStatus_Spare1" 2 "PBActuationStatus_Parked" 1 "PBActuationStatus_Intermediate" 0 "PBActuationStatus_Released" ;
VAL_ 386 XPRGSystemState_AppliedPriority 15 "XPRGAppliedPriority_NotAvailable" 14 "XPRGAppliedPriority_Error" 13 "XPRGAppliedPriority_Spare7" 12 "XPRGAppliedPriority_Spare6" 11 "XPRGAppliedPriority_Spare5" 10 "XPRGAppliedPriority_Spare4" 9 "XPRGAppliedPriority_Spare3" 8 "XPRGAppliedPriority_Spare2" 7 "XPRGAppliedPriority_Spare1" 6 "XPRGAppliedPriority_RedundantSubHighPrio" 5 "XPRGAppliedPriority_HighPrio" 4 "XPRGAppliedPriority_RedundantSubMediumPrio" 3 "XPRGAppliedPriority_MediumPrio" 2 "XPRGAppliedPriority_RedundantSubNormalPrio" 1 "XPRGAppliedPriority_NormalPrio" 0 "XPRGAppliedPriority_NoRequest" ;
VAL_ 386 UnLoaderValveStatus 3 "ClosedOpen_NotAvailable" 2 "ClosedOpen_Error" 1 "ClosedOpen_Open" 0 "ClosedOpen_Closed" ;
VAL_ 386 PBStatusDisplay_cmd_ISig_3 3 "DisableEnable_NotAvailable" 2 "DisableEnable_Error" 1 "DisableEnable_Enable" 0 "DisableEnable_Disable" ;
VAL_ 386 ParkBrakeApplicationMode2_ISig_3 15 "ParkBrakeApplicationMode2_NotAvailable" 14 "ParkBrakeApplicationMode2_Error" 13 "ParkBrakeApplicationMode2_Reserved5" 12 "ParkBrakeApplicationMode2_Reserved4" 11 "ParkBrakeApplicationMode2_Reserved3" 10 "ParkBrakeApplicationMode2_Reserved2" 9 "ParkBrakeApplicationMode2_RedundantExternalDemand" 8 "ParkBrakeApplicationMode2_AutomaticcallyDoorOpen" 7 "ParkBrakeApplicationMode2_ParkBrakeBlending" 6 "ParkBrakeApplicationMode2_AutomaticallyHillHolder" 5 "ParkBrakeApplicationMode2_AutomaticInBackup" 4 "ParkBrakeApplicationMode2_MainExternalDemand" 3 "ParkBrakeApplicationMode2_AutomaticallyKeyOff" 2 "ParkBrakeApplicationMode2_ManuallyAtStandstill" 1 "ParkBrakeApplicationMode2_ManuallyInDriving" 0 "ParkBrakeApplicationMode2_Idle" ;
VAL_ 386 XPRGSystemCap_AllowedRelInhibit_ 7 "XPRG_OperationalStat_NotAvailable" 6 "XPRG_OperationalStat_Error" 5 "XPRG_OperationalStat_Spare3" 4 "XPRG_OperationalStat_Spare2" 3 "XPRG_OperationalStat_Spare1" 2 "XPRG_OperationalStat_OperationalAndActive" 1 "XPRG_OperationalStat_OperationalButNotActive" 0 "XPRG_OperationalStat_NotOperational" ;
VAL_ 386 ParkBrakeReleasePossible_stat_IS 3 "ParkBrakeReleasePossible_stat_NotAvailable" 2 "ParkBrakeReleasePossible_stat_Error" 1 "ParkBrakeReleasePossible_stat_Possible_PressureOK" 0 "ParkBrakeReleasePossible_stat_NotPossible_LowerPressure" ;
VAL_ 386 PBReleaseAcceptance_stat_ISig_3 7 "PBReleaseAcceptance_stat_NotAvailable" 6 "PBReleaseAcceptance_stat_Error" 5 "PBReleaseAcceptance_stat_Spare_03" 4 "PBReleaseAcceptance_stat_AccelPedalOrHCURequested" 3 "PBReleaseAcceptance_stat_ReleaseRequestAccepted" 2 "PBReleaseAcceptance_stat_BrakeOrAccelPedalRequested" 1 "PBReleaseAcceptance_stat_BrakePedalRequested" 0 "PBReleaseAcceptance_stat_NoRequestDetectedOrRequestAborted" ;
VAL_ 386 AirCompressorStatus_ISig_3 3 "InactiveActive_NotAvailable" 2 "InactiveActive_Error" 1 "InactiveActive_Active" 0 "InactiveActive_Inactive" ;
VAL_ 386 TrailerTest_stat_ISig_3 7 "TrailerTest_stat_NotAvailable" 6 "TrailerTest_stat_Error" 5 "TrailerTest_stat_InProgress_TrailerNotConnected" 4 "TrailerTest_stat_NotPossibleLowVoltgeOrLowPressure" 3 "TrailerTest_stat_TrailerTestIncentive" 2 "TrailerTest_stat_NotPossibleServiceBrakeApplied" 1 "TrailerTest_stat_InProgress" 0 "TrailerTest_stat_IdleNoTrailerTest" ;
VAL_ 386 PoorAirPressureInfo_ISig_3 3 "PoorAirPressureInfo_NotAvailable" 2 "PoorAirPressureInfo_Error" 1 "PoorAirPressureInfo_PoorAirPressure" 0 "PoorAirPressureInfo_NormalPressure" ;
VAL_ 386 RGHDetect_ActiveProcess 3 "ActiveProcess_NotAvailable" 2 "ActiveProcess_Error" 1 "ActiveProcess_ActiveOrUnderCheck" 0 "ActiveProcess_Inactive" ;
VAL_ 386 XPRGSystemCap_Priority_ISig_3 7 "XPRGPriority3bit_NotAvailable" 6 "XPRGPriority3bit_Error" 5 "XPRGPriority3bit_Spare2" 4 "XPRGPriority3bit_Spare1" 3 "XPRGPriority3bit_High" 2 "XPRGPriority3bit_Medium" 1 "XPRGPriority3bit_Normal" 0 "XPRGPriority3bit_NoPriority" ;
VAL_ 386 AirProductionRqst 3 "Request_NotAvailable" 2 "Request_Error" 1 "Request_RequestActive" 0 "Request_NotRequested" ;
VAL_ 386 EPBHSARequest 7 "EPBHSARequest_NotAvailable" 6 "EPBHSARequest_Error" 5 "EPBHSARequest_Spare_3" 4 "EPBHSARequest_Spare_2" 3 "EPBHSARequest_Spare_1" 2 "EPBHSARequest_Requested" 1 "EPBHSARequest_NotRequestedReleaseWhenPossible" 0 "EPBHSARequest_NotRequestedReleaseImmediately" ;
VAL_ 386 XPRGSystemCap_AllowedInfInhibit_ 7 "XPRG_OperationalStat_NotAvailable" 6 "XPRG_OperationalStat_Error" 5 "XPRG_OperationalStat_Spare3" 4 "XPRG_OperationalStat_Spare2" 3 "XPRG_OperationalStat_Spare1" 2 "XPRG_OperationalStat_OperationalAndActive" 1 "XPRG_OperationalStat_OperationalButNotActive" 0 "XPRG_OperationalStat_NotOperational" ;
VAL_ 260 OverrunMode_stat 3 "InactiveActive_NotAvailable" 2 "InactiveActive_Error" 1 "InactiveActive_Active" 0 "InactiveActive_Inactive" ;
VAL_ 260 EPBPowerFeedRequest_ISig_3 3 "Request_NotAvailable" 2 "Request_Error" 1 "Request_RequestActive" 0 "Request_NotRequested" ;
VAL_ 260 ParkBrakeReleaseMode2_ISig_3 15 "ParkBrakeReleaseMode2_NotAvailable" 14 "ParkBrakeReleaseMode2_Error" 13 "ParkBrakeReleaseMode2_Reserved7" 12 "ParkBrakeReleaseMode2_Reserved6" 11 "ParkBrakeReleaseMode2_Reserved5" 10 "ParkBrakeReleaseMode2_Reserved4" 9 "ParkBrakeReleaseMode2_Reserved3" 8 "ParkBrakeReleaseMode2_VoluntarilyAtLowVehicleMode" 7 "ParkBrakeReleaseMode2_RedundantExternalDemand" 6 "ParkBrakeReleaseMode2_AutomaticallyinHillHolder" 5 "ParkBrakeReleaseMode2_AutomaticInBackup" 4 "ParkBrakeReleaseMode2_MainExternalDemand" 3 "ParkBrakeReleaseMode2_AutomaticallyAccelPedal" 2 "ParkBrakeReleaseMode2_ManuallyAtStandstill" 1 "ParkBrakeReleaseMode2_ManuallyInDriving" 0 "ParkBrakeReleaseMode2_Idle" ;
VAL_ 260 LowVMPBInfoReq 7 "LevelLow3bit_NotAvailable" 6 "LevelLow3bit_Error" 5 "LevelLow3bit_LowLevel5" 4 "LevelLow3bit_LowLevel4" 3 "LevelLow3bit_LowLevel3" 2 "LevelLow3bit_LowLevel2" 1 "LevelLow3bit_LowLevel1" 0 "LevelLow3bit_NoRequest" ;
VAL_ 260 ParkBrakeWorkshopMode_ISig_3 3 "ParkBrakeWorkshopMode_NotAvailable" 2 "ParkBrakeWorkshopMode_Error" 1 "ParkBrakeWorkshopMode_WorkshopMode" 0 "ParkBrakeWorkshopMode_NormalMode" ;
VAL_ 260 AirDryerCartridgeReset_ack 3 "NokOk_NotAvailable" 2 "NokOk_Error" 1 "NokOk_OK" 0 "NokOk_NOK" ;
VAL_ 256 XBRPB_Priority 3 "Priority_LowPriority" 2 "Priority_MediumPriority" 1 "Priority_HighPriority" 0 "Priority_HighestPriority" ;
VAL_ 256 ParkingBrake_stat_ISig_3 3 "ParkingBrake_stat_NotAvailable" 2 "ParkingBrake_stat_Error" 1 "ParkingBrake_stat_ParkingBrakeActivated" 0 "ParkingBrake_stat_ParkingBrakeReleased" ;
VAL_ 256 XBRPB_CompensationMode 3 "Disabled_Reserved_TakeNoAction" 2 "Disabled_Reserved_Reserved" 1 "Disabled_Reserved_Enabled" 0 "Disabled_Reserved_Disabled" ;
VAL_ 256 XBRPB_EBIMode 3 "XBREBIMode_NotDefined" 2 "XBREBIMode_EnduranceBrakeIntegrationAllowed" 1 "XBREBIMode_OnlyEnduranceBrakesAllowed" 0 "XBREBIMode_NoEnduranceBrakeIntegrationAllowed" ;
VAL_ 256 ParkBrakeActuationStatus_ISig_3 7 "ParkBrakeActuationStatus_NotAvailable" 6 "ParkBrakeActuationStatus_Error" 5 "ParkBrakeActuationStatus_SpareValue_01" 4 "ParkBrakeActuationStatus_SpareValue" 3 "ParkBrakeActuationStatus_AntiCompound" 2 "ParkBrakeActuationStatus_Parked" 1 "ParkBrakeActuationStatus_PartiallyParked" 0 "ParkBrakeActuationStatus_Released" ;
VAL_ 256 XBRPB_ControlMode 3 "XBRControlMode_NotDefined" 2 "XBRControlMode_AccelerationControlWithMaximumMode" 1 "XBRControlMode_AccelerationControlWithAdditionMode" 0 "XBRControlMode_OverrideDisabled" ;
SIG_GROUP_ 592 CpbtyAxle2_sg 1 : CpbtyAxle2_PadWearRi CpbtyAxle2_TqCpbtyMaxRi CpbtyAxle2_TqCpbtyMinLe CpbtyAxle2_BrkEgyCpctyQltyLe CpbtyAxle2_TqCpbtyRateDecLe CpbtyAxle2_TqCpbtyRateDecRi CpbtyAxle2_TqCpbtyMaxLe CpbtyAxle2_BrkEgyCpctyQltyRi CpbtyAxle2_PadWearLe CpbtyAxle2_TqCpbtyQltyRi CpbtyAxle2_PadWearQltyRi CpbtyAxle2_TqCpbtyRateQltyRi CpbtyAxle2_SlipCtrlEna CpbtyAxle2_TqCpbtyMinRi CpbtyAxle2_CRC CpbtyAxle2_SqC CpbtyAxle2_TqCpbtyRateIncLeLe CpbtyAxle2_TqCpbtyRateIncLeRi CpbtyAxle2_BrkEgyCpctyLe CpbtyAxle2_TqCpbtyQltyLe CpbtyAxle2_TqCpbtyRateQltyLe CpbtyAxle2_BrkEgyCpctyRi CpbtyAxle2_PadWearQltyLe;
SIG_GROUP_ 592 CpbtyAxle3_sg 1 : CpbtyAxle3_BrkEgyCpctyQltyLe CpbtyAxle3_TqCpbtyRateIncLeLe CpbtyAxle3_TqCpbtyRateQltyRi CpbtyAxle3_TqCpbtyRateQltyLe CpbtyAxle3_SlipCtrlEna CpbtyAxle3_TqCpbtyQltyLe CpbtyAxle3_BrkEgyCpctyRi CpbtyAxle3_BrkEgyCpctyQltyRi CpbtyAxle3_TqCpbtyRateDecLe CpbtyAxle3_TqCpbtyRateDecRi CpbtyAxle3_TqCpbtyQltyRi CpbtyAxle3_TqCpbtyMinLe CpbtyAxle3_TqCpbtyMinRi CpbtyAxle3_PadWearRi CpbtyAxle3_PadWearQltyRi CpbtyAxle3_TqCpbtyMaxLe CpbtyAxle3_TqCpbtyMaxRi CpbtyAxle3_PadWearQltyLe CpbtyAxle3_PadWearLe CpbtyAxle3_BrkEgyCpctyLe CpbtyAxle3_TqCpbtyRateIncLeRi CpbtyAxle3_CRC CpbtyAxle3_SqC;
SIG_GROUP_ 592 CpbtyAxle1_sg 1 : CpbtyAxle1_PadWearQltyLe CpbtyAxle1_SlipCtrlEna CpbtyAxle1_BrkEgyCpctyQltyRi CpbtyAxle1_SqC CpbtyAxle1_TqCpbtyQltyLe CpbtyAxle1_TqCpbtyRateIncLeLe CpbtyAxle1_PadWearRi CpbtyAxle1_TqCpbtyRateDecLe CpbtyAxle1_BrkEgyCpctyRi CpbtyAxle1_TqCpbtyMaxRi CpbtyAxle1_BrkEgyCpctyLe CpbtyAxle1_TqCpbtyRateIncLeRi CpbtyAxle1_TqCpbtyRateQltyRi CpbtyAxle1_CRC CpbtyAxle1_PadWearQltyRi CpbtyAxle1_TqCpbtyRateDecRi CpbtyAxle1_TqCpbtyRateQltyLe CpbtyAxle1_PadWearLe CpbtyAxle1_TqCpbtyMinRi CpbtyAxle1_TqCpbtyQltyRi CpbtyAxle1_TqCpbtyMinLe CpbtyAxle1_BrkEgyCpctyQltyLe CpbtyAxle1_TqCpbtyMaxLe;
SIG_GROUP_ 41 PLCMsgStat_sg_ISig_3 1 : PLCMsgStat_MsgErrCode_ISig_3 PLCMsgStat_TxRetryCnt_ISig_3 PLCMsgStat_TxArbtrnFailCnt_ISig_ PLCMsgStat_MsgStatus_ISig_3;
SIG_GROUP_ 832 WhlSpdSenTothCnt456_sg_ISig_3 1 : WhlSpdSenTothCnt456_TimeStamp_IS WhlSpdSenTothCnt456_Axle6Right_I WhlSpdSenTothCnt456_Axle5Left_IS WhlSpdSenTothCnt456_Axle4Right_I WhlSpdSenTothCnt456_Axle5Right_I WhlSpdSenTothCnt456_Axle4Left_IS WhlSpdSenTothCnt456_Axle6Left_IS;
SIG_GROUP_ 832 WhlSpdSenTothCnt123_sg_ISig_3 1 : WhlSpdSenTothCnt123_Axle2Left_IS WhlSpdSenTothCnt123_TimeStamp_IS WhlSpdSenTothCnt123_Axle3Left_IS WhlSpdSenTothCnt123_Axle1Right_I WhlSpdSenTothCnt123_Axle3Right_I WhlSpdSenTothCnt123_Axle2Right_I WhlSpdSenTothCnt123_Axle1Left_IS;
SIG_GROUP_ 439 CombinedWheelSpeed_sg 1 : CombinedWheelSpeed_CRC CombinedWheelSpeed_SqC CombinedWheelSpeed_Quality CombinedWheelSpeed_Speed;
SIG_GROUP_ 439 EACompound_sg 1 : EACompound_CRC EACompound_SystemState EACompound_AppliedRatio EACompound_SqC;
SIG_GROUP_ 439 TCMSupply_sg 1 : TCMSupply_SqC TCMSupply_CRC TCMSupply_TrailerPressure;
SIG_GROUP_ 315 SteeringWheel_sg 1 : SteeringWheel_AngleCRC SteeringWheel_AngleCounter SteeringWheel_AngleValue;
SIG_GROUP_ 1491 DiagFaultStat_FAS_sg 1 : DiagFaultStat_FAS_FailTA DiagFaultStat_FAS_EcuAdr DiagFaultStat_FAS_DtcIdA DiagFaultStat_FAS_DtcIdB DiagFaultStat_FAS_FailTB;
SIG_GROUP_ 1152 DiagFaultStat_APM_sg 1 : DiagFaultStat_APM_EcuAdr DiagFaultStat_APM_FailTB DiagFaultStat_APM_DtcIdB DiagFaultStat_APM_FailTA DiagFaultStat_APM_DtcIdA;
SIG_GROUP_ 640 PBAirLvl_sg 1 : PBAirLvl_SqC PBAirLvl_AntiCompoundRatio PBAirLvl_CRC PBAirLvl_PressureInChamber;
SIG_GROUP_ 640 TrailerStatus_sg_ISig_3 1 : TrailerStatus_IntegrityLvl_ISig_ TrailerStatus_CRC_ISig_3 TrailerStatus_Actuation_ISig_3 TrailerStatus_SqC_ISig_3;
SIG_GROUP_ 640 APMSafetyWarning_sg_ISig_3 1 : APMSafetyWarning_YellowRqst_ISig APMSafetyWarning_CRC_ISig_3 APMSafetyWarning_RedRqst_ISig_3 APMSafetyWarning_SqC_ISig_3;
SIG_GROUP_ 640 PBStatus_sg_ISig_3 1 : PBStatus_CRC_ISig_3 PBStatus_SqC_ISig_3 PBStatus_IntegrityLvl_ISig_3 PBStatus_Actuation_ISig_3;
SIG_GROUP_ 640 DynamicPB_sg 1 : DynamicPB_ActiveStatus DynamicPB_SqC DynamicPB_CRC;
SIG_GROUP_ 640 RedGladHand_sg_ISig_3 1 : RedGladHand_SqC_ISig_3 RedGladHand_ConnectStatus_ISig_3 RedGladHand_CRC_ISig_3 RedGladHand_ConfidenceLvl_ISig_3;
SIG_GROUP_ 386 XPRGSystemState_sg 1 : XPRGSystemState_AppliedPriority XPRGSystemState_CRC XPRGSystemState_SqC;
SIG_GROUP_ 386 RGHDetect_sg 1 : RGHDetect_CRC RGHDetect_SqC RGHDetect_ActiveProcess;
SIG_GROUP_ 386 XPRGSystemCap_sg_ISig_3 1 : XPRGSystemCap_SqC_ISig_3 XPRGSystemCap_AllowedGradCtrlTl_ XPRGSystemCap_AllowedGradCtrlTc_ XPRGSystemCap_AllowedRelInhibit_ XPRGSystemCap_Priority_ISig_3 XPRGSystemCap_AllowedPBApp_ISig_ XPRGSystemCap_AllowedPBRel_ISig_ XPRGSystemCap_AllowedDeflation_I XPRGSystemCap_AllowedInflation_I XPRGSystemCap_AllowedInfInhibit_ XPRGSystemCap_CRC_ISig_3;
SIG_GROUP_ 256 XBRPB_sg 1 : XBRPB_Priority XBRPB_CompensationMode XBRPB_EBIMode XBRPB_SqC XBRPB_CRC XBRPB_ExtAccelDemand XBRPB_ControlMode XBRPB_Urgency;
